NS_ :

BS_:

BU_: AWC BAP_Tester BMC_MLBevo BMS_MV BMS_NV DCDC_800V_PAG DCDC_HV DCDC_HV_02 DCDC_IHEV Gateway Gateway_PAG Ladegeraet_2 Ladegeraet_Konzern LE1 LE2 LE_MLBevo Sub_Gateway TME

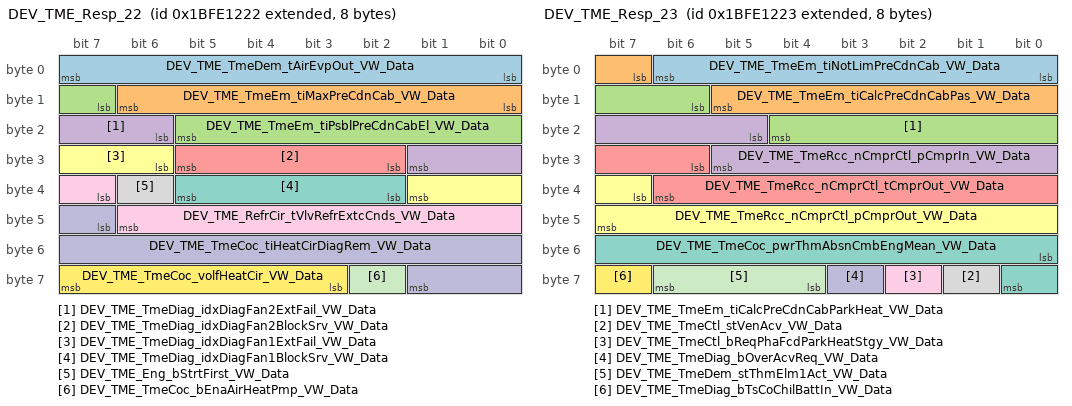
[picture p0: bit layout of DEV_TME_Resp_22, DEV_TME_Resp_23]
BO_ 2617119266 DEV_TME_Resp_22: 8 TME
 SG_ DEV_TME_TmeDem_tAirEvpOut_VW_Data : 0|8@1+ (0.8,-45) [-45|159] "" Vector__XXX
 SG_ DEV_TME_TmeEm_tiMaxPreCdnCab_VW_Data : 8|7@1+ (1,0) [0|120] "" Vector__XXX
 SG_ DEV_TME_TmeEm_tiPsblPreCdnCabEl_VW_Data : 15|7@1+ (1,0) [0|120] "" Vector__XXX
 SG_ DEV_TME_TmeDiag_idxDiagFan2ExtFail_VW_Data : 22|4@1+ (0.17,0) [0|2.55] "" Vector__XXX
 SG_ DEV_TME_TmeDiag_idxDiagFan2BlockSrv_VW_Data : 26|4@1+ (0.17,0) [0|2.55] "" Vector__XXX
 SG_ DEV_TME_TmeDiag_idxDiagFan1ExtFail_VW_Data : 30|4@1+ (0.17,0) [0|2.55] "" Vector__XXX
 SG_ DEV_TME_TmeDiag_idxDiagFan1BlockSrv_VW_Data : 34|4@1+ (0.17,0) [0|2.55] "" Vector__XXX
 SG_ DEV_TME_Eng_bStrtFirst_VW_Data : 38|1@1+ (1,0) [0|1] "" Vector__XXX
 SG_ DEV_TME_RefrCir_tVlvRefrExtcCnds_VW_Data : 39|8@1+ (0.8,-50) [-50|154] "" Vector__XXX
 SG_ DEV_TME_TmeCoc_tiHeatCirDiagRem_VW_Data : 47|11@1+ (1,0) [0|2047] "" Vector__XXX
 SG_ DEV_TME_TmeCoc_bEnaAirHeatPmp_VW_Data : 58|1@1+ (1,0) [0|1] "" Vector__XXX
 SG_ DEV_TME_TmeCoc_volfHeatCir_VW_Data : 59|5@1+ (0.5,0) [0|15.5] "" Vector__XXX

BO_ 2617119267 DEV_TME_Resp_23: 8 TME
 SG_ DEV_TME_TmeEm_tiNotLimPreCdnCab_VW_Data : 0|7@1+ (1,0) [0|120] "" Vector__XXX
 SG_ DEV_TME_TmeEm_tiCalcPreCdnCabPas_VW_Data : 7|7@1+ (1,0) [0|120] "" Vector__XXX
 SG_ DEV_TME_TmeEm_tiCalcPreCdnCabParkHeat_VW_Data : 14|7@1+ (1,0) [0|120] "" Vector__XXX
 SG_ DEV_TME_TmeRcc_nCmprCtl_pCmprIn_VW_Data : 21|9@1+ (32,0) [0|9000] "" Vector__XXX
 SG_ DEV_TME_TmeRcc_nCmprCtl_tCmprOut_VW_Data : 30|9@1+ (32,0) [0|9000] "" Vector__XXX
 SG_ DEV_TME_TmeRcc_nCmprCtl_pCmprOut_VW_Data : 39|9@1+ (32,0) [0|9000] "" Vector__XXX
 SG_ DEV_TME_TmeCoc_pwrThmAbsnCmbEngMean_VW_Data : 48|9@1+ (32,0) [0|16352] "" Vector__XXX
 SG_ DEV_TME_TmeCtl_stVenAcv_VW_Data : 57|1@1+ (1,0) [0|1] "" Vector__XXX
 SG_ DEV_TME_TmeCtl_bReqPhaFcdParkHeatStgy_VW_Data : 58|1@1+ (1,0) [0|1] "" Vector__XXX
 SG_ DEV_TME_TmeDiag_bOverAcvReq_VW_Data : 59|1@1+ (1,0) [0|1] "" Vector__XXX
 SG_ DEV_TME_TmeDem_stThmElm1Act_VW_Data : 60|3@1+ (1,0) [0|7] "" Vector__XXX
 SG_ DEV_TME_TmeDiag_bTsCoChilBattIn_VW_Data : 63|1@1+ (1,0) [0|1] "" Vector__XXX

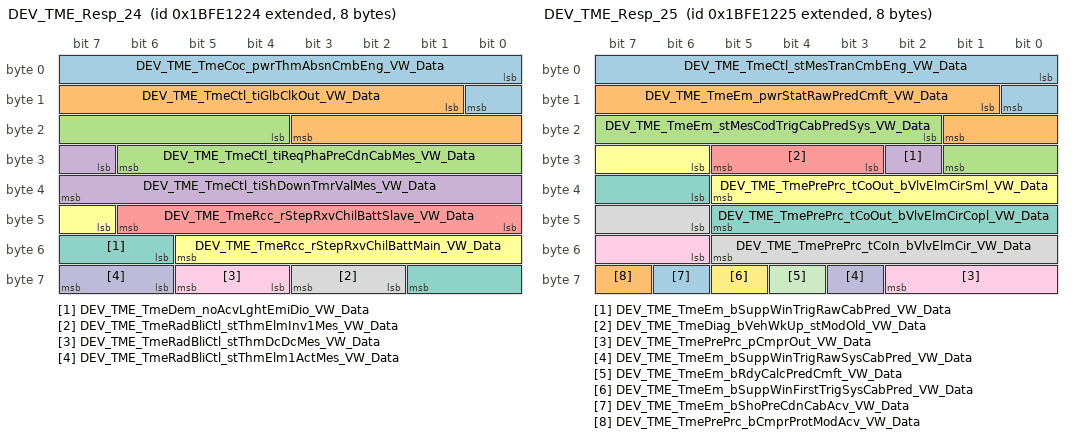
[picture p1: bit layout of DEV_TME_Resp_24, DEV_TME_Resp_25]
BO_ 2617119268 DEV_TME_Resp_24: 8 TME
 SG_ DEV_TME_TmeCoc_pwrThmAbsnCmbEng_VW_Data : 0|9@1+ (32,0) [0|16352] "" Vector__XXX
 SG_ DEV_TME_TmeCtl_tiGlbClkOut_VW_Data : 9|11@1+ (8,0) [0|16376] "" Vector__XXX
 SG_ DEV_TME_TmeCtl_tiReqPhaPreCdnCabMes_VW_Data : 20|11@1+ (8,0) [0|16376] "" Vector__XXX
 SG_ DEV_TME_TmeCtl_tiShDownTmrValMes_VW_Data : 31|9@1+ (8,0) [0|4088] "" Vector__XXX
 SG_ DEV_TME_TmeRcc_rStepRxvChilBattSlave_VW_Data : 40|7@1+ (0.8,0) [0|100] "" Vector__XXX
 SG_ DEV_TME_TmeRcc_rStepRxvChilBattMain_VW_Data : 47|7@1+ (0.8,0) [0|100] "" Vector__XXX
 SG_ DEV_TME_TmeDem_noAcvLghtEmiDio_VW_Data : 54|4@1+ (1,0) [0|8] "" Vector__XXX
 SG_ DEV_TME_TmeRadBliCtl_stThmElmInv1Mes_VW_Data : 58|2@1+ (1,0) [0|3] "" Vector__XXX
 SG_ DEV_TME_TmeRadBliCtl_stThmDcDcMes_VW_Data : 60|2@1+ (1,0) [0|3] "" Vector__XXX
 SG_ DEV_TME_TmeRadBliCtl_stThmElm1ActMes_VW_Data : 62|2@1+ (1,0) [0|3] "" Vector__XXX

BO_ 2617119269 DEV_TME_Resp_25: 8 TME
 SG_ DEV_TME_TmeCtl_stMesTranCmbEng_VW_Data : 0|9@1+ (1,0) [0|511] "" Vector__XXX
 SG_ DEV_TME_TmeEm_pwrStatRawPredCmft_VW_Data : 9|9@1+ (32,0) [0|16352] "" Vector__XXX
 SG_ DEV_TME_TmeEm_stMesCodTrigCabPredSys_VW_Data : 18|8@1+ (1,0) [0|255] "" Vector__XXX
 SG_ DEV_TME_TmeEm_bSuppWinTrigRawCabPred_VW_Data : 26|1@1+ (1,0) [0|1] "" Vector__XXX
 SG_ DEV_TME_TmeDiag_bVehWkUp_stModOld_VW_Data : 27|3@1+ (1,0) [0|7] "" Vector__XXX
 SG_ DEV_TME_TmePrePrc_tCoOut_bVlvElmCirSml_VW_Data : 30|8@1+ (1,-40) [-40|215] "" Vector__XXX
 SG_ DEV_TME_TmePrePrc_tCoOut_bVlvElmCirCopl_VW_Data : 38|8@1+ (1,-40) [-40|215] "" Vector__XXX
 SG_ DEV_TME_TmePrePrc_tCoIn_bVlvElmCir_VW_Data : 46|8@1+ (1,-40) [-40|215] "" Vector__XXX
 SG_ DEV_TME_TmePrePrc_pCmprOut_VW_Data : 54|5@1+ (1,0) [0|31] "" Vector__XXX
 SG_ DEV_TME_TmeEm_bSuppWinTrigRawSysCabPred_VW_Data : 59|1@1+ (1,0) [0|1] "" Vector__XXX
 SG_ DEV_TME_TmeEm_bRdyCalcPredCmft_VW_Data : 60|1@1+ (1,0) [0|1] "" Vector__XXX
 SG_ DEV_TME_TmeEm_bSuppWinFirstTrigSysCabPred_VW_Data : 61|1@1+ (1,0) [0|1] "" Vector__XXX
 SG_ DEV_TME_TmeEm_bShoPreCdnCabAcv_VW_Data : 62|1@1+ (1,0) [0|1] "" Vector__XXX
 SG_ DEV_TME_TmePrePrc_bCmprProtModAcv_VW_Data : 63|1@1+ (1,0) [0|1] "" Vector__XXX

BO_ 2617119270 DEV_TME_Resp_26: 8 TME
 SG_ DEV_TME_TmeEcu_stCodPar5_VW_Data : 0|32@1+ (1,0) [0|4294967295] "" Vector__XXX
 SG_ DEV_TME_TmeEcu_stCodPar4_VW_Data : 32|32@1+ (1,0) [0|4294967295] "" Vector__XXX

BO_ 2617119271 DEV_TME_Resp_27: 8 TME
 SG_ DEV_TME_TmeEcu_stCodPar1_VW_Data : 0|32@1+ (1,0) [0|4294967295] "" Vector__XXX
 SG_ DEV_TME_TmeEcu_stCodPar2_VW_Data : 32|32@1+ (1,0) [0|4294967295] "" Vector__XXX

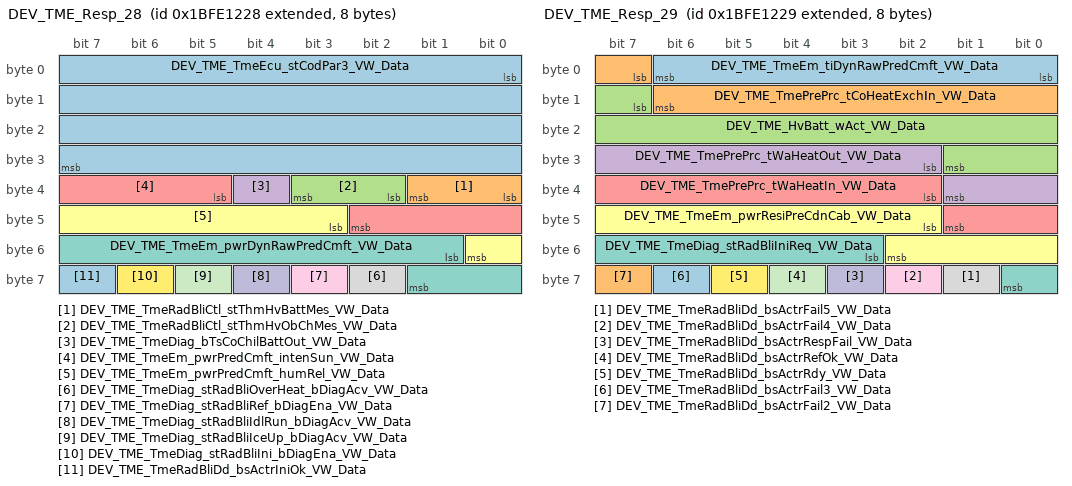
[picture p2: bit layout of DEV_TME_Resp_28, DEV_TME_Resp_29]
BO_ 2617119272 DEV_TME_Resp_28: 8 TME
 SG_ DEV_TME_TmeEcu_stCodPar3_VW_Data : 0|32@1+ (1,0) [0|4294967295] "" Vector__XXX
 SG_ DEV_TME_TmeRadBliCtl_stThmHvBattMes_VW_Data : 32|2@1+ (1,0) [0|3] "" Vector__XXX
 SG_ DEV_TME_TmeRadBliCtl_stThmHvObChMes_VW_Data : 34|2@1+ (1,0) [0|3] "" Vector__XXX
 SG_ DEV_TME_TmeDiag_bTsCoChilBattOut_VW_Data : 36|1@1+ (1,0) [0|1] "" Vector__XXX
 SG_ DEV_TME_TmeEm_pwrPredCmft_intenSun_VW_Data : 37|6@1+ (100,-3200) [-3200|3100] "" Vector__XXX
 SG_ DEV_TME_TmeEm_pwrPredCmft_humRel_VW_Data : 43|6@1+ (100,-3200) [-3200|3100] "" Vector__XXX
 SG_ DEV_TME_TmeEm_pwrDynRawPredCmft_VW_Data : 49|9@1+ (32,0) [0|16352] "" Vector__XXX
 SG_ DEV_TME_TmeDiag_stRadBliOverHeat_bDiagAcv_VW_Data : 58|1@1+ (1,0) [0|1] "" Vector__XXX
 SG_ DEV_TME_TmeDiag_stRadBliRef_bDiagEna_VW_Data : 59|1@1+ (1,0) [0|1] "" Vector__XXX
 SG_ DEV_TME_TmeDiag_stRadBliIdlRun_bDiagAcv_VW_Data : 60|1@1+ (1,0) [0|1] "" Vector__XXX
 SG_ DEV_TME_TmeDiag_stRadBliIceUp_bDiagAcv_VW_Data : 61|1@1+ (1,0) [0|1] "" Vector__XXX
 SG_ DEV_TME_TmeDiag_stRadBliIni_bDiagEna_VW_Data : 62|1@1+ (1,0) [0|1] "" Vector__XXX
 SG_ DEV_TME_TmeRadBliDd_bsActrIniOk_VW_Data : 63|1@1+ (1,0) [0|1] "" Vector__XXX

BO_ 2617119273 DEV_TME_Resp_29: 8 TME
 SG_ DEV_TME_TmeEm_tiDynRawPredCmft_VW_Data : 0|7@1+ (1,0) [0|120] "" Vector__XXX
 SG_ DEV_TME_TmePrePrc_tCoHeatExchIn_VW_Data : 7|8@1+ (1,-40) [-40|215] "" Vector__XXX
 SG_ DEV_TME_HvBatt_wAct_VW_Data : 15|11@1+ (50,0) [0|51200] "" Vector__XXX
 SG_ DEV_TME_TmePrePrc_tWaHeatOut_VW_Data : 26|8@1+ (1,-40) [-40|215] "" Vector__XXX
 SG_ DEV_TME_TmePrePrc_tWaHeatIn_VW_Data : 34|8@1+ (1,-40) [-40|215] "" Vector__XXX
 SG_ DEV_TME_TmeEm_pwrResiPreCdnCab_VW_Data : 42|9@1+ (32,0) [0|16352] "" Vector__XXX
 SG_ DEV_TME_TmeDiag_stRadBliIniReq_VW_Data : 51|6@1+ (1,0) [0|32] "" Vector__XXX
 SG_ DEV_TME_TmeRadBliDd_bsActrFail5_VW_Data : 57|1@1+ (1,0) [0|1] "" Vector__XXX
 SG_ DEV_TME_TmeRadBliDd_bsActrFail4_VW_Data : 58|1@1+ (1,0) [0|1] "" Vector__XXX
 SG_ DEV_TME_TmeRadBliDd_bsActrRespFail_VW_Data : 59|1@1+ (1,0) [0|1] "" Vector__XXX
 SG_ DEV_TME_TmeRadBliDd_bsActrRefOk_VW_Data : 60|1@1+ (1,0) [0|1] "" Vector__XXX
 SG_ DEV_TME_TmeRadBliDd_bsActrRdy_VW_Data : 61|1@1+ (1,0) [0|1] "" Vector__XXX
 SG_ DEV_TME_TmeRadBliDd_bsActrFail3_VW_Data : 62|1@1+ (1,0) [0|1] "" Vector__XXX
 SG_ DEV_TME_TmeRadBliDd_bsActrFail2_VW_Data : 63|1@1+ (1,0) [0|1] "" Vector__XXX

BO_ 2617119274 DEV_TME_Resp_2A: 8 TME
 SG_ DEV_TME_TmeRadBliDd_bsActrFail1_VW_Data : 0|1@1+ (1,0) [0|1] "" Vector__XXX
 SG_ DEV_TME_TmeRadBliDd_rRadBliSet1_VW_Data : 1|7@1+ (1,0) [0|127] "" Vector__XXX
 SG_ DEV_TME_TmeRadBliDd_rRadBliAct1_VW_Data : 8|7@1+ (1,0) [0|127] "" Vector__XXX
 SG_ DEV_TME_TmeDiag_stRadBliSpd2_bDiagAcv_VW_Data : 15|1@1+ (1,0) [0|1] "" Vector__XXX
 SG_ DEV_TME_TmeDiag_stRadBliRefReq_VW_Data : 16|6@1+ (1,0) [0|32] "" Vector__XXX
 SG_ DEV_TME_TmeDiag_stRadBliSpd1_bDiagAcv_VW_Data : 22|1@1+ (1,0) [0|1] "" Vector__XXX
 SG_ DEV_TME_TmeDiag_stRadBliBlock_bDiagAcv_VW_Data : 23|1@1+ (1,0) [0|1] "" Vector__XXX
 SG_ DEV_TME_TmeDiag_stRadBliBlock_bDiagEna_VW_Data : 24|1@1+ (1,0) [0|1] "" Vector__XXX
 SG_ DEV_TME_TmeDiag_stRadBliHealRun_b1FailVld_VW_Data : 25|1@1+ (1,0) [0|1] "" Vector__XXX
 SG_ DEV_TME_TmeDiag_stRadBliHealRun_b1FailSusp_VW_Data : 26|1@1+ (1,0) [0|1] "" Vector__XXX
 SG_ DEV_TME_TmeDiag_stRadBliAlv_bDiagEna_VW_Data : 27|1@1+ (1,0) [0|1] "" Vector__XXX
 SG_ DEV_TME_TmeDiag_stRadBliHealRun_bRef1FailSusp_VW_Data : 28|1@1+ (1,0) [0|1] "" Vector__XXX
 SG_ DEV_TME_Eng_bHotLmp_VW_Data : 29|1@1+ (1,0) [0|1] "" Vector__XXX
 SG_ DEV_TME_TmeDiag_stRadBliHealRun_ct_VW_Data : 30|4@1+ (1,0) [0|10] "" Vector__XXX
 SG_ DEV_TME_TmeDiag_stRadBliHealRun_b1RefFailVld_VW_Data : 34|1@1+ (1,0) [0|1] "" Vector__XXX
 SG_ DEV_TME_TmeRadBliCtl_stThmElm1RtMes_VW_Data : 35|2@1+ (1,0) [0|3] "" Vector__XXX
 SG_ DEV_TME_TmeEm_pwrDeltaThdSysHld_VW_Data : 37|7@1+ (100,0) [0|12700] "" Vector__XXX
 SG_ DEV_TME_TmeEm_pwrStatPredCmftFilHld_VW_Data : 44|7@1+ (100,0) [0|12700] "" Vector__XXX
 SG_ DEV_TME_TmeEm_pwrStatPredCmftFilSysHld_VW_Data : 51|7@1+ (100,0) [0|12700] "" Vector__XXX
 SG_ DEV_TME_TmeDiag_bHvBattModAcv_VW_Data : 58|1@1+ (1,0) [0|1] "" Vector__XXX
 SG_ DEV_TME_TmeDiag_idxDiagTsHeatExchIn_VW_Data : 59|4@1+ (17,0) [0|2.55] "" Vector__XXX
 SG_ DEV_TME_TmeEm_bSigVldPreCdnCabMes_VW_Data : 63|1@1+ (1,0) [0|1] "" Vector__XXX

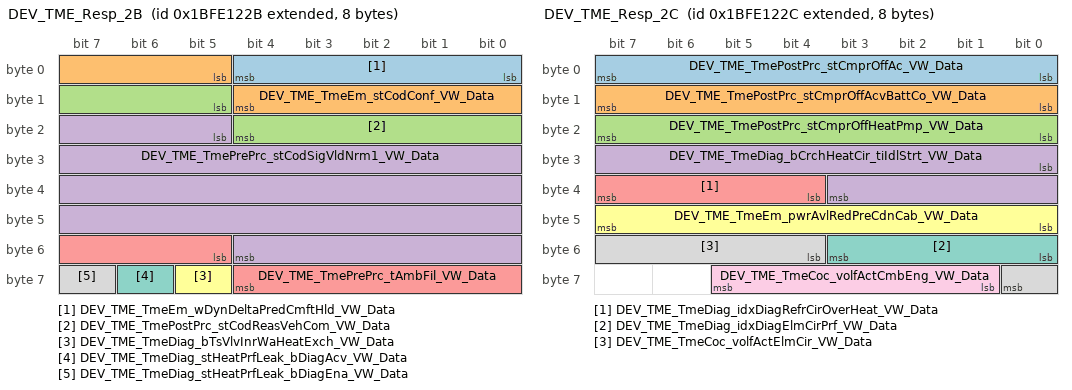
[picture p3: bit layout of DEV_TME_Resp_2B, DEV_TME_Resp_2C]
BO_ 2617119275 DEV_TME_Resp_2B: 8 TME
 SG_ DEV_TME_TmeEm_wDynDeltaPredCmftHld_VW_Data : 0|5@1+ (200,0) [0|6000] "" Vector__XXX
 SG_ DEV_TME_TmeEm_stCodConf_VW_Data : 5|8@1+ (1,0) [0|255] "" Vector__XXX
 SG_ DEV_TME_TmePostPrc_stCodReasVehCom_VW_Data : 13|8@1+ (1,0) [0|255] "" Vector__XXX
 SG_ DEV_TME_TmePrePrc_stCodSigVldNrm1_VW_Data : 21|32@1+ (1,0) [0|4294967295] "" Vector__XXX
 SG_ DEV_TME_TmePrePrc_tAmbFil_VW_Data : 53|8@1+ (1,-40) [-40|215] "" Vector__XXX
 SG_ DEV_TME_TmeDiag_bTsVlvInrWaHeatExch_VW_Data : 61|1@1+ (1,0) [0|1] "" Vector__XXX
 SG_ DEV_TME_TmeDiag_stHeatPrfLeak_bDiagAcv_VW_Data : 62|1@1+ (1,0) [0|1] "" Vector__XXX
 SG_ DEV_TME_TmeDiag_stHeatPrfLeak_bDiagEna_VW_Data : 63|1@1+ (1,0) [0|1] "" Vector__XXX

BO_ 2617119276 DEV_TME_Resp_2C: 8 TME
 SG_ DEV_TME_TmePostPrc_stCmprOffAc_VW_Data : 0|8@1+ (1,0) [0|255] "" Vector__XXX
 SG_ DEV_TME_TmePostPrc_stCmprOffAcvBattCo_VW_Data : 8|8@1+ (1,0) [0|255] "" Vector__XXX
 SG_ DEV_TME_TmePostPrc_stCmprOffHeatPmp_VW_Data : 16|8@1+ (1,0) [0|255] "" Vector__XXX
 SG_ DEV_TME_TmeDiag_bCrchHeatCir_tiIdlStrt_VW_Data : 24|12@1+ (1,0) [0|3000] "" Vector__XXX
 SG_ DEV_TME_TmeDiag_idxDiagRefrCirOverHeat_VW_Data : 36|4@1+ (17,0) [0|2.55] "" Vector__XXX
 SG_ DEV_TME_TmeEm_pwrAvlRedPreCdnCab_VW_Data : 40|8@1+ (50,0) [0|12750] "" Vector__XXX
 SG_ DEV_TME_TmeDiag_idxDiagElmCirPrf_VW_Data : 48|4@1+ (0.17,0) [0|2.55] "" Vector__XXX
 SG_ DEV_TME_TmeCoc_volfActElmCir_VW_Data : 52|5@1+ (0.5,0) [0|15.5] "" Vector__XXX
 SG_ DEV_TME_TmeCoc_volfActCmbEng_VW_Data : 57|5@1+ (0.5,0) [0|15.5] "" Vector__XXX

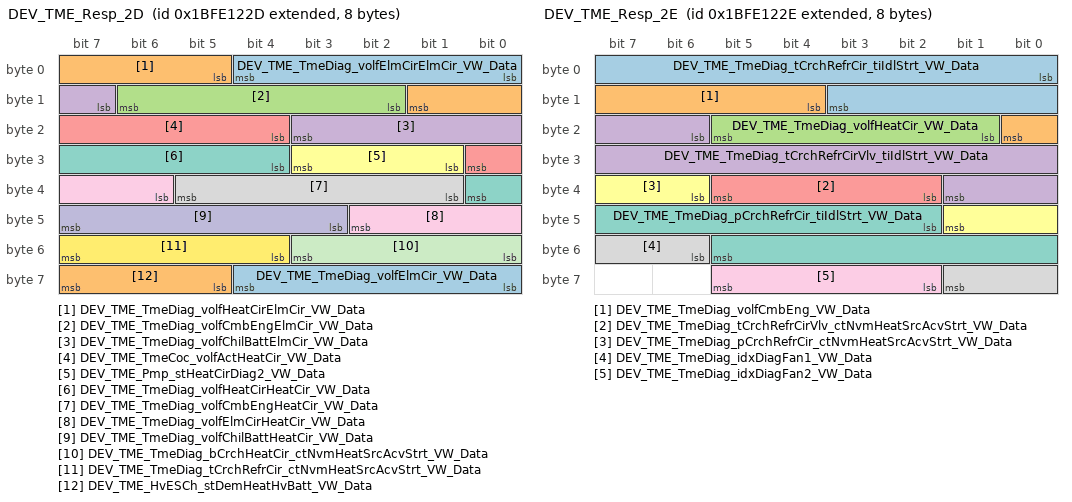
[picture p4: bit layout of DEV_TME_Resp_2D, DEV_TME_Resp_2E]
BO_ 2617119277 DEV_TME_Resp_2D: 8 TME
 SG_ DEV_TME_TmeDiag_volfElmCirElmCir_VW_Data : 0|5@1+ (0.5,0) [0|15.5] "" Vector__XXX
 SG_ DEV_TME_TmeDiag_volfHeatCirElmCir_VW_Data : 5|5@1+ (0.5,0) [0|15.5] "" Vector__XXX
 SG_ DEV_TME_TmeDiag_volfCmbEngElmCir_VW_Data : 10|5@1+ (0.5,0) [0|15.5] "" Vector__XXX
 SG_ DEV_TME_TmeDiag_volfChilBattElmCir_VW_Data : 15|5@1+ (0.5,0) [0|15.5] "" Vector__XXX
 SG_ DEV_TME_TmeCoc_volfActHeatCir_VW_Data : 20|5@1+ (0.5,0) [0|15.5] "" Vector__XXX
 SG_ DEV_TME_Pmp_stHeatCirDiag2_VW_Data : 25|3@1+ (1,0) [0|7] "" Vector__XXX
 SG_ DEV_TME_TmeDiag_volfHeatCirHeatCir_VW_Data : 28|5@1+ (0.5,0) [0|15.5] "" Vector__XXX
 SG_ DEV_TME_TmeDiag_volfCmbEngHeatCir_VW_Data : 33|5@1+ (0.5,0) [0|15.5] "" Vector__XXX
 SG_ DEV_TME_TmeDiag_volfElmCirHeatCir_VW_Data : 38|5@1+ (0.5,0) [0|15.5] "" Vector__XXX
 SG_ DEV_TME_TmeDiag_volfChilBattHeatCir_VW_Data : 43|5@1+ (0.5,0) [0|15.5] "" Vector__XXX
 SG_ DEV_TME_TmeDiag_bCrchHeatCir_ctNvmHeatSrcAcvStrt_VW_Data : 48|4@1+ (1,0) [0|10] "" Vector__XXX
 SG_ DEV_TME_TmeDiag_tCrchRefrCir_ctNvmHeatSrcAcvStrt_VW_Data : 52|4@1+ (1,0) [0|10] "" Vector__XXX
 SG_ DEV_TME_TmeDiag_volfElmCir_VW_Data : 56|5@1+ (0.5,0) [0|15.5] "" Vector__XXX
 SG_ DEV_TME_HvESCh_stDemHeatHvBatt_VW_Data : 61|3@1+ (1,0) [0|7] "" Vector__XXX

BO_ 2617119278 DEV_TME_Resp_2E: 8 TME
 SG_ DEV_TME_TmeDiag_tCrchRefrCir_tiIdlStrt_VW_Data : 0|12@1+ (1,0) [0|3000] "" Vector__XXX
 SG_ DEV_TME_TmeDiag_volfCmbEng_VW_Data : 12|5@1+ (0.5,0) [0|15.5] "" Vector__XXX
 SG_ DEV_TME_TmeDiag_volfHeatCir_VW_Data : 17|5@1+ (0.5,0) [0|15.5] "" Vector__XXX
 SG_ DEV_TME_TmeDiag_tCrchRefrCirVlv_tiIdlStrt_VW_Data : 22|12@1+ (1,0) [0|3000] "" Vector__XXX
 SG_ DEV_TME_TmeDiag_tCrchRefrCirVlv_ctNvmHeatSrcAcvStrt_VW_Data : 34|4@1+ (1,0) [0|10] "" Vector__XXX
 SG_ DEV_TME_TmeDiag_pCrchRefrCir_ctNvmHeatSrcAcvStrt_VW_Data : 38|4@1+ (1,0) [0|10] "" Vector__XXX
 SG_ DEV_TME_TmeDiag_pCrchRefrCir_tiIdlStrt_VW_Data : 42|12@1+ (1,0) [0|3000] "" Vector__XXX
 SG_ DEV_TME_TmeDiag_idxDiagFan1_VW_Data : 54|4@1+ (0.17,0) [0|2.55] "" Vector__XXX
 SG_ DEV_TME_TmeDiag_idxDiagFan2_VW_Data : 58|4@1+ (0.17,0) [0|2.55] "" Vector__XXX

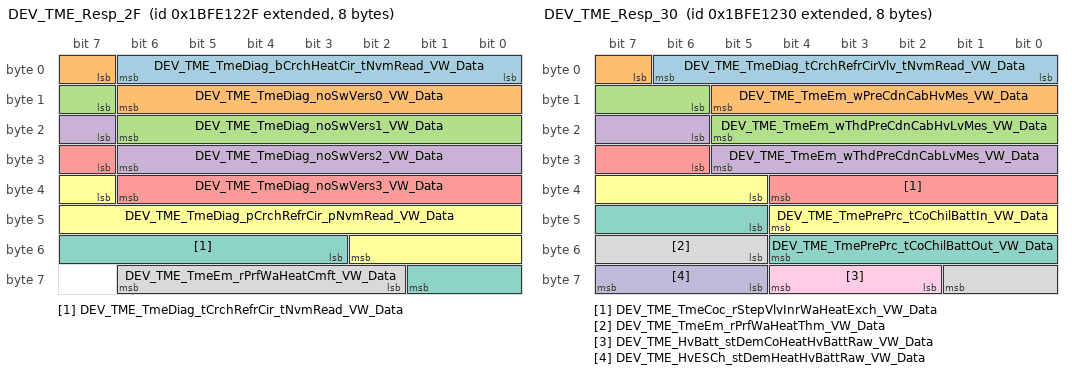
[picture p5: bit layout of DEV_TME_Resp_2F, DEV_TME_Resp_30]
BO_ 2617119279 DEV_TME_Resp_2F: 8 TME
 SG_ DEV_TME_TmeDiag_bCrchHeatCir_tNvmRead_VW_Data : 0|7@1+ (1,0) [0|127] "" Vector__XXX
 SG_ DEV_TME_TmeDiag_noSwVers0_VW_Data : 7|8@1+ (1,0) [0|255] "" Vector__XXX
 SG_ DEV_TME_TmeDiag_noSwVers1_VW_Data : 15|8@1+ (1,0) [0|255] "" Vector__XXX
 SG_ DEV_TME_TmeDiag_noSwVers2_VW_Data : 23|8@1+ (1,0) [0|255] "" Vector__XXX
 SG_ DEV_TME_TmeDiag_noSwVers3_VW_Data : 31|8@1+ (1,0) [0|255] "" Vector__XXX
 SG_ DEV_TME_TmeDiag_pCrchRefrCir_pNvmRead_VW_Data : 39|12@1+ (0.015625,0) [0|40] "" Vector__XXX
 SG_ DEV_TME_TmeDiag_tCrchRefrCir_tNvmRead_VW_Data : 51|7@1+ (1,0) [0|127] "" Vector__XXX
 SG_ DEV_TME_TmeEm_rPrfWaHeatCmft_VW_Data : 58|5@1+ (0.05,0) [0|1] "" Vector__XXX

BO_ 2617119280 DEV_TME_Resp_30: 8 TME
 SG_ DEV_TME_TmeDiag_tCrchRefrCirVlv_tNvmRead_VW_Data : 0|7@1+ (1,0) [0|127] "" Vector__XXX
 SG_ DEV_TME_TmeEm_wPreCdnCabHvMes_VW_Data : 7|7@1+ (10,0) [0|1000] "" Vector__XXX
 SG_ DEV_TME_TmeEm_wThdPreCdnCabHvLvMes_VW_Data : 14|8@1+ (10,0) [0|2000] "" Vector__XXX
 SG_ DEV_TME_TmeEm_wThdPreCdnCabLvMes_VW_Data : 22|8@1+ (10,0) [0|2000] "" Vector__XXX
 SG_ DEV_TME_TmeCoc_rStepVlvInrWaHeatExch_VW_Data : 30|7@1+ (1,0) [0|100] "" Vector__XXX
 SG_ DEV_TME_TmePrePrc_tCoChilBattIn_VW_Data : 37|8@1+ (1,-40) [-40|215] "" Vector__XXX
 SG_ DEV_TME_TmePrePrc_tCoChilBattOut_VW_Data : 45|8@1+ (1,-40) [-40|215] "" Vector__XXX
 SG_ DEV_TME_TmeEm_rPrfWaHeatThm_VW_Data : 53|5@1+ (0.05,0) [0|1] "" Vector__XXX
 SG_ DEV_TME_HvBatt_stDemCoHeatHvBattRaw_VW_Data : 58|3@1+ (1,0) [0|7] "" Vector__XXX
 SG_ DEV_TME_HvESCh_stDemHeatHvBattRaw_VW_Data : 61|3@1+ (1,0) [0|7] "" Vector__XXX

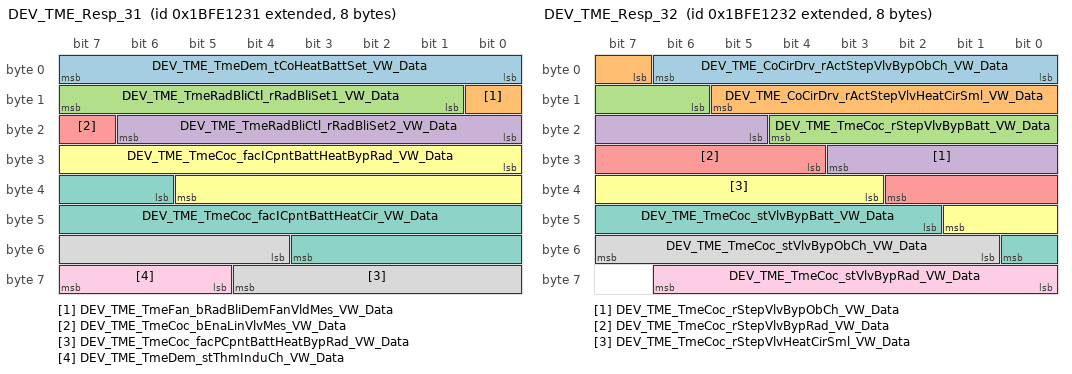
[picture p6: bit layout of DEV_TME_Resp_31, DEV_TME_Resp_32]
BO_ 2617119281 DEV_TME_Resp_31: 8 TME
 SG_ DEV_TME_TmeDem_tCoHeatBattSet_VW_Data : 0|8@1+ (0.8,-50) [-50|154] "" Vector__XXX
 SG_ DEV_TME_TmeFan_bRadBliDemFanVldMes_VW_Data : 8|1@1+ (1,0) [0|1] "" Vector__XXX
 SG_ DEV_TME_TmeRadBliCtl_rRadBliSet1_VW_Data : 9|7@1+ (1,0) [0|100] "" Vector__XXX
 SG_ DEV_TME_TmeRadBliCtl_rRadBliSet2_VW_Data : 16|7@1+ (1,0) [0|100] "" Vector__XXX
 SG_ DEV_TME_TmeCoc_bEnaLinVlvMes_VW_Data : 23|1@1+ (1,0) [0|1] "" Vector__XXX
 SG_ DEV_TME_TmeCoc_facICpntBattHeatBypRad_VW_Data : 24|14@1+ (0.0001,0) [0|0.1] "" Vector__XXX
 SG_ DEV_TME_TmeCoc_facICpntBattHeatCir_VW_Data : 38|14@1+ (0.0001,0) [0|0.1] "" Vector__XXX
 SG_ DEV_TME_TmeCoc_facPCpntBattHeatBypRad_VW_Data : 52|9@1+ (0.01,0) [0|2] "" Vector__XXX
 SG_ DEV_TME_TmeDem_stThmInduCh_VW_Data : 61|3@1+ (1,0) [0|4] "" Vector__XXX

BO_ 2617119282 DEV_TME_Resp_32: 8 TME
 SG_ DEV_TME_CoCirDrv_rActStepVlvBypObCh_VW_Data : 0|7@1+ (1,0) [0|100] "" Vector__XXX
 SG_ DEV_TME_CoCirDrv_rActStepVlvHeatCirSml_VW_Data : 7|7@1+ (1,0) [0|100] "" Vector__XXX
 SG_ DEV_TME_TmeCoc_rStepVlvBypBatt_VW_Data : 14|7@1+ (1,0) [0|100] "" Vector__XXX
 SG_ DEV_TME_TmeCoc_rStepVlvBypObCh_VW_Data : 21|7@1+ (1,0) [0|100] "" Vector__XXX
 SG_ DEV_TME_TmeCoc_rStepVlvBypRad_VW_Data : 28|7@1+ (1,0) [0|100] "" Vector__XXX
 SG_ DEV_TME_TmeCoc_rStepVlvHeatCirSml_VW_Data : 35|7@1+ (1,0) [0|100] "" Vector__XXX
 SG_ DEV_TME_TmeCoc_stVlvBypBatt_VW_Data : 42|7@1+ (1,0) [0|127] "" Vector__XXX
 SG_ DEV_TME_TmeCoc_stVlvBypObCh_VW_Data : 49|7@1+ (1,0) [0|127] "" Vector__XXX
 SG_ DEV_TME_TmeCoc_stVlvBypRad_VW_Data : 56|7@1+ (1,0) [0|127] "" Vector__XXX

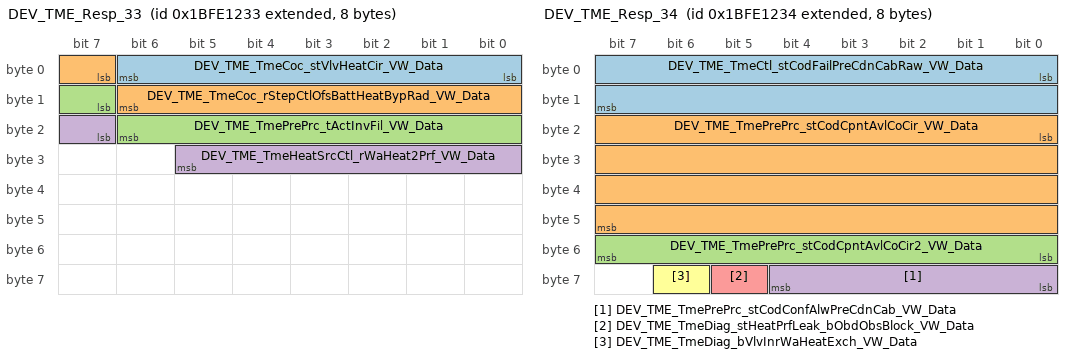
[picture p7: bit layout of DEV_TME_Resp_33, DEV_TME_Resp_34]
BO_ 2617119283 DEV_TME_Resp_33: 8 TME
 SG_ DEV_TME_TmeCoc_stVlvHeatCir_VW_Data : 0|7@1+ (1,0) [0|127] "" Vector__XXX
 SG_ DEV_TME_TmeCoc_rStepCtlOfsBattHeatBypRad_VW_Data : 7|8@1+ (1,-100) [-100|100] "" Vector__XXX
 SG_ DEV_TME_TmePrePrc_tActInvFil_VW_Data : 15|8@1+ (0.8,-45) [-45|159] "" Vector__XXX
 SG_ DEV_TME_TmeHeatSrcCtl_rWaHeat2Prf_VW_Data : 23|7@1+ (1,0) [0|100] "" Vector__XXX

BO_ 2617119284 DEV_TME_Resp_34: 8 TME
 SG_ DEV_TME_TmeCtl_stCodFailPreCdnCabRaw_VW_Data : 0|16@1+ (1,0) [0|65535] "" Vector__XXX
 SG_ DEV_TME_TmePrePrc_stCodCpntAvlCoCir_VW_Data : 16|32@1+ (1,0) [0|4294967295] "" Vector__XXX
 SG_ DEV_TME_TmePrePrc_stCodCpntAvlCoCir2_VW_Data : 48|8@1+ (1,0) [0|255] "" Vector__XXX
 SG_ DEV_TME_TmePrePrc_stCodConfAlwPreCdnCab_VW_Data : 56|5@1+ (1,0) [0|31] "" Vector__XXX
 SG_ DEV_TME_TmeDiag_stHeatPrfLeak_bObdObsBlock_VW_Data : 61|1@1+ (1,0) [0|1] "" Vector__XXX
 SG_ DEV_TME_TmeDiag_bVlvInrWaHeatExch_VW_Data : 62|1@1+ (1,0) [0|1] "" Vector__XXX

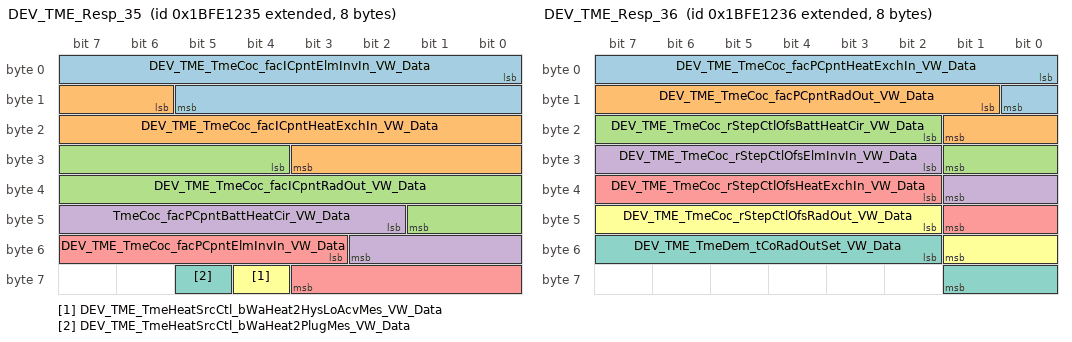
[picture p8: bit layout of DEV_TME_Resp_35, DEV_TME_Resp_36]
BO_ 2617119285 DEV_TME_Resp_35: 8 TME
 SG_ DEV_TME_TmeCoc_facICpntElmInvIn_VW_Data : 0|14@1+ (0.0001,0) [0|0.1] "" Vector__XXX
 SG_ DEV_TME_TmeCoc_facICpntHeatExchIn_VW_Data : 14|14@1+ (0.0001,0) [0|0.1] "" Vector__XXX
 SG_ DEV_TME_TmeCoc_facICpntRadOut_VW_Data : 28|14@1+ (0.0001,0) [0|0.1] "" Vector__XXX
 SG_ TmeCoc_facPCpntBattHeatCir_VW_Data : 42|9@1+ (0.01,0) [0|2] "" Vector__XXX
 SG_ DEV_TME_TmeCoc_facPCpntElmInvIn_VW_Data : 51|9@1+ (0.01,0) [0|2] "" Vector__XXX
 SG_ DEV_TME_TmeHeatSrcCtl_bWaHeat2HysLoAcvMes_VW_Data : 60|1@1+ (1,0) [0|1] "" Vector__XXX
 SG_ DEV_TME_TmeHeatSrcCtl_bWaHeat2PlugMes_VW_Data : 61|1@1+ (1,0) [0|1] "" Vector__XXX

BO_ 2617119286 DEV_TME_Resp_36: 8 TME
 SG_ DEV_TME_TmeCoc_facPCpntHeatExchIn_VW_Data : 0|9@1+ (0.01,0) [0|2] "" Vector__XXX
 SG_ DEV_TME_TmeCoc_facPCpntRadOut_VW_Data : 9|9@1+ (0.01,0) [0|2] "" Vector__XXX
 SG_ DEV_TME_TmeCoc_rStepCtlOfsBattHeatCir_VW_Data : 18|8@1+ (1,-100) [-100|100] "" Vector__XXX
 SG_ DEV_TME_TmeCoc_rStepCtlOfsElmInvIn_VW_Data : 26|8@1+ (1,-100) [-100|100] "" Vector__XXX
 SG_ DEV_TME_TmeCoc_rStepCtlOfsHeatExchIn_VW_Data : 34|8@1+ (1,-100) [-100|100] "" Vector__XXX
 SG_ DEV_TME_TmeCoc_rStepCtlOfsRadOut_VW_Data : 42|8@1+ (1,-100) [-100|100] "" Vector__XXX
 SG_ DEV_TME_TmeDem_tCoRadOutSet_VW_Data : 50|8@1+ (0.8,-50) [-50|154] "" Vector__XXX

BO_ 2617119287 DEV_TME_Resp_37: 8 TME
 SG_ DEV_TME_TmePrePrc_stCodSigVld1_VW_Data : 0|32@1+ (1,0) [0|4294967295] "" Vector__XXX
 SG_ DEV_TME_TmePrePrc_stCodSigVld2_VW_Data : 32|32@1+ (1,0) [0|4294967295] "" Vector__XXX

BO_ 2617119288 DEV_TME_Resp_38: 8 TME
 SG_ DEV_TME_TmePrePrc_stCodConfAlw_VW_Data : 0|32@1+ (1,0) [0|4294967295] "" Vector__XXX
 SG_ DEV_TME_TmePrePrc_stCodCpntAvlRefrCir_VW_Data : 32|32@1+ (1,0) [0|4294967295] "" Vector__XXX

BO_ 2617119289 DEV_TME_Resp_39: 8 TME
 SG_ DEV_TME_TmePrePrc_stCodSigVld4_VW_Data : 0|32@1+ (1,0) [0|4294967295] "" Vector__XXX
 SG_ DEV_TME_TmePrePrc_stCodDiagAlw_VW_Data : 32|32@1+ (1,0) [0|4294967295] "" Vector__XXX

BO_ 2617119290 DEV_TME_Resp_3A: 8 TME
 SG_ DEV_TME_TmePrePrc_stCodSigVld3_VW_Data : 0|32@1+ (1,0) [0|4294967295] "" Vector__XXX
 SG_ DEV_TME_TmeCtl_stOpmPartLdIdc_VW_Data : 32|4@1+ (1,0) [0|15] "" Vector__XXX

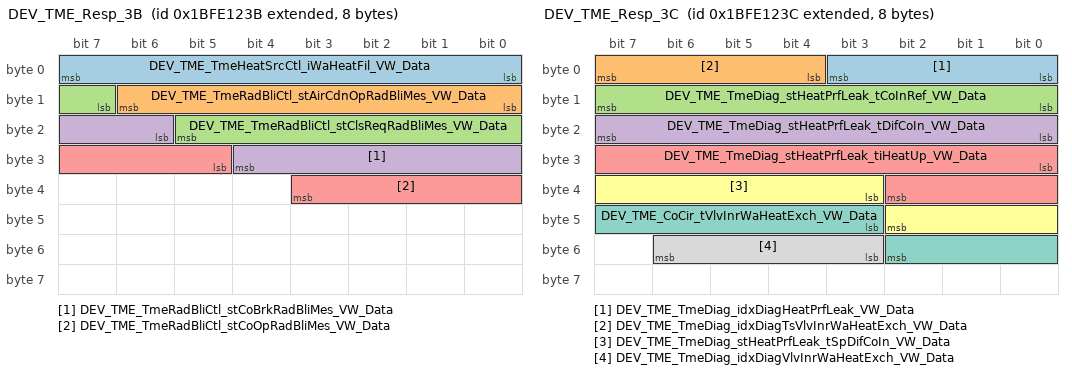
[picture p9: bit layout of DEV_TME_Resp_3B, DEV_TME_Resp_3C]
BO_ 2617119291 DEV_TME_Resp_3B: 8 TME
 SG_ DEV_TME_TmeHeatSrcCtl_iWaHeatFil_VW_Data : 0|8@1+ (0.5,0) [0|63.2] "" Vector__XXX
 SG_ DEV_TME_TmeRadBliCtl_stAirCdnOpRadBliMes_VW_Data : 8|7@1+ (1,0) [0|100] "" Vector__XXX
 SG_ DEV_TME_TmeRadBliCtl_stClsReqRadBliMes_VW_Data : 15|7@1+ (1,0) [0|100] "" Vector__XXX
 SG_ DEV_TME_TmeRadBliCtl_stCoBrkRadBliMes_VW_Data : 22|7@1+ (1,0) [0|100] "" Vector__XXX
 SG_ DEV_TME_TmeRadBliCtl_stCoOpRadBliMes_VW_Data : 29|7@1+ (1,0) [0|100] "" Vector__XXX

BO_ 2617119292 DEV_TME_Resp_3C: 8 TME
 SG_ DEV_TME_TmeDiag_idxDiagHeatPrfLeak_VW_Data : 0|4@1+ (0.17,0) [0|2.55] "" Vector__XXX
 SG_ DEV_TME_TmeDiag_idxDiagTsVlvInrWaHeatExch_VW_Data : 4|4@1+ (0.17,0) [0|2.55] "" Vector__XXX
 SG_ DEV_TME_TmeDiag_stHeatPrfLeak_tCoInRef_VW_Data : 8|8@1+ (0.8,-50) [-50|154] "" Vector__XXX
 SG_ DEV_TME_TmeDiag_stHeatPrfLeak_tDifCoIn_VW_Data : 16|8@1+ (0.8,-50) [-50|154] "" Vector__XXX
 SG_ DEV_TME_TmeDiag_stHeatPrfLeak_tiHeatUp_VW_Data : 24|11@1+ (1,0) [0|2047] "" Vector__XXX
 SG_ DEV_TME_TmeDiag_stHeatPrfLeak_tSpDifCoIn_VW_Data : 35|8@1+ (0.8,-50) [-50|154] "" Vector__XXX
 SG_ DEV_TME_CoCir_tVlvInrWaHeatExch_VW_Data : 43|8@1+ (0.8,-45) [-45|159] "" Vector__XXX
 SG_ DEV_TME_TmeDiag_idxDiagVlvInrWaHeatExch_VW_Data : 51|4@1+ (0.17,0) [0|2.55] "" Vector__XXX

BO_ 2617119487 DEV_TME_Resp_FF: 8 TME
 SG_ DEV_TME_Resp_FF_Data : 0|64@1+ (1.0,0.0) [0.0|18446744073709551615] ""  Vector__XXX

BO_ 2549880528 DIA_BJB_Req: 8 Gateway
 SG_ DIA_BJB_Req_Data : 0|64@1+ (1.0,0.0) [0.0|18446744073709551615] ""  BMC_MLBevo

BO_ 2550011600 DIA_BJB_Resp: 8 BMC_MLBevo
 SG_ DIA_BJB_Resp_Data : 0|64@1+ (1.0,0.0) [0.0|18446744073709551615] ""  Gateway,Gateway_PAG

BO_ 2549880529 DIA_CMC_01_Req: 8 Gateway
 SG_ DIA_CMC_01_Req_Data : 0|64@1+ (1.0,0.0) [0.0|18446744073709551615] ""  BMC_MLBevo

BO_ 2550011601 DIA_CMC_01_Resp: 8 BMC_MLBevo
 SG_ DIA_CMC_01_Resp_Data : 0|64@1+ (1.0,0.0) [0.0|18446744073709551615] ""  Gateway,Gateway_PAG

BO_ 2549880530 DIA_CMC_02_Req: 8 Gateway
 SG_ DIA_CMC_02_Req_Data : 0|64@1+ (1.0,0.0) [0.0|18446744073709551615] ""  BMC_MLBevo

BO_ 2550011602 DIA_CMC_02_Resp: 8 BMC_MLBevo
 SG_ DIA_CMC_02_Resp_Data : 0|64@1+ (1.0,0.0) [0.0|18446744073709551615] ""  Gateway,Gateway_PAG

BO_ 2549880531 DIA_CMC_03_Req: 8 Gateway
 SG_ DIA_CMC_03_Req_Data : 0|64@1+ (1.0,0.0) [0.0|18446744073709551615] ""  BMC_MLBevo

BO_ 2550011603 DIA_CMC_03_Resp: 8 BMC_MLBevo
 SG_ DIA_CMC_03_Resp_Data : 0|64@1+ (1.0,0.0) [0.0|18446744073709551615] ""  Gateway,Gateway_PAG

BO_ 2549880532 DIA_CMC_04_Req: 8 Gateway
 SG_ DIA_CMC_04_Req_Data : 0|64@1+ (1.0,0.0) [0.0|18446744073709551615] ""  BMC_MLBevo

BO_ 2550011604 DIA_CMC_04_Resp: 8 BMC_MLBevo
 SG_ DIA_CMC_04_Resp_Data : 0|64@1+ (1.0,0.0) [0.0|18446744073709551615] ""  Gateway,Gateway_PAG

BO_ 2549880533 DIA_CMC_05_Req: 8 Gateway
 SG_ DIA_CMC_05_Req_Data : 0|64@1+ (1.0,0.0) [0.0|18446744073709551615] ""  BMC_MLBevo

BO_ 2550011605 DIA_CMC_05_Resp: 8 BMC_MLBevo
 SG_ DIA_CMC_05_Resp_Data : 0|64@1+ (1.0,0.0) [0.0|18446744073709551615] ""  Gateway,Gateway_PAG

BO_ 2549880534 DIA_CMC_06_Req: 8 Gateway
 SG_ DIA_CMC_06_Req_Data : 0|64@1+ (1.0,0.0) [0.0|18446744073709551615] ""  BMC_MLBevo

BO_ 2550011606 DIA_CMC_06_Resp: 8 BMC_MLBevo
 SG_ DIA_CMC_06_Resp_Data : 0|64@1+ (1.0,0.0) [0.0|18446744073709551615] ""  Gateway,Gateway_PAG

BO_ 2549880535 DIA_CMC_07_Req: 8 Gateway
 SG_ DIA_CMC_07_Req_Data : 0|64@1+ (1.0,0.0) [0.0|18446744073709551615] ""  BMC_MLBevo

BO_ 2550011607 DIA_CMC_07_Resp: 8 BMC_MLBevo
 SG_ DIA_CMC_07_Resp_Data : 0|64@1+ (1.0,0.0) [0.0|18446744073709551615] ""  Gateway,Gateway_PAG

BO_ 2549880536 DIA_CMC_08_Req: 8 Gateway
 SG_ DIA_CMC_08_Req_Data : 0|64@1+ (1.0,0.0) [0.0|18446744073709551615] ""  BMC_MLBevo

BO_ 2550011608 DIA_CMC_08_Resp: 8 BMC_MLBevo
 SG_ DIA_CMC_08_Resp_Data : 0|64@1+ (1.0,0.0) [0.0|18446744073709551615] ""  Gateway,Gateway_PAG

BO_ 2549880537 DIA_CMC_09_Req: 8 Gateway
 SG_ DIA_CMC_09_Req_Data : 0|64@1+ (1.0,0.0) [0.0|18446744073709551615] ""  BMC_MLBevo

BO_ 2550011609 DIA_CMC_09_Resp: 8 BMC_MLBevo
 SG_ DIA_CMC_09_Resp_Data : 0|64@1+ (1.0,0.0) [0.0|18446744073709551615] ""  Gateway,Gateway_PAG

BO_ 2549880538 DIA_CMC_10_Req: 8 Gateway
 SG_ DIA_CMC_10_Req_Data : 0|64@1+ (1.0,0.0) [0.0|18446744073709551615] ""  BMC_MLBevo

BO_ 2550011610 DIA_CMC_10_Resp: 8 BMC_MLBevo
 SG_ DIA_CMC_10_Resp_Data : 0|64@1+ (1.0,0.0) [0.0|18446744073709551615] ""  Gateway,Gateway_PAG

BO_ 2549880539 DIA_CMC_11_Req: 8 Gateway
 SG_ DIA_CMC_11_Req_Data : 0|64@1+ (1.0,0.0) [0.0|18446744073709551615] ""  BMC_MLBevo

BO_ 2550011611 DIA_CMC_11_Resp: 8 BMC_MLBevo
 SG_ DIA_CMC_11_Resp_Data : 0|64@1+ (1.0,0.0) [0.0|18446744073709551615] ""  Gateway,Gateway_PAG

BO_ 2549880540 DIA_CMC_12_Req: 8 Gateway
 SG_ DIA_CMC_12_Req_Data : 0|64@1+ (1.0,0.0) [0.0|18446744073709551615] ""  BMC_MLBevo

BO_ 2550011612 DIA_CMC_12_Resp: 8 BMC_MLBevo
 SG_ DIA_CMC_12_Resp_Data : 0|64@1+ (1.0,0.0) [0.0|18446744073709551615] ""  Gateway,Gateway_PAG

BO_ 2549880561 DIA_CMC_13_Req: 8 Gateway
 SG_ DIA_CMC_13_Req_Data : 0|64@1+ (1.0,0.0) [0.0|18446744073709551615] ""  BMC_MLBevo

BO_ 2550011633 DIA_CMC_13_Resp: 8 BMC_MLBevo
 SG_ DIA_CMC_13_Resp_Data : 0|64@1+ (1.0,0.0) [0.0|18446744073709551615] ""  Gateway,Gateway_PAG

BO_ 2549880562 DIA_CMC_14_Req: 8 Gateway
 SG_ DIA_CMC_14_Req_Data : 0|64@1+ (1.0,0.0) [0.0|18446744073709551615] ""  BMC_MLBevo

BO_ 2550011634 DIA_CMC_14_Resp: 8 BMC_MLBevo
 SG_ DIA_CMC_14_Resp_Data : 0|64@1+ (1.0,0.0) [0.0|18446744073709551615] ""  Gateway,Gateway_PAG

BO_ 2549880563 DIA_CMC_15_Req: 8 Gateway
 SG_ DIA_CMC_15_Req_Data : 0|64@1+ (1.0,0.0) [0.0|18446744073709551615] ""  BMC_MLBevo

BO_ 2550011635 DIA_CMC_15_Resp: 8 BMC_MLBevo
 SG_ DIA_CMC_15_Resp_Data : 0|64@1+ (1.0,0.0) [0.0|18446744073709551615] ""  Gateway,Gateway_PAG

BO_ 2549880413 DIA_EKK_Req: 8 Gateway
 SG_ DIA_EKK_Req_Data : 0|64@1+ (1.0,0.0) [0.0|18446744073709551615] ""  TME

BO_ 2550011485 DIA_EKK_Resp: 8 TME
 SG_ DIA_EKK_Resp_Data : 0|64@1+ (1.0,0.0) [0.0|18446744073709551615] ""  Gateway,Gateway_PAG

BO_ 2549880512 DIA_HV_H2_Req: 8 Gateway
 SG_ DIA_HV_H2_Req_Data : 0|64@1+ (1.0,0.0) [0.0|18446744073709551615] ""  TME

BO_ 2550011584 DIA_HV_H2_Resp: 8 TME
 SG_ DIA_HV_H2_Resp_Data : 0|64@1+ (1.0,0.0) [0.0|18446744073709551615] ""  Gateway,Gateway_PAG

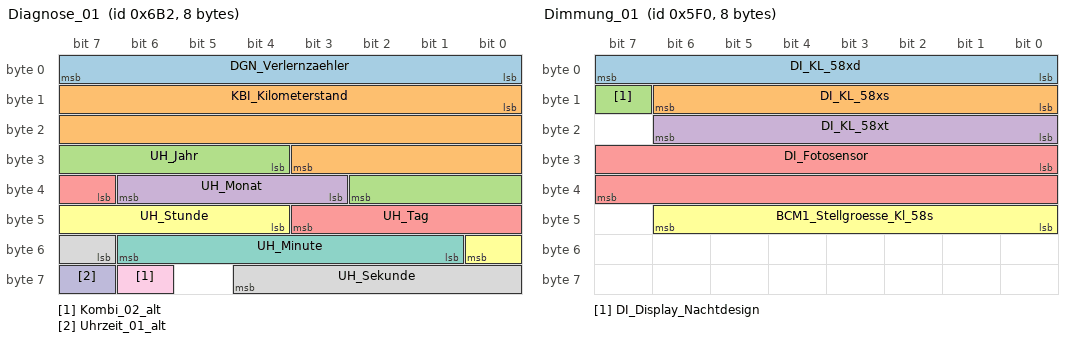
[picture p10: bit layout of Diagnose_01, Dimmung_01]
BO_ 1714 Diagnose_01: 8 Gateway
 SG_ DGN_Verlernzaehler : 0|8@1+ (1,0) [0|254] ""  AWC,BMS_MV,BMS_NV,DCDC_800V_PAG,DCDC_HV,DCDC_HV_02,DCDC_IHEV,Ladegeraet_2,Ladegeraet_Konzern
 SG_ KBI_Kilometerstand : 8|20@1+ (1,0) [0|1048573] "Unit_KiloMeter"  AWC,BMC_MLBevo,BMS_MV,BMS_NV,DCDC_800V_PAG,DCDC_HV,DCDC_HV_02,DCDC_IHEV,Ladegeraet_2,Ladegeraet_Konzern,LE1,LE2,LE_MLBevo,TME
 SG_ UH_Jahr : 28|7@1+ (1,2000) [2000|2127] "Unit_Year"  AWC,BMC_MLBevo,BMS_MV,BMS_NV,DCDC_800V_PAG,DCDC_HV,DCDC_HV_02,DCDC_IHEV,Ladegeraet_2,Ladegeraet_Konzern,LE1,LE2,LE_MLBevo,TME
 SG_ UH_Monat : 35|4@1+ (1,0) [1|12] "Unit_Month"  AWC,BMC_MLBevo,BMS_MV,BMS_NV,DCDC_800V_PAG,DCDC_HV,DCDC_HV_02,DCDC_IHEV,Ladegeraet_2,Ladegeraet_Konzern,LE1,LE2,LE_MLBevo,TME
 SG_ UH_Tag : 39|5@1+ (1,0) [1|31] "Unit_Day"  AWC,BMC_MLBevo,BMS_MV,BMS_NV,DCDC_800V_PAG,DCDC_HV,DCDC_HV_02,DCDC_IHEV,Ladegeraet_2,Ladegeraet_Konzern,LE1,LE2,LE_MLBevo,TME
 SG_ UH_Stunde : 44|5@1+ (1,0) [0|23] "Unit_Hours"  AWC,BMC_MLBevo,BMS_MV,BMS_NV,DCDC_800V_PAG,DCDC_HV,DCDC_HV_02,DCDC_IHEV,Ladegeraet_2,Ladegeraet_Konzern,LE1,LE2,LE_MLBevo,TME
 SG_ UH_Minute : 49|6@1+ (1,0) [0|59] "Unit_Minut"  AWC,BMC_MLBevo,BMS_MV,BMS_NV,DCDC_800V_PAG,DCDC_HV,DCDC_HV_02,DCDC_IHEV,Ladegeraet_2,Ladegeraet_Konzern,LE1,LE2,LE_MLBevo,TME
 SG_ UH_Sekunde : 55|6@1+ (1,0) [0|59] "Unit_Secon"  AWC,BMC_MLBevo,BMS_MV,BMS_NV,DCDC_800V_PAG,DCDC_HV,DCDC_HV_02,DCDC_IHEV,Ladegeraet_2,Ladegeraet_Konzern,LE1,LE2,LE_MLBevo,TME
 SG_ Kombi_02_alt : 62|1@1+ (1.0,0.0) [0.0|1] ""  DCDC_HV_02,Ladegeraet_2
 SG_ Uhrzeit_01_alt : 63|1@1+ (1.0,0.0) [0.0|1] ""  DCDC_HV_02,Ladegeraet_2

BO_ 1520 Dimmung_01: 8 Gateway
 SG_ DI_KL_58xd : 0|8@1+ (1,0) [0|253] ""  Ladegeraet_Konzern
 SG_ DI_KL_58xs : 8|7@1+ (1,0) [0|100] "Unit_PerCent"  Ladegeraet_Konzern
 SG_ DI_Display_Nachtdesign : 15|1@1+ (1.0,0.0) [0.0|1] ""  Vector__XXX
 SG_ DI_KL_58xt : 16|7@1+ (1,0) [0|100] "Unit_PerCent"  Ladegeraet_Konzern
 SG_ DI_Fotosensor : 24|16@1+ (1,0) [0|65535] ""  Vector__XXX
 SG_ BCM1_Stellgroesse_Kl_58s : 40|7@1+ (1,0) [0|100] ""  Vector__XXX

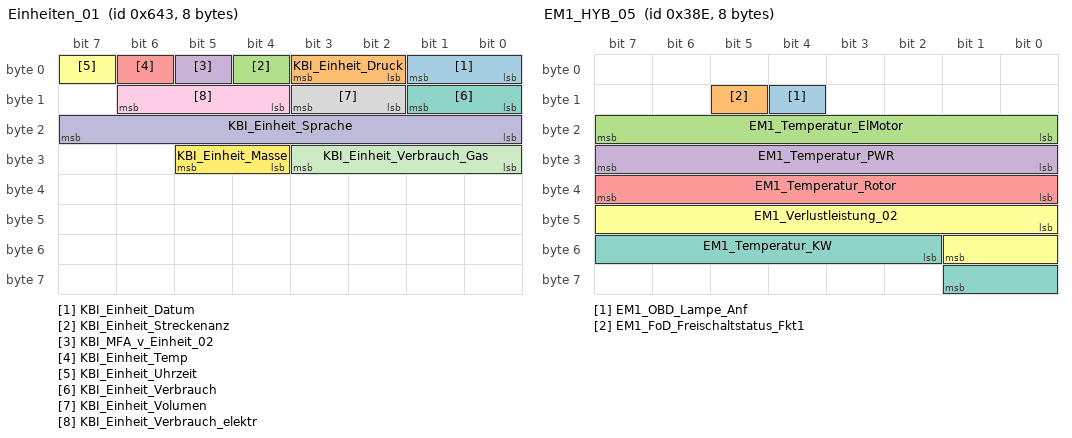
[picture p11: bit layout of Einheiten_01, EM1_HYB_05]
BO_ 1603 Einheiten_01: 8 Gateway
 SG_ KBI_Einheit_Datum : 0|2@1+ (1.0,0.0) [0.0|3] ""  Vector__XXX
 SG_ KBI_Einheit_Druck : 2|2@1+ (1.0,0.0) [0.0|3] ""  Vector__XXX
 SG_ KBI_Einheit_Streckenanz : 4|1@1+ (1.0,0.0) [0.0|1] ""  Ladegeraet_Konzern
 SG_ KBI_MFA_v_Einheit_02 : 5|1@1+ (1.0,0.0) [0.0|1] ""  Vector__XXX
 SG_ KBI_Einheit_Temp : 6|1@1+ (1.0,0.0) [0.0|1] ""  TME
 SG_ KBI_Einheit_Uhrzeit : 7|1@1+ (1.0,0.0) [0.0|1] ""  Ladegeraet_Konzern
 SG_ KBI_Einheit_Verbrauch : 8|2@1+ (1.0,0.0) [0.0|3] ""  Vector__XXX
 SG_ KBI_Einheit_Volumen : 10|2@1+ (1.0,0.0) [0.0|3] ""  Vector__XXX
 SG_ KBI_Einheit_Verbrauch_elektr : 12|3@1+ (1.0,0.0) [0.0|7] ""  Vector__XXX
 SG_ KBI_Einheit_Sprache : 16|8@1+ (1,0) [0|255] ""  Vector__XXX
 SG_ KBI_Einheit_Verbrauch_Gas : 24|4@1+ (1.0,0.0) [0.0|15] ""  Vector__XXX
 SG_ KBI_Einheit_Masse : 28|2@1+ (1.0,0.0) [0.0|3] ""  Vector__XXX

BO_ 910 EM1_HYB_05: 8 Gateway
 SG_ EM1_OBD_Lampe_Anf : 12|1@1+ (1.0,0.0) [0.0|1] ""  Vector__XXX
 SG_ EM1_FoD_Freischaltstatus_Fkt1 : 13|1@1+ (1.0,0.0) [0.0|1] ""  Vector__XXX
 SG_ EM1_Temperatur_ElMotor : 16|8@1+ (1,-40) [-40|213] "Unit_DegreCelsi"  TME
 SG_ EM1_Temperatur_PWR : 24|8@1+ (1,-40) [-40|213] "Unit_DegreCelsi"  TME
 SG_ EM1_Temperatur_Rotor : 32|8@1+ (1,-40) [-40|213] "Unit_DegreCelsi"  TME
 SG_ EM1_Verlustleistung_02 : 40|10@1+ (80,0) [0|81680] "Unit_Watt"  TME
 SG_ EM1_Temperatur_KW : 50|8@1+ (0.75,-48) [-48.00|141.75] "Unit_DegreCelsi"  Vector__XXX

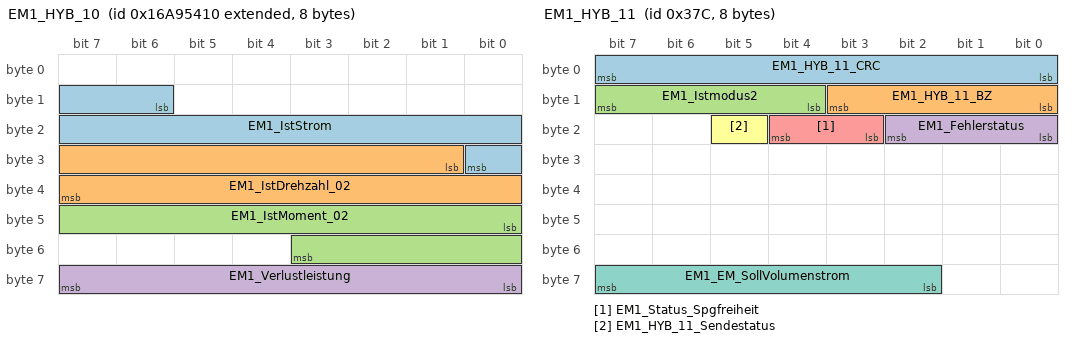
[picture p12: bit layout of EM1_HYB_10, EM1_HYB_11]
BO_ 2527679504 EM1_HYB_10: 8 LE_MLBevo
 SG_ EM1_IstStrom : 14|11@1+ (1,-1023) [-1023|1022] "Unit_Amper"  TME
 SG_ EM1_IstDrehzahl_02 : 25|15@1+ (1,-10000) [-10000|22765] "Unit_MinutInver"  BMC_MLBevo,TME
 SG_ EM1_IstMoment_02 : 40|12@1+ (0.5,-1023) [-1023.0|1023.5] "Unit_NewtoMeter"  TME
 SG_ EM1_Verlustleistung : 56|8@1+ (20,0) [0|5000] "Unit_Watt"  TME

BO_ 892 EM1_HYB_11: 8 Gateway
 SG_ EM1_HYB_11_CRC : 0|8@1+ (1,0) [0|255] ""  Gateway,Gateway_PAG
 SG_ EM1_HYB_11_BZ : 8|4@1+ (1,0) [0|15] ""  Gateway,Gateway_PAG
 SG_ EM1_Istmodus2 : 12|4@1+ (1.0,0.0) [0.0|15] ""  BMC_MLBevo,Ladegeraet_Konzern,TME
 SG_ EM1_Fehlerstatus : 16|3@1+ (1.0,0.0) [0.0|7] ""  Gateway,Gateway_PAG
 SG_ EM1_Status_Spgfreiheit : 19|2@1+ (1.0,0.0) [0.0|3] ""  Gateway,Gateway_PAG
 SG_ EM1_HYB_11_Sendestatus : 21|1@1+ (1.0,0.0) [0.0|1] ""  Vector__XXX
 SG_ EM1_EM_SollVolumenstrom : 58|6@1+ (0.5,0) [0.0|30.5] "Unit_LiterPerMinut"  TME

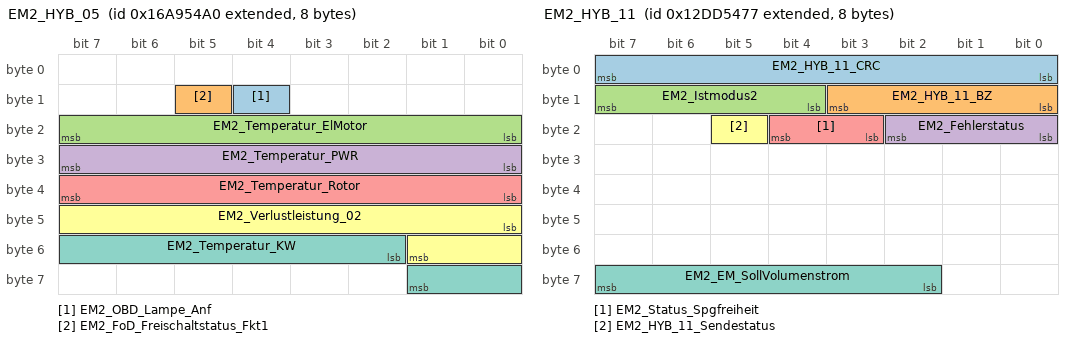
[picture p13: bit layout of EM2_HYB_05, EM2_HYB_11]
BO_ 2527679648 EM2_HYB_05: 8 Gateway
 SG_ EM2_OBD_Lampe_Anf : 12|1@1+ (1.0,0.0) [0.0|1] ""  Vector__XXX
 SG_ EM2_FoD_Freischaltstatus_Fkt1 : 13|1@1+ (1.0,0.0) [0.0|1] ""  Vector__XXX
 SG_ EM2_Temperatur_ElMotor : 16|8@1+ (1,-40) [-40|213] "Unit_DegreCelsi"  TME
 SG_ EM2_Temperatur_PWR : 24|8@1+ (1,-40) [-40|213] "Unit_DegreCelsi"  TME
 SG_ EM2_Temperatur_Rotor : 32|8@1+ (1,-40) [-40|213] "Unit_DegreCelsi"  TME
 SG_ EM2_Verlustleistung_02 : 40|10@1+ (80,0) [0|81680] "Unit_Watt"  TME
 SG_ EM2_Temperatur_KW : 50|8@1+ (0.75,-48) [-48.00|141.75] "Unit_DegreCelsi"  Vector__XXX

BO_ 2463978615 EM2_HYB_11: 8 Gateway
 SG_ EM2_HYB_11_CRC : 0|8@1+ (1,0) [0|255] ""  Gateway,Gateway_PAG
 SG_ EM2_HYB_11_BZ : 8|4@1+ (1,0) [0|15] ""  Gateway,Gateway_PAG
 SG_ EM2_Istmodus2 : 12|4@1+ (1.0,0.0) [0.0|15] ""  TME
 SG_ EM2_Fehlerstatus : 16|3@1+ (1.0,0.0) [0.0|7] ""  Gateway,Gateway_PAG
 SG_ EM2_Status_Spgfreiheit : 19|2@1+ (1.0,0.0) [0.0|3] ""  Gateway,Gateway_PAG
 SG_ EM2_HYB_11_Sendestatus : 21|1@1+ (1.0,0.0) [0.0|1] ""  Vector__XXX
 SG_ EM2_EM_SollVolumenstrom : 58|6@1+ (0.5,0) [0.0|30.5] "Unit_LiterPerMinut"  TME

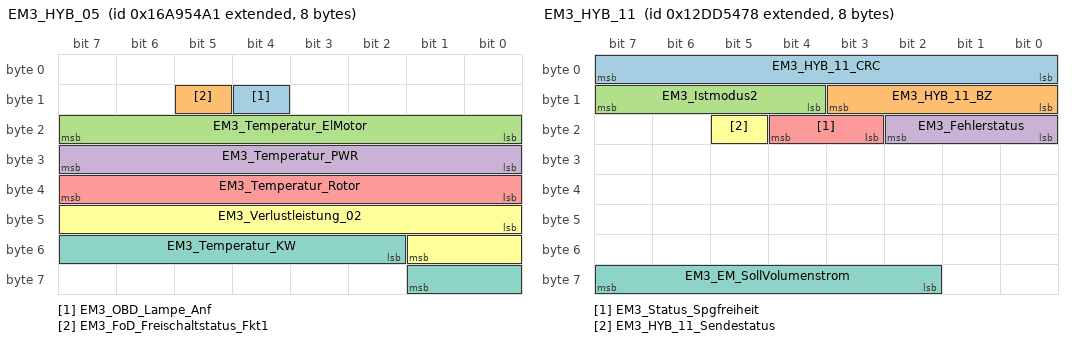
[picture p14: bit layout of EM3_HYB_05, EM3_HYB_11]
BO_ 2527679649 EM3_HYB_05: 8 Gateway
 SG_ EM3_OBD_Lampe_Anf : 12|1@1+ (1.0,0.0) [0.0|1] ""  Vector__XXX
 SG_ EM3_FoD_Freischaltstatus_Fkt1 : 13|1@1+ (1.0,0.0) [0.0|1] ""  Vector__XXX
 SG_ EM3_Temperatur_ElMotor : 16|8@1+ (1,-40) [-40|213] "Unit_DegreCelsi"  TME
 SG_ EM3_Temperatur_PWR : 24|8@1+ (1,-40) [-40|213] "Unit_DegreCelsi"  TME
 SG_ EM3_Temperatur_Rotor : 32|8@1+ (1,-40) [-40|213] "Unit_DegreCelsi"  TME
 SG_ EM3_Verlustleistung_02 : 40|10@1+ (80,0) [0|81680] "Unit_Watt"  TME
 SG_ EM3_Temperatur_KW : 50|8@1+ (0.75,-48) [-48.00|141.75] "Unit_DegreCelsi"  Vector__XXX

BO_ 2463978616 EM3_HYB_11: 8 Gateway
 SG_ EM3_HYB_11_CRC : 0|8@1+ (1,0) [0|255] ""  Vector__XXX
 SG_ EM3_HYB_11_BZ : 8|4@1+ (1,0) [0|15] ""  Vector__XXX
 SG_ EM3_Istmodus2 : 12|4@1+ (1.0,0.0) [0.0|15] ""  TME
 SG_ EM3_Fehlerstatus : 16|3@1+ (1.0,0.0) [0.0|7] ""  Vector__XXX
 SG_ EM3_Status_Spgfreiheit : 19|2@1+ (1.0,0.0) [0.0|3] ""  Vector__XXX
 SG_ EM3_HYB_11_Sendestatus : 21|1@1+ (1.0,0.0) [0.0|1] ""  Vector__XXX
 SG_ EM3_EM_SollVolumenstrom : 58|6@1+ (0.5,0) [0.0|30.5] "Unit_LiterPerMinut"  TME

BO_ 2589283600 EMG_CALID_CVN: 8 Gateway
 SG_ EMG_CALID_CVN_MUX M  : 0|2@1+ (1,0) [0|3] "Unit_None"  BMS_MV
 SG_ EMG_CVN_VLD : 7|1@1+ (1.0,0.0) [0.0|1] ""  BMS_MV
 SG_ EMG_CALID_Index_01 m0  : 8|8@1+ (1.0,0.0) [0.0|255] ""  BMS_MV
 SG_ EMG_CALID_Index_05 m1  : 8|8@1+ (1.0,0.0) [0.0|255] ""  BMS_MV
 SG_ EMG_CALID_Index_09 m2  : 8|8@1+ (1.0,0.0) [0.0|255] ""  BMS_MV
 SG_ EMG_CALID_Index_13 m3  : 8|8@1+ (1.0,0.0) [0.0|255] ""  BMS_MV
 SG_ EMG_CALID_Index_02 m0  : 16|8@1+ (1.0,0.0) [0.0|255] ""  BMS_MV
 SG_ EMG_CALID_Index_06 m1  : 16|8@1+ (1.0,0.0) [0.0|255] ""  BMS_MV
 SG_ EMG_CALID_Index_10 m2  : 16|8@1+ (1.0,0.0) [0.0|255] ""  BMS_MV
 SG_ EMG_CALID_Index_14 m3  : 16|8@1+ (1.0,0.0) [0.0|255] ""  BMS_MV
 SG_ EMG_CALID_Index_03 m0  : 24|8@1+ (1.0,0.0) [0.0|255] ""  BMS_MV
 SG_ EMG_CALID_Index_07 m1  : 24|8@1+ (1.0,0.0) [0.0|255] ""  BMS_MV
 SG_ EMG_CALID_Index_11 m2  : 24|8@1+ (1.0,0.0) [0.0|255] ""  BMS_MV
 SG_ EMG_CALID_Index_15 m3  : 24|8@1+ (1.0,0.0) [0.0|255] ""  BMS_MV
 SG_ EMG_CALID_Index_04 m0  : 32|8@1+ (1.0,0.0) [0.0|255] ""  BMS_MV
 SG_ EMG_CALID_Index_08 m1  : 32|8@1+ (1.0,0.0) [0.0|255] ""  BMS_MV
 SG_ EMG_CALID_Index_12 m2  : 32|8@1+ (1.0,0.0) [0.0|255] ""  BMS_MV
 SG_ EMG_CALID_Index_16 m3  : 32|8@1+ (1.0,0.0) [0.0|255] ""  BMS_MV
 SG_ EMG_CVN_Byte_1 m0  : 40|8@1+ (1.0,0.0) [0.0|255] ""  BMS_MV
 SG_ EMG_CVN_Byte_2 m1  : 40|8@1+ (1.0,0.0) [0.0|255] ""  BMS_MV
 SG_ EMG_CVN_Byte_3 m2  : 40|8@1+ (1.0,0.0) [0.0|255] ""  BMS_MV
 SG_ EMG_CVN_Byte_4 m3  : 40|8@1+ (1.0,0.0) [0.0|255] ""  BMS_MV

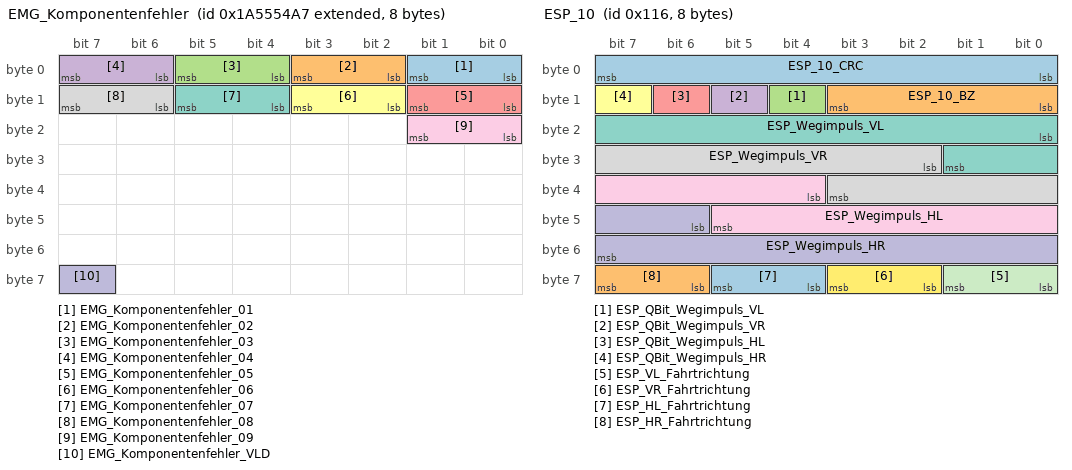
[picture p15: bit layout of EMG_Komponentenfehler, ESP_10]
BO_ 2589283495 EMG_Komponentenfehler: 8 Gateway
 SG_ EMG_Komponentenfehler_01 : 0|2@1+ (1.0,0.0) [0.0|3] ""  BMS_MV
 SG_ EMG_Komponentenfehler_02 : 2|2@1+ (1.0,0.0) [0.0|3] ""  BMS_MV
 SG_ EMG_Komponentenfehler_03 : 4|2@1+ (1.0,0.0) [0.0|3] ""  BMS_MV
 SG_ EMG_Komponentenfehler_04 : 6|2@1+ (1.0,0.0) [0.0|3] ""  BMS_MV
 SG_ EMG_Komponentenfehler_05 : 8|2@1+ (1.0,0.0) [0.0|3] ""  BMS_MV
 SG_ EMG_Komponentenfehler_06 : 10|2@1+ (1.0,0.0) [0.0|3] ""  BMS_MV
 SG_ EMG_Komponentenfehler_07 : 12|2@1+ (1.0,0.0) [0.0|3] ""  BMS_MV
 SG_ EMG_Komponentenfehler_08 : 14|2@1+ (1.0,0.0) [0.0|3] ""  BMS_MV
 SG_ EMG_Komponentenfehler_09 : 16|2@1+ (1.0,0.0) [0.0|3] ""  BMS_MV
 SG_ EMG_Komponentenfehler_VLD : 63|1@1+ (1.0,0.0) [0.0|1] ""  BMS_MV

BO_ 278 ESP_10: 8 Gateway
 SG_ ESP_10_CRC : 0|8@1+ (1,0) [0|255] ""  Vector__XXX
 SG_ ESP_10_BZ : 8|4@1+ (1,0) [0|15] ""  Vector__XXX
 SG_ ESP_QBit_Wegimpuls_VL : 12|1@1+ (1.0,0.0) [0.0|1] ""  AWC
 SG_ ESP_QBit_Wegimpuls_VR : 13|1@1+ (1.0,0.0) [0.0|1] ""  AWC
 SG_ ESP_QBit_Wegimpuls_HL : 14|1@1+ (1.0,0.0) [0.0|1] ""  AWC
 SG_ ESP_QBit_Wegimpuls_HR : 15|1@1+ (1.0,0.0) [0.0|1] ""  AWC
 SG_ ESP_Wegimpuls_VL : 16|10@1+ (1,0) [0|1000] ""  AWC
 SG_ ESP_Wegimpuls_VR : 26|10@1+ (1,0) [0|1000] ""  AWC
 SG_ ESP_Wegimpuls_HL : 36|10@1+ (1,0) [0|1000] ""  AWC
 SG_ ESP_Wegimpuls_HR : 46|10@1+ (1,0) [0|1000] ""  AWC
 SG_ ESP_VL_Fahrtrichtung : 56|2@1+ (1.0,0.0) [0.0|3] ""  AWC
 SG_ ESP_VR_Fahrtrichtung : 58|2@1+ (1.0,0.0) [0.0|3] ""  AWC
 SG_ ESP_HL_Fahrtrichtung : 60|2@1+ (1.0,0.0) [0.0|3] ""  AWC
 SG_ ESP_HR_Fahrtrichtung : 62|2@1+ (1.0,0.0) [0.0|3] ""  AWC

BO_ 418 ESP_15: 8 Gateway
 SG_ ESP_15_CRC : 0|8@1+ (1,0) [0|255] ""  Vector__XXX
 SG_ ESP_15_BZ : 8|4@1+ (1,0) [0|15] ""  Vector__XXX
 SG_ HMS_P_beibehalten_GE : 12|2@1+ (1.0,0.0) [0.0|3] ""  Vector__XXX
 SG_ HMS_Konsistenz_GE : 14|1@1+ (1.0,0.0) [0.0|1] ""  Vector__XXX
 SG_ HMS_Konsistenz_IPA : 15|1@1+ (1.0,0.0) [0.0|1] ""  Vector__XXX
 SG_ HMS_Konsistenz_STA : 18|1@1+ (1.0,0.0) [0.0|1] ""  Vector__XXX
 SG_ HMS_Konsistenz_MO : 19|1@1+ (1.0,0.0) [0.0|1] ""  Vector__XXX
 SG_ HMS_halten_nicht_verfuegbar : 20|1@1+ (1.0,0.0) [0.0|1] ""  Vector__XXX
 SG_ NL_PRIM_STP_01_Status : 21|3@1+ (1.0,0.0) [0.0|7] ""  Vector__XXX
 SG_ VMM_Warnblinken : 24|1@1+ (1.0,0.0) [0.0|1] ""  Vector__XXX
 SG_ VZM_Status : 26|3@1+ (1.0,0.0) [0.0|7] ""  Vector__XXX
 SG_ HMS_Notstopp_Status : 29|3@1+ (1.0,0.0) [0.0|7] ""  Vector__XXX
 SG_ HMS_parken_nicht_verfuegbar : 32|1@1+ (1.0,0.0) [0.0|1] ""  Vector__XXX
 SG_ HMS_Anforderung_GE : 33|3@1+ (1.0,0.0) [0.0|7] ""  Vector__XXX
 SG_ HMS_Systemstatus : 36|4@1+ (1.0,0.0) [0.0|15] ""  Ladegeraet_Konzern
 SG_ HMS_Stillstand : 40|3@1+ (1.0,0.0) [0.0|7] ""  Vector__XXX
 SG_ HMS_aktives_System : 43|5@1+ (1.0,0.0) [0.0|31] ""  Ladegeraet_Konzern
 SG_ HMS_Konsistenz_HVLM : 48|1@1+ (1.0,0.0) [0.0|1] ""  Ladegeraet_Konzern
 SG_ HMS_Konsistenz_ACC : 49|1@1+ (1.0,0.0) [0.0|1] ""  Vector__XXX
 SG_ HMS_Fehlerstatus : 50|3@1+ (1.0,0.0) [0.0|7] ""  Ladegeraet_Konzern
 SG_ ESP_Index_Haltemoment : 53|1@1+ (1.0,0.0) [0.0|1] ""  Vector__XXX
 SG_ ESP_Haltemoment : 54|10@1+ (10,0) [0|10210] "Unit_NewtoMeter"  Vector__XXX

BO_ 1629 ESP_20: 8 Gateway
 SG_ ESP_20_CRC : 0|8@1+ (1,0) [0|255] ""  Vector__XXX
 SG_ ESP_20_BZ : 8|4@1+ (1,0) [0|15] ""  Vector__XXX
 SG_ BR_Systemart : 12|2@1+ (1.0,0.0) [0.0|3] ""  Vector__XXX
 SG_ ESP_SpannungsAnf_02 : 14|2@1+ (1.0,0.0) [0.0|3] ""  Vector__XXX
 SG_ ESP_Zaehnezahl : 16|8@1+ (1,0) [0|255] ""  Vector__XXX
 SG_ ESP_Charisma_FahrPr : 24|4@1+ (1.0,0.0) [0.0|15] ""  Vector__XXX
 SG_ ESP_Charisma_Status : 28|2@1+ (1.0,0.0) [0.0|3] ""  Vector__XXX
 SG_ ESP_Wiederstart_Anz_01 : 30|1@1+ (1.0,0.0) [0.0|1] ""  Vector__XXX
 SG_ ESP_Wiederstart_Anz_02 : 31|1@1+ (1.0,0.0) [0.0|1] ""  Vector__XXX
 SG_ ESP_Wiederstart_Anz_03 : 32|1@1+ (1.0,0.0) [0.0|1] ""  Vector__XXX
 SG_ ESP_Wiederstart_Anz_04 : 33|1@1+ (1.0,0.0) [0.0|1] ""  Vector__XXX
 SG_ ESP_Stoppverbot_Anz_01 : 34|1@1+ (1.0,0.0) [0.0|1] ""  Vector__XXX
 SG_ ESP_Stoppverbot_Anz_02 : 35|1@1+ (1.0,0.0) [0.0|1] ""  Vector__XXX
 SG_ ESP_Stoppverbot_Anz_03 : 36|1@1+ (1.0,0.0) [0.0|1] ""  Vector__XXX
 SG_ ESP_Stoppverbot_Anz_04 : 37|1@1+ (1.0,0.0) [0.0|1] ""  Vector__XXX
 SG_ ESP_Stoppverbot_Anz_05 : 38|1@1+ (1.0,0.0) [0.0|1] ""  Vector__XXX
 SG_ ESP_Stoppverbot_Anz_06 : 39|1@1+ (1.0,0.0) [0.0|1] ""  Vector__XXX
 SG_ ESP_Stoppverbot_Anz_07 : 40|1@1+ (1.0,0.0) [0.0|1] ""  Vector__XXX
 SG_ ESP_Stoppverbot_Anz_Std : 41|1@1+ (1.0,0.0) [0.0|1] ""  Vector__XXX
 SG_ ESP_Dachrelingsensor : 42|2@1+ (1.0,0.0) [0.0|3] ""  Vector__XXX
 SG_ ESP_Stoppverbot_Anz_08 : 44|1@1+ (1.0,0.0) [0.0|1] ""  Vector__XXX
 SG_ HDC_Charisma_FahrPr : 45|4@1+ (1.0,0.0) [0.0|15] ""  Vector__XXX
 SG_ HDC_Charisma_Status : 49|2@1+ (1.0,0.0) [0.0|3] ""  Vector__XXX
 SG_ BR_QBit_Reifenumfang : 51|1@1+ (1.0,0.0) [0.0|1] ""  AWC
 SG_ BR_Reifenumfang : 52|12@1+ (1,0) [0|4095] "Unit_MilliMeter"  AWC

BO_ 253 ESP_21: 8 Gateway
 SG_ ESP_21_CRC : 0|8@1+ (1,0) [0|255] ""  Vector__XXX
 SG_ ESP_21_BZ : 8|4@1+ (1,0) [0|15] ""  Vector__XXX
 SG_ BR_Eingriffsmoment : 12|10@1+ (1,-509) [-509|509] ""  Vector__XXX
 SG_ ESP_Diagnose : 23|1@1+ (1.0,0.0) [0.0|1] ""  Vector__XXX
 SG_ ESC_v_Signal_Qualifier_High_Low : 24|3@1+ (1.0,0.0) [0.0|7] ""  Vector__XXX
 SG_ ESP_Vorsteuerung : 28|1@1+ (1.0,0.0) [0.0|1] ""  Vector__XXX
 SG_ OBD_Schlechtweg : 30|1@1+ (1.0,0.0) [0.0|1] ""  Vector__XXX
 SG_ OBD_QBit_Schlechtweg : 31|1@1+ (1.0,0.0) [0.0|1] ""  Vector__XXX
 SG_ ESP_v_Signal : 32|16@1+ (0.01,0) [0.00|655.32] "Unit_KiloMeterPerHour"  AWC,BMC_MLBevo,BMS_MV,BMS_NV,DCDC_800V_PAG,DCDC_HV,DCDC_HV_02,DCDC_IHEV,Ladegeraet_2,Ladegeraet_Konzern,TME
 SG_ ASR_Tastung_passiv : 48|1@1+ (1.0,0.0) [0.0|1] ""  Vector__XXX
 SG_ ESP_Tastung_passiv : 49|1@1+ (1.0,0.0) [0.0|1] ""  Vector__XXX
 SG_ ESP_Systemstatus : 50|1@1+ (1.0,0.0) [0.0|1] ""  Vector__XXX
 SG_ ASR_Schalteingriff : 51|2@1+ (1.0,0.0) [0.0|3] ""  Vector__XXX
 SG_ ESP_QBit_v_Signal : 55|1@1+ (1.0,0.0) [0.0|1] ""  AWC,BMS_NV,Ladegeraet_2,Ladegeraet_Konzern,TME
 SG_ ABS_Bremsung : 56|1@1+ (1.0,0.0) [0.0|1] ""  Vector__XXX
 SG_ ASR_Anf : 57|1@1+ (1.0,0.0) [0.0|1] ""  Vector__XXX
 SG_ MSR_Anf : 58|1@1+ (1.0,0.0) [0.0|1] ""  Vector__XXX
 SG_ EBV_Eingriff : 59|1@1+ (1.0,0.0) [0.0|1] ""  Vector__XXX
 SG_ EDS_Eingriff : 60|1@1+ (1.0,0.0) [0.0|1] ""  Vector__XXX
 SG_ ESP_Eingriff : 61|1@1+ (1.0,0.0) [0.0|1] ""  Vector__XXX
 SG_ ESP_ASP : 62|1@1+ (1.0,0.0) [0.0|1] ""  Vector__XXX
 SG_ ESC_Neutralschaltung : 63|1@1+ (1.0,0.0) [0.0|1] ""  Vector__XXX

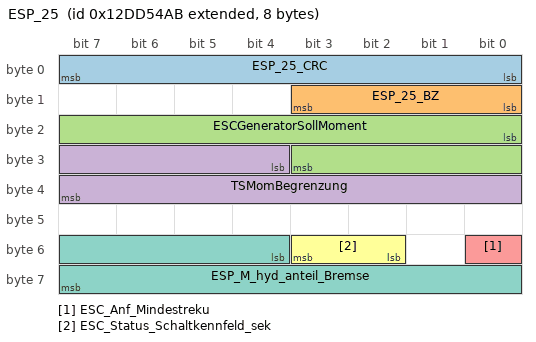
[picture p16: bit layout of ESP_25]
BO_ 2463978667 ESP_25: 8 Gateway
 SG_ ESP_25_CRC : 0|8@1+ (1,0) [0|255] ""  Vector__XXX
 SG_ ESP_25_BZ : 8|4@1+ (1,0) [0|15] ""  Vector__XXX
 SG_ ESCGeneratorSollMoment : 16|12@1+ (3,-12279) [-12279|0] ""  Vector__XXX
 SG_ TSMomBegrenzung : 28|12@1+ (3,-12279) [-12279|0] ""  Vector__XXX
 SG_ ESC_Anf_Mindestreku : 48|1@1+ (1.0,0.0) [0.0|1] ""  TME
 SG_ ESC_Status_Schaltkennfeld_sek : 50|2@1+ (1.0,0.0) [0.0|3] ""  Vector__XXX
 SG_ ESP_M_hyd_anteil_Bremse : 52|12@1+ (4,0) [0|16372] "Unit_NewtoMeter"  Vector__XXX

BO_TX_BU_ 2549880528 :Gateway,Gateway_PAG;
BO_TX_BU_ 2549880529 :Gateway,Gateway_PAG;
BO_TX_BU_ 2549880530 :Gateway,Gateway_PAG;
BO_TX_BU_ 2549880531 :Gateway,Gateway_PAG;
BO_TX_BU_ 2549880532 :Gateway,Gateway_PAG;
BO_TX_BU_ 2549880533 :Gateway,Gateway_PAG;
BO_TX_BU_ 2549880534 :Gateway,Gateway_PAG;
BO_TX_BU_ 2549880535 :Gateway,Gateway_PAG;
BO_TX_BU_ 2549880536 :Gateway,Gateway_PAG;
BO_TX_BU_ 2549880537 :Gateway,Gateway_PAG;
BO_TX_BU_ 2549880538 :Gateway,Gateway_PAG;
BO_TX_BU_ 2549880539 :Gateway,Gateway_PAG;
BO_TX_BU_ 2549880540 :Gateway,Gateway_PAG;
BO_TX_BU_ 2549880561 :Gateway,Gateway_PAG;
BO_TX_BU_ 2549880562 :Gateway,Gateway_PAG;
BO_TX_BU_ 2549880563 :Gateway,Gateway_PAG;
BO_TX_BU_ 2549880413 :Gateway,Gateway_PAG;
BO_TX_BU_ 2549880512 :Gateway,Gateway_PAG;
BO_TX_BU_ 1714 :Gateway,Gateway_PAG;
BO_TX_BU_ 1520 :Gateway,Gateway_PAG;
BO_TX_BU_ 1603 :Gateway,Gateway_PAG;
BO_TX_BU_ 910 :Gateway,Gateway_PAG,LE_MLBevo;
BO_TX_BU_ 892 :Gateway,LE1,LE_MLBevo;
BO_TX_BU_ 2463978615 :Gateway,LE2;
BO_TX_BU_ 2527679649 :Gateway,Gateway_PAG;
BO_TX_BU_ 2589283600 :Gateway,Gateway_PAG;
BO_TX_BU_ 2589283495 :Gateway,Gateway_PAG;
BO_TX_BU_ 278 :Gateway,Gateway_PAG;
BO_TX_BU_ 418 :Gateway,Gateway_PAG;
BO_TX_BU_ 1629 :Gateway,Gateway_PAG;
BO_TX_BU_ 253 :Gateway,Gateway_PAG;
BO_TX_BU_ 2463978667 :Gateway,Gateway_PAG;
CM_ BO_ 1520 "ab MQB nach abgestimmten FLH Dimmung";
CM_ BO_ 1603 "ab MQB mit 8 Byte";
CM_ BO_ 910 "CAN-Botschaft";
CM_ BO_ 2527679648 "CAN-Botschaft";
CM_ BO_ 418 "MLBevo verlangsamte 100ms-Botschaft";
CM_ BO_ 1629 "neu im MQB";
CM_ BO_ 253 "Neue Momente im MQB
Struktur ab MQB mit CRC8 entstanden aus ESP_01";

CM_ SG_ 2549880528 DIA_BJB_Req_Data "Diagnosezugriff & Flashen Batterie Junction Box";

CM_ SG_ 2550011600 DIA_BJB_Resp_Data "Diagnosezugriff & Flashen Batterie Junction Box";

CM_ SG_ 2549880529 DIA_CMC_01_Req_Data "Diagnosezugriff & Flashen Cell Module Controller";

CM_ SG_ 2550011601 DIA_CMC_01_Resp_Data "Diagnosezugriff & Flashen Cell Module Controller";

CM_ SG_ 2549880530 DIA_CMC_02_Req_Data "Diagnosezugriff & Flashen Cell Module Controller";

CM_ SG_ 2550011602 DIA_CMC_02_Resp_Data "Diagnosezugriff & Flashen Cell Module Controller";

CM_ SG_ 2549880531 DIA_CMC_03_Req_Data "Diagnosezugriff & Flashen Cell Module Controller";

CM_ SG_ 2550011603 DIA_CMC_03_Resp_Data "Diagnosezugriff & Flashen Cell Module Controller";

CM_ SG_ 2549880532 DIA_CMC_04_Req_Data "Diagnosezugriff & Flashen Cell Module Controller";

CM_ SG_ 2550011604 DIA_CMC_04_Resp_Data "Diagnosezugriff & Flashen Cell Module Controller";

CM_ SG_ 2549880533 DIA_CMC_05_Req_Data "Diagnosezugriff & Flashen Cell Module Controller";

CM_ SG_ 2550011605 DIA_CMC_05_Resp_Data "Diagnosezugriff & Flashen Cell Module Controller";

CM_ SG_ 2549880534 DIA_CMC_06_Req_Data "Diagnosezugriff & Flashen Cell Module Controller";

CM_ SG_ 2550011606 DIA_CMC_06_Resp_Data "Diagnosezugriff & Flashen Cell Module Controller";

CM_ SG_ 2549880535 DIA_CMC_07_Req_Data "Diagnosezugriff & Flashen Cell Module Controller";

CM_ SG_ 2550011607 DIA_CMC_07_Resp_Data "Diagnosezugriff & Flashen Cell Module Controller";

CM_ SG_ 2549880536 DIA_CMC_08_Req_Data "Diagnosezugriff & Flashen Cell Module Controller";

CM_ SG_ 2550011608 DIA_CMC_08_Resp_Data "Diagnosezugriff & Flashen Cell Module Controller";

CM_ SG_ 2549880537 DIA_CMC_09_Req_Data "Diagnosezugriff & Flashen Cell Module Controller";

CM_ SG_ 2550011609 DIA_CMC_09_Resp_Data "Diagnosezugriff & Flashen Cell Module Controller";

CM_ SG_ 2549880538 DIA_CMC_10_Req_Data "Diagnosezugriff & Flashen Cell Module Controller";

CM_ SG_ 2550011610 DIA_CMC_10_Resp_Data "Diagnosezugriff & Flashen Cell Module Controller";

CM_ SG_ 2549880539 DIA_CMC_11_Req_Data "Diagnosezugriff & Flashen Cell Module Controller";

CM_ SG_ 2550011611 DIA_CMC_11_Resp_Data "Diagnosezugriff & Flashen Cell Module Controller";

CM_ SG_ 2549880540 DIA_CMC_12_Req_Data "Diagnosezugriff & Flashen Cell Module Controller";

CM_ SG_ 2550011612 DIA_CMC_12_Resp_Data "Diagnosezugriff & Flashen Cell Module Controller";

CM_ SG_ 2549880561 DIA_CMC_13_Req_Data "Diagnosezugriff & Flashen Cell Module Controller";

CM_ SG_ 2550011633 DIA_CMC_13_Resp_Data "Diagnosezugriff & Flashen Cell Module Controller";

CM_ SG_ 2549880562 DIA_CMC_14_Req_Data "Diagnosezugriff & Flashen Cell Module Controller";

CM_ SG_ 2550011634 DIA_CMC_14_Resp_Data "Diagnosezugriff & Flashen Cell Module Controller";

CM_ SG_ 2549880563 DIA_CMC_15_Req_Data "Diagnosezugriff & Flashen Cell Module Controller";

CM_ SG_ 2550011635 DIA_CMC_15_Resp_Data "Diagnosezugriff & Flashen Cell Module Controller";

CM_ SG_ 2549880413 DIA_EKK_Req_Data "Diagnosezugriff & Flashen elektrischer Klimakompressor";

CM_ SG_ 2550011485 DIA_EKK_Resp_Data "Diagnosezugriff & Flashen elektrischer Klimakompressor";

CM_ SG_ 2549880512 DIA_HV_H2_Req_Data "Diagnosezugriff & Flashen Hochvolt Wasserheizer";

CM_ SG_ 2550011584 DIA_HV_H2_Resp_Data "Diagnosezugriff & Flashen Hochvolt Wasserheizer";

CM_ SG_ 1714 DGN_Verlernzaehler "wrap around 254 --> 0";
CM_ SG_ 1714 KBI_Kilometerstand "Fehler wird ausgegeben, falls Kilometerstand nicht restaurierbar
";
CM_ SG_ 1714 UH_Minute "0x3C- 0x3f = Werte ungültig";
CM_ SG_ 1714 UH_Monat "0x0D, 0xF =  Werte ungültig
0x0E = reserviert (nur VW)";
CM_ SG_ 1714 UH_Sekunde "0x3C- 0x3f = Werte ungültig";
CM_ SG_ 1714 UH_Stunde "0x18 - 0x1F = Werte ungültig";
CM_ SG_ 1714 UH_Tag "0x0: reserviert bei VW";
CM_ SG_ 1714 Uhrzeit_01_alt "
";

CM_ SG_ 1520 BCM1_Stellgroesse_Kl_58s "Rohwert Dimmpoti";
CM_ SG_ 1520 DI_Display_Nachtdesign "Für Displays sind oft  automatische Umschaltungen von Tag-/Nachtdesign vorgesehen.
Es gibt jedoch Zustände, an denen auch tagsüber das Abblendlicht eingeschaltet ist.
z.B. Dauerfahrlicht, Geschwindigkeitsabhängiges 'Licht-An-Bei-Autobahn', 'Regenlicht',";
CM_ SG_ 1520 DI_Fotosensor "Helligkeitswert Fotosensor
Für die Dimmung relevanter Wert zur Sensierung der Umgebungshelligkeit
Im Detail beschrieben im 'Funktionslastenheft Dimmung MQB'.";
CM_ SG_ 1520 DI_KL_58xd "Klemme 58xd Display- und Funktionsbeleuchtung
Mit der Klemme 58xd wird die Helligkeit der Display- und der Funktionsbeleuchtungen der Schalter gesteuert.
Im Detail beschrieben im 'Funktionslastenheft Dimmung MQB'.";
CM_ SG_ 1520 DI_KL_58xs "Suchbeleuchtung Schalter
EIN-AUS-Schaltalgorithmus der allgemeinen Schaltersuchbeleuchtung. 
Im Detail beschrieben im 'Funktionslastenheft Dimmung MQB'.
";
CM_ SG_ 1520 DI_KL_58xt "Timergesteuerte Suchbeleuchtung
Der EIN-AUS-Schaltalgorithmus für die vor- und nachlaufende Schaltersuchbeleuchtungen beim Ein- & Aussteigen; z.B.: Start/Stop-Taster.
Im Detail beschrieben im 'Funktionslastenheft Dimmung MQB'.";

CM_ SG_ 1603 KBI_Einheit_Datum "Anzeigevariante des Datums";
CM_ SG_ 1603 KBI_Einheit_Druck "Einheit des Druckes";
CM_ SG_ 1603 KBI_Einheit_Masse "Einheit der Masse (Verwendung z.B. ASTA)";
CM_ SG_ 1603 KBI_Einheit_Sprache "Siehe BAP-Datenfestlegung UnitMaster";
CM_ SG_ 1603 KBI_Einheit_Streckenanz "Einheit der Streckenanzeige";
CM_ SG_ 1603 KBI_Einheit_Temp "Einheit der Temperatur";
CM_ SG_ 1603 KBI_Einheit_Uhrzeit "Anzeigevariante der Uhrzeit";
CM_ SG_ 1603 KBI_Einheit_Verbrauch "Einheit der Verbrauchs";
CM_ SG_ 1603 KBI_Einheit_Verbrauch_elektr "Einheit elektrischer Verbrauch";
CM_ SG_ 1603 KBI_Einheit_Verbrauch_Gas "Unterscheidung zwischen M3/h und kg/h für Komfortverbrauchsberechnung.";
CM_ SG_ 1603 KBI_Einheit_Volumen "Einheit des Volumens";
CM_ SG_ 1603 KBI_MFA_v_Einheit_02 "Einheit der Geschwindigkeit, die vom Fahrer im Car-Menü gewählt wurde. Veränderliche Grösse, im Gegensatz zur Einheit des Tachokranzes.

Redundant in der Einheiten_01 Botschaft definiert, um Konsistenz zur BAP-Festlegung zu haben.";

CM_ SG_ 910 EM1_FoD_Freischaltstatus_Fkt1 "zeigt den Status der FoD-Freischaltung für das Performanz Paket an";
CM_ SG_ 910 EM1_OBD_Lampe_Anf "In allen VW-/Audi-Fahrzeugen ist ein MIL-Master-Konzept umgesetzt. Dazu ermittelt jedes OBD-Steuergerät den eigenen MIL-Status. Eine MIL-Ansteuerung wird vom betroffenen OBD-Steuergerät per MIL-Request über CAN an den MIL-Master weitergegeben. Der MIL-Mas";
CM_ SG_ 910 EM1_Temperatur_ElMotor "Momentanwert: Temperatur der E-Maschine";
CM_ SG_ 910 EM1_Temperatur_KW "Aktueller Ist-Wert Kuehlwassertemperatur Leistungselektronik / E-Machine 1";
CM_ SG_ 910 EM1_Temperatur_PWR "Momentanwert: Temperatur des PWR";
CM_ SG_ 910 EM1_Temperatur_Rotor "Momentanwert: Temperatur des Rotors";
CM_ SG_ 910 EM1_Verlustleistung_02 "Instantaneous power loss of electrical drive EM1 / Momentane Verlustleistung elektischer Antrieb EM1";

CM_ SG_ 2527679504 EM1_IstDrehzahl_02 "Momentanwert: E-Maschinen Drehzahl";
CM_ SG_ 2527679504 EM1_IstMoment_02 "Momentanwert: E-Maschinen Moment";
CM_ SG_ 2527679504 EM1_IstStrom "Momentanwert: Strom über PWR";
CM_ SG_ 2527679504 EM1_Verlustleistung "Momentane Verlustleistung Pulswechselrichter und DCDC-Wandler";

CM_ SG_ 892 EM1_EM_SollVolumenstrom "Für die Kühlung der E-Maschine aktuell mindestens benötigter Kühlwasservolumenstrom


MQB/MEB: funktional 500ms (Cyclic) Zykluszeit notwendig

MLBevo: funktional 50ms (OnChange) Zykluszeit notwendig";
CM_ SG_ 892 EM1_Fehlerstatus "aktueller Fehlerstatus der LEH1. Anzeige von Fehlern der HV-Sicherheitsfunktionen.";
CM_ SG_ 892 EM1_HYB_11_BZ "Fehlende Beschreibung (Import)";
CM_ SG_ 892 EM1_HYB_11_CRC "Für MLB:
'Berechnung siehe Lastenheft 'Kommunikationsabsicherung für FlexRay und CAN''

Ab MQB und MLBevo:
'Berechnung siehe Lastenheft 'End-to-End Kommunikationsabsicherung''

Endwerte siehe Begleitdokument 'S-PDU Kennungsfolgen'";
CM_ SG_ 892 EM1_HYB_11_Sendestatus "Gibt den Sendestatus der Botschaft EM1_HYB_11 an (notwendig für IL-Unterstützung)
Dauer hängt von gesetzem HVK_Istmodus_Anf ab.";
CM_ SG_ 892 EM1_Istmodus2 "aktuelle Betriebsart der E-Maschine...
0: Standby; Kommunikation aktiv; aktiver Kurzschluss
1: Momentenreglung
2: Drezahlregeung (interner Regelkreis)
3: Spannungsregelung
4: Drehzahlregelung (externer Regelkreis)
5: interner Inverter Fehler; angefo";
CM_ SG_ 892 EM1_Status_Spgfreiheit "0 = Init (ohne Funktion)
1 = Leistungselektronik HV-Komponenten spannungsfrei (U_Zwkr < 20V)
2 = Leistungselektronik HV_Komponenten nicht spannungsfrei (U_Zwkr >= 20V)
3 = Fehler (z. B. Fehler in der Sensorik)";

CM_ SG_ 2527679648 EM2_FoD_Freischaltstatus_Fkt1 "zeigt den Status der FoD-Freischaltung für das Performanz Paket an";
CM_ SG_ 2527679648 EM2_OBD_Lampe_Anf "In allen VW-/Audi-Fahrzeugen ist ein MIL-Master-Konzept umgesetzt. Dazu ermittelt jedes OBD-Steuergerät den eigenen MIL-Status. Eine MIL-Ansteuerung wird vom betroffenen OBD-Steuergerät per MIL-Request über CAN an den MIL-Master weitergegeben. Der MIL-Mas";
CM_ SG_ 2527679648 EM2_Temperatur_ElMotor "Momentanwert: Temperatur der E-Maschine";
CM_ SG_ 2527679648 EM2_Temperatur_KW "Aktueller Ist-Wert Kuehlwassertemperatur Leistungselektronik / E-Machine 2";
CM_ SG_ 2527679648 EM2_Temperatur_PWR "Momentanwert: Temperatur des PWR";
CM_ SG_ 2527679648 EM2_Temperatur_Rotor "Momentanwert: Temperatur des Rotors";
CM_ SG_ 2527679648 EM2_Verlustleistung_02 "Instantaneous power loss of electrical drive EM2 / Momentane Verlustleistung elektischer Antrieb EM2";

CM_ SG_ 2463978615 EM2_EM_SollVolumenstrom "Für die Kühlung der E-Maschine aktuell mindestens benötigter Kühlwasservolumenstrom


MQB/MEB: funktional 500ms (Cyclic) Zykluszeit notwendig

MLBevo: funktional 50ms (OnChange) Zykluszeit notwendig";
CM_ SG_ 2463978615 EM2_Fehlerstatus "aktueller Fehlerstatus der LE2. Anzeige von Fehlern der HV-Sicherheitsfunktionen.";
CM_ SG_ 2463978615 EM2_HYB_11_BZ "Fehlende Beschreibung (Import)";
CM_ SG_ 2463978615 EM2_HYB_11_CRC "Für MLB:
'Berechnung siehe Lastenheft 'Kommunikationsabsicherung für FlexRay und CAN''

Ab MQB und MLBevo:
'Berechnung siehe Lastenheft 'End-to-End Kommunikationsabsicherung''

Endwerte siehe Begleitdokument 'S-PDU Kennungsfolgen'";
CM_ SG_ 2463978615 EM2_HYB_11_Sendestatus "Gibt den Sendestatus der Botschaft EM2_HYB_11 an (notwendig für IL-Unterstützung)
Dauer hängt von gesetzem HVK_Istmodus_Anf ab.";
CM_ SG_ 2463978615 EM2_Istmodus2 "aktuelle Betriebsart der E-Maschine...
0: Standby; Kommunikation aktiv; aktiver Kurzschluss
1: Momentenreglung
2: Drezahlregeung (interner Regelkreis)
3: Spannungsregelung
4: Drehzahlregelung (externer Regelkreis)
5: interner Inverter Fehler; angefo";
CM_ SG_ 2463978615 EM2_Status_Spgfreiheit "0 = Init (ohne Funktion)
1 = Leistungselektronik HV-Komponenten spannungsfrei (U_Zwkr < 20V)
2 = Leistungselektronik HV_Komponenten nicht spannungsfrei (U_Zwkr >= 20V)
3 = Fehler (z. B. Fehler in der Sensorik)";

CM_ SG_ 2527679649 EM3_FoD_Freischaltstatus_Fkt1 "zeigt den Status der FoD-Freischaltung für das Performanz Paket an";
CM_ SG_ 2527679649 EM3_OBD_Lampe_Anf "In allen VW-/Audi-Fahrzeugen ist ein MIL-Master-Konzept umgesetzt. Dazu ermittelt jedes OBD-Steuergerät den eigenen MIL-Status. Eine MIL-Ansteuerung wird vom betroffenen OBD-Steuergerät per MIL-Request über CAN an den MIL-Master weitergegeben. Der MIL-Mas";
CM_ SG_ 2527679649 EM3_Temperatur_ElMotor "Momentanwert: Temperatur der E-Maschine";
CM_ SG_ 2527679649 EM3_Temperatur_KW "Aktueller Ist-Wert Kuehlwassertemperatur Leistungselektronik / E-Machine 3";
CM_ SG_ 2527679649 EM3_Temperatur_PWR "Momentanwert: Temperatur des PWR";
CM_ SG_ 2527679649 EM3_Temperatur_Rotor "Momentanwert: Temperatur des Rotors";
CM_ SG_ 2527679649 EM3_Verlustleistung_02 "Instantaneous power loss of electrical drive EM3 / Momentane Verlustleistung elektischer Antrieb EM3";

CM_ SG_ 2463978616 EM3_EM_SollVolumenstrom "Für die Kühlung der E-Maschine aktuell mindestens benötigter Kühlwasservolumenstrom";
CM_ SG_ 2463978616 EM3_Fehlerstatus "aktueller Fehlerstatus der LE3. Anzeige von Fehlern der HV-Sicherheitsfunktionen.";
CM_ SG_ 2463978616 EM3_HYB_11_BZ "Botschaftszähler";
CM_ SG_ 2463978616 EM3_HYB_11_CRC "Für MLB:
'Berechnung siehe Lastenheft 'Kommunikationsabsicherung für FlexRay und CAN''

Ab MQB und MLBevo:
'Berechnung siehe Lastenheft 'End-to-End Kommunikationsabsicherung''

Endwerte siehe Begleitdokument 'S-PDU Kennungsfolgen'";
CM_ SG_ 2463978616 EM3_HYB_11_Sendestatus "Gibt den Sendestatus der Botschaft EM3_HYB_11 an (notwendig für IL-Unterstützung)
Dauer hängt von gesetzem HVK_Istmodus_Anf ab.";
CM_ SG_ 2463978616 EM3_Istmodus2 "aktuelle Betriebsart der E-Maschine...
0: Standby; Kommunikation aktiv; aktiver Kurzschluss
1: Momentenreglung
2: Drezahlregeung (interner Regelkreis)
3: Spannungsregelung
4: Drehzahlregelung (externer Regelkreis)
5: interner Inverter Fehler; angefo";
CM_ SG_ 2463978616 EM3_Status_Spgfreiheit "0 = Init (ohne Funktion)
1 = Leistungselektronik HV-Komponenten spannungsfrei (U_Zwkr < 20V)
2 = Leistungselektronik HV_Komponenten nicht spannungsfrei (U_Zwkr >= 20V)
3 = Fehler (z. B. Fehler in der Sensorik)";

CM_ SG_ 2589283600 EMG_CALID_CVN_MUX "Alle CALID-Indizes bilden zusammen die CALID";
CM_ SG_ 2589283600 EMG_CALID_Index_01 "Software-Calibration-Identification (CALID) im ASCII-Zeichenformat; 
für Ausgabe an das Generic Scan-Tool für OBD in NAR

0x30 entspricht ASCII '0'";
CM_ SG_ 2589283600 EMG_CALID_Index_02 "Software-Calibration-Identification (CALID) im ASCII-Zeichenformat; 
für Ausgabe an das Generic Scan-Tool für OBD in NAR

0x30 entspricht ASCII '0'";
CM_ SG_ 2589283600 EMG_CALID_Index_03 "Software-Calibration-Identification (CALID) im ASCII-Zeichenformat; 
für Ausgabe an das Generic Scan-Tool für OBD in NAR

0x30 entspricht ASCII '0'";
CM_ SG_ 2589283600 EMG_CALID_Index_04 "Software-Calibration-Identification (CALID) im ASCII-Zeichenformat; 
für Ausgabe an das Generic Scan-Tool für OBD in NAR

0x30 entspricht ASCII '0'";
CM_ SG_ 2589283600 EMG_CALID_Index_05 "Software-Calibration-Identification (CALID) im ASCII-Zeichenformat; 
für Ausgabe an das Generic Scan-Tool für OBD in NAR

0x30 entspricht ASCII '0'";
CM_ SG_ 2589283600 EMG_CALID_Index_06 "Software-Calibration-Identification (CALID) im ASCII-Zeichenformat; 
für Ausgabe an das Generic Scan-Tool für OBD in NAR

0x30 entspricht ASCII '0'";
CM_ SG_ 2589283600 EMG_CALID_Index_07 "Software-Calibration-Identification (CALID) im ASCII-Zeichenformat; 
für Ausgabe an das Generic Scan-Tool für OBD in NAR

0x30 entspricht ASCII '0'";
CM_ SG_ 2589283600 EMG_CALID_Index_08 "Software-Calibration-Identification (CALID) im ASCII-Zeichenformat; 
für Ausgabe an das Generic Scan-Tool für OBD in NAR

0x30 entspricht ASCII '0'";
CM_ SG_ 2589283600 EMG_CALID_Index_09 "Software-Calibration-Identification (CALID) im ASCII-Zeichenformat; 
für Ausgabe an das Generic Scan-Tool für OBD in NAR

0x30 entspricht ASCII '0'";
CM_ SG_ 2589283600 EMG_CALID_Index_10 "Software-Calibration-Identification (CALID) im ASCII-Zeichenformat; 
für Ausgabe an das Generic Scan-Tool für OBD in NAR

0x30 entspricht ASCII '0'";
CM_ SG_ 2589283600 EMG_CALID_Index_11 "Software-Calibration-Identification (CALID) im ASCII-Zeichenformat; 
für Ausgabe an das Generic Scan-Tool für OBD in NAR

0x30 entspricht ASCII '0'";
CM_ SG_ 2589283600 EMG_CALID_Index_12 "Software-Calibration-Identification (CALID) im ASCII-Zeichenformat; 
für Ausgabe an das Generic Scan-Tool für OBD in NAR

0x30 entspricht ASCII '0'";
CM_ SG_ 2589283600 EMG_CALID_Index_13 "Software-Calibration-Identification (CALID) im ASCII-Zeichenformat; 
für Ausgabe an das Generic Scan-Tool für OBD in NAR

0x30 entspricht ASCII '0'";
CM_ SG_ 2589283600 EMG_CALID_Index_14 "Software-Calibration-Identification (CALID) im ASCII-Zeichenformat; 
für Ausgabe an das Generic Scan-Tool für OBD in NAR

0x30 entspricht ASCII '0'";
CM_ SG_ 2589283600 EMG_CALID_Index_15 "Software-Calibration-Identification (CALID) im ASCII-Zeichenformat; 
für Ausgabe an das Generic Scan-Tool für OBD in NAR

0x30 entspricht ASCII '0'";
CM_ SG_ 2589283600 EMG_CALID_Index_16 "Software-Calibration-Identification (CALID) im ASCII-Zeichenformat; 
für Ausgabe an das Generic Scan-Tool für OBD in NAR

0x30 entspricht ASCII '0'";
CM_ SG_ 2589283600 EMG_CVN_Byte_1 "Calibration Verification Number (CVN bzw. Checksumme) des SW- und Datenstandes; 
für Ausgabe an das Generic Scan-Tool für OBD in NAR";
CM_ SG_ 2589283600 EMG_CVN_Byte_2 "Calibration Verification Number (CVN bzw. Checksumme) des SW- und Datenstandes; 
für Ausgabe an das Generic Scan-Tool für OBD in NAR";
CM_ SG_ 2589283600 EMG_CVN_Byte_3 "Calibration Verification Number (CVN bzw. Checksumme) des SW- und Datenstandes; 
für Ausgabe an das Generic Scan-Tool für OBD in NAR";
CM_ SG_ 2589283600 EMG_CVN_Byte_4 "Calibration Verification Number (CVN bzw. Checksumme) des SW- und Datenstandes; 
für Ausgabe an das Generic Scan-Tool für OBD in NAR";
CM_ SG_ 2589283600 EMG_CVN_VLD "Valid-Bit der Calibration-Verification-Number (CVN bzw. Checksumme)";

CM_ SG_ 2589283495 EMG_Komponentenfehler_01 "Übertragung OBD relevanter Fehlerpfade vom Secondary zum Primary Steuergerät. 
Zuordnung der generischen Komponentenfehler muss zwischen Sender und Empfänger abgestimmt werden.";
CM_ SG_ 2589283495 EMG_Komponentenfehler_02 "Übertragung OBD relevanter Fehlerpfade vom Secondary zum Primary Steuergerät. 
Zuordnung der generischen Komponentenfehler muss zwischen Sender und Empfänger abgestimmt werden.";
CM_ SG_ 2589283495 EMG_Komponentenfehler_03 "Übertragung OBD relevanter Fehlerpfade vom Secondary zum Primary Steuergerät. 
Zuordnung der generischen Komponentenfehler muss zwischen Sender und Empfänger abgestimmt werden.";
CM_ SG_ 2589283495 EMG_Komponentenfehler_04 "Übertragung OBD relevanter Fehlerpfade vom Secondary zum Primary Steuergerät. 
Zuordnung der generischen Komponentenfehler muss zwischen Sender und Empfänger abgestimmt werden.";
CM_ SG_ 2589283495 EMG_Komponentenfehler_05 "Übertragung OBD relevanter Fehlerpfade vom Secondary zum Primary Steuergerät. 
Zuordnung der generischen Komponentenfehler muss zwischen Sender und Empfänger abgestimmt werden.";
CM_ SG_ 2589283495 EMG_Komponentenfehler_06 "Übertragung OBD relevanter Fehlerpfade vom Secondary zum Primary Steuergerät. 
Zuordnung der generischen Komponentenfehler muss zwischen Sender und Empfänger abgestimmt werden.";
CM_ SG_ 2589283495 EMG_Komponentenfehler_07 "Übertragung OBD relevanter Fehlerpfade vom Secondary zum Primary Steuergerät. 
Zuordnung der generischen Komponentenfehler muss zwischen Sender und Empfänger abgestimmt werden.";
CM_ SG_ 2589283495 EMG_Komponentenfehler_08 "Übertragung OBD relevanter Fehlerpfade vom Secondary zum Primary Steuergerät. 
Zuordnung der generischen Komponentenfehler muss zwischen Sender und Empfänger abgestimmt werden.";
CM_ SG_ 2589283495 EMG_Komponentenfehler_09 "Übertragung OBD relevanter Fehlerpfade vom Secondary zum Primary Steuergerät. 
Zuordnung der generischen Komponentenfehler muss zwischen Sender und Empfänger abgestimmt werden.";
CM_ SG_ 2589283495 EMG_Komponentenfehler_VLD "Valid-Bit der OBD-Komponentenfehler. Das Bit wird beim Fehlerspeicher löschen zurückgenommen und erst wieder gesetzt, wenn der Fehlerspeicher vollständig gelöscht wurde. Der Primary-OBD-ECU soll damit mitgeteilt werden, ob sie den Inhalten der Komponenten";

CM_ SG_ 278 ESP_10_BZ "Botschaftszähler

Wird im Projekt D4 und D4Hybrid nicht verwendet!  Wird im D4 PA verwendet
Botschaft asynchron geroutet. Zählerwert kann springen.";
CM_ SG_ 278 ESP_10_CRC "Für MLB:
'Berechnung siehe Lastenheft 'Kommunikationsabsicherung für FlexRay und CAN''

Ab MQB und MLBevo:
'Berechnung siehe Lastenheft 'End-to-End Kommunikationsabsicherung''

Endwerte siehe Begleitdokument 'S-PDU Kennungsfolgen'

Wird im Projekt";
CM_ SG_ 278 ESP_HL_Fahrtrichtung "Drehrichtung Rad HL

Weiterführende Informationen im Lastenheft spezifiziert und in der entsprechenden Fachabteilung zu erfragen.

Wird im Projekt D4 und D4Hybrid nicht verwendet!  Wird im D4 PA verwendet";
CM_ SG_ 278 ESP_HR_Fahrtrichtung "Drehrichtung Rad HR

Weiterführende Informationen im Lastenheft spezifiziert und in der entsprechenden Fachabteilung zu erfragen.

Wird im Projekt D4 und D4Hybrid nicht verwendet!  Wird im D4 PA verwendet";
CM_ SG_ 278 ESP_QBit_Wegimpuls_HL "Qualifizierungsbit Wegimpulszähler HL

Wird im Projekt D4 und D4Hybrid nicht verwendet!  Wird im D4 PA verwendet";
CM_ SG_ 278 ESP_QBit_Wegimpuls_HR "Qualifizierungsbit Wegimpulszähler HR

Wird im Projekt D4 und D4Hybrid nicht verwendet!  Wird im D4 PA verwendet";
CM_ SG_ 278 ESP_QBit_Wegimpuls_VL "Qualifizierungsbit Wegimpulszähler VL

Wird im Projekt D4 und D4Hybrid nicht verwendet!  Wird im D4 PA verwendet";
CM_ SG_ 278 ESP_QBit_Wegimpuls_VR "Qualifizierungsbit Wegimpulszähler VR

Wird im Projekt D4 und D4Hybrid nicht verwendet!  Wird im D4 PA verwendet";
CM_ SG_ 278 ESP_VL_Fahrtrichtung "Drehrichtung Rad VL

Weiterführende Informationen im Lastenheft spezifiziert und in der entsprechenden Fachabteilung zu erfragen.

Wird im Projekt D4 und D4Hybrid nicht verwendet!  Wird im D4 PA verwendet";
CM_ SG_ 278 ESP_VR_Fahrtrichtung "Drehrichtung Rad VR

Weiterführende Informationen im Lastenheft spezifiziert und in der entsprechenden Fachabteilung zu erfragen.

Wird im Projekt D4 und D4Hybrid nicht verwendet!  Wird im D4 PA verwendet";
CM_ SG_ 278 ESP_Wegimpuls_HL "Wegimpulszähler HL.
Anzahl der Wegimpulse Hinterrad links (steigende und fallende Flanke)
Zähler läuft grundsätzlich vorwärts, auch bei Rückwärtsfahrt.
Nach SG-Reset ist immer, ohne Ausnahme, 1mal der Init Wert 1021 zu senden.

Wird im Projekt D4 und";
CM_ SG_ 278 ESP_Wegimpuls_HR "Wegimpulszähler HR.
Anzahl der Wegimpulse Hinterrad rechts (steigende und fallende Flanke)
Zähler läuft grundsätzlich vorwärts, auch bei Rückwärtsfahrt.
Nach SG-Reset ist immer, ohne Ausnahme, 1mal der Init Wert 1021 zu senden.

Wird im Projekt D4 un";
CM_ SG_ 278 ESP_Wegimpuls_VL "Wegimpulszähler VL.
Anzahl der Wegimpulse Vorderrad links (steigende und fallende Flanke)
Zähler läuft grundsätzlich vorwärts, auch bei Rückwärtsfahrt.
Nach SG-Reset ist immer, ohne Ausnahme, 1mal der Init Wert 1021 zu senden.

Wird im Projekt D4 und";
CM_ SG_ 278 ESP_Wegimpuls_VR "Wegimpulszähler VR.
Anzahl der Wegimpulse Vorderrad rechts (steigende und fallende Flanke)
Zähler läuft grundsätzlich vorwärts, auch bei Rückwärtsfahrt.
Nach SG-Reset ist immer, ohne Ausnahme, 1mal der Init Wert 1021 zu senden.

Wird im Projekt D4 un";

CM_ SG_ 418 ESP_15_BZ "Botschaftszähler
Botschaft asynchron geroutet. Zählerwert kann springen.";
CM_ SG_ 418 ESP_15_CRC "Für MLB:
'Berechnung siehe Lastenheft 'Kommunikationsabsicherung für FlexRay und CAN''

Ab MQB und MLBevo:
'Berechnung siehe Lastenheft 'End-to-End Kommunikationsabsicherung''

Endwerte siehe Begleitdokument 'S-PDU Kennungsfolgen'

Wird im Projekt";
CM_ SG_ 418 ESP_Haltemoment "Zeigt in Abhängigkeit von ESP_Index_Haltemoment das notwendige Summen-Radmoment an (bergab: Bremsmoment; bergauf: Antriebsmoment), das mindestens notwendig ist um das Fahrzeug an der aktuellen Neigung zu halten.";
CM_ SG_ 418 ESP_Index_Haltemoment "Zeigt an, ob das Summen-Radmoment von ESP_Haltemoment ein Bremsmoment (bergab) oder ein Antriebsmoment (bergauf) darstellt.";
CM_ SG_ 418 HMS_aktives_System "Zeigt an, von welchem System die Anforderung gerade umgesetzt wird.";
CM_ SG_ 418 HMS_Anforderung_GE "Fordert vom Getriebe bestimmte Schaltstellungen an.";
CM_ SG_ 418 HMS_Fehlerstatus "Zeigt den Fehlerstatus des Haltemanagementsystems HMS an.
Details zu den Werten 3/4:
3=Systemeinschränkung, Parken EPB oder GSG nicht möglich
4=Systemstörung bzw. Parken EPB und GSG nicht möglich  ";
CM_ SG_ 418 HMS_halten_nicht_verfuegbar "Rueckmeldung HMS-Teilfunktion 'Halten' nicht verfuegbar.";
CM_ SG_ 418 HMS_Konsistenz_ACC "Zeigt an, ob die Kommunikation und die Anforderungen plausibel sind.";
CM_ SG_ 418 HMS_Konsistenz_GE "Zeigt an, ob die Kommunikation und die Anforderungen plausibel sind.";
CM_ SG_ 418 HMS_Konsistenz_HVLM "Zeigt an, ob die Kommunikation und die Anforderungen plausibel sind.";
CM_ SG_ 418 HMS_Konsistenz_IPA "Zeigt an, ob die Kommunikation und die Anforderungen plausibel sind.
";
CM_ SG_ 418 HMS_Konsistenz_MO "Zeigt an, ob die Kommunikation und die Anforderungen plausibel sind.";
CM_ SG_ 418 HMS_Konsistenz_STA "Zeigt an, ob die Kommunikation und die Anforderungen plausibel sind.";
CM_ SG_ 418 HMS_Notstopp_Status "Statusinformation des Notstoppsystems an die beteiligten Systeme.";
CM_ SG_ 418 HMS_P_beibehalten_GE "Fordert das Getriebe auf in Stellung 'P' zu bleiben.";
CM_ SG_ 418 HMS_parken_nicht_verfuegbar "Rueckmeldung HMS-Teilfunktionen 'Parken' nicht verfuegbar.";
CM_ SG_ 418 HMS_Stillstand "Das Signal zeigt, basierend auf den vier ESP-Raddrehzahlinformatioen, gefiltert und/oder entprellt mehrstufig den Fahrzeuggeschwindigkeitszustand an.";
CM_ SG_ 418 HMS_Systemstatus "Zeigt den aktuellen Systemstatus des HMS an.";
CM_ SG_ 418 NL_PRIM_STP_01_Status "Das Primär- Bremsregelsystem übermittelt seinen Systemstatus an zFAS und Sekundär- Bremsregelsystem. 

Der Staupilot ermittelt sich über den Status des Primär-und des Sekundärbremsregelsystems den Gesamtzustand des Notlaufreglers.";
CM_ SG_ 418 VMM_Warnblinken "Über dieses Signal wird ein Warnblinken von Funktionen des VMM (VehicleMotionManagers) angefordert.";
CM_ SG_ 418 VZM_Status "Zeigt die Verfuegbarkeit und den Zustand der VZM Funktionen im ESC an";

CM_ SG_ 1629 BR_QBit_Reifenumfang "Gesetzt bei Ersatzwert, Init oder Fehler.";
CM_ SG_ 1629 BR_Reifenumfang "Mittlerer Radumfang gerechnet in Millimeter.
Von der Bremse plausibilisierter Wert (Kopie von KBI_Reifenumfang wenn dieser plausibel) oder Ersatzwert aus Bremse wenn KBI_Reifenumfang unplausibel. Bitte das QBit beachten!";
CM_ SG_ 1629 BR_Systemart "Identifikation des verbauten Bremssystems

Dient dem Kombi zur Plausibilisierung";
CM_ SG_ 1629 ESP_20_BZ "Botschaft asynchron geroutet. Zählerwert kann springen.";
CM_ SG_ 1629 ESP_20_CRC "Für MLB:
'Berechnung siehe Lastenheft 'Kommunikationsabsicherung für FlexRay und CAN''

Ab MQB und MLBevo:
'Berechnung siehe Lastenheft 'End-to-End Kommunikationsabsicherung''

Endwerte siehe Begleitdokument 'S-PDU Kennungsfolgen'";
CM_ SG_ 1629 ESP_Charisma_FahrPr "MLBevo: Aktuelles Fahrprogramm des Charisma-Teilnehmers (siehe Systemlastenheft Drive Select)
MQB: Istwert der Kennlinie (siehe Systemlastenheft MQB FPA)";
CM_ SG_ 1629 ESP_Charisma_Status "Systemstatus des Charismateilnehmers

Wert 0x3 ist nur für Fahrzeuge ab MQB relevant";
CM_ SG_ 1629 ESP_Dachrelingsensor "Erkennung auf Verbau des Dachrelingsensors und Dachquerträger.";
CM_ SG_ 1629 ESP_SpannungsAnf_02 "Forderung des ESP-SG's zur Spannungsanhebung.";
CM_ SG_ 1629 ESP_Stoppverbot_Anz_01 "Dieses Signal gibt die detaillierte Begründung für ein Stoppverbot vom Bremsensteuergerät an.";
CM_ SG_ 1629 ESP_Stoppverbot_Anz_02 "Dieses Signal gibt die detaillierte Begründung für ein Stoppverbot vom Bremsensteuergerät an.";
CM_ SG_ 1629 ESP_Stoppverbot_Anz_03 "Dieses Signal gibt die detaillierte Begründung für ein Stoppverbot vom Bremsensteuergerät an.";
CM_ SG_ 1629 ESP_Stoppverbot_Anz_04 "Dieses Signal gibt die detaillierte Begründung für ein Stoppverbot vom Bremsensteuergerät an.";
CM_ SG_ 1629 ESP_Stoppverbot_Anz_05 "Dieses Signal gibt die detaillierte Begründung für ein Stoppverbot vom Bremsensteuergerät an.";
CM_ SG_ 1629 ESP_Stoppverbot_Anz_06 "Dieses Signal gibt die detaillierte Begründung für ein Stoppverbot vom Bremsensteuergerät an.";
CM_ SG_ 1629 ESP_Stoppverbot_Anz_07 "Dieses Signal gibt die detaillierte Begründung für ein Stoppverbot vom Bremsensteuergerät an.";
CM_ SG_ 1629 ESP_Stoppverbot_Anz_08 "Dieses Signal gibt die detaillierte Begründung für ein Stoppverbot vom Bremsensteuergerät an.";
CM_ SG_ 1629 ESP_Stoppverbot_Anz_Std "Dieses Signal gibt die detaillierte Begründung für ein Stoppverbot vom Bremsensteuergerät an.";
CM_ SG_ 1629 ESP_Wiederstart_Anz_01 "Dieses Signal gibt die detaillierte Begründung für einen Wiederstart vom Bremsensteuergerät an. ";
CM_ SG_ 1629 ESP_Wiederstart_Anz_02 "Dieses Signal gibt die detaillierte Begründung für einen Wiederstart vom Bremsensteuergerät an. ";
CM_ SG_ 1629 ESP_Wiederstart_Anz_03 "Dieses Signal gibt die detaillierte Begründung für einen Wiederstart vom Bremsensteuergerät an. ";
CM_ SG_ 1629 ESP_Wiederstart_Anz_04 "Dieses Signal gibt die detaillierte Begründung für einen Wiederstart vom Bremsensteuergerät an.";
CM_ SG_ 1629 ESP_Zaehnezahl "Konstanter Wert der Zähnezahl des verwendeten Impulsrades wird ausgegeben, jeder Empfänger der Wegimpulse muss die Zähnezahl einlesen, um eine volle Umdrehung des Rades zu erkennen. 

Weiterführende Informationen im Lastenheft spezifiziert und in der en";
CM_ SG_ 1629 HDC_Charisma_FahrPr "MLBevo: Aktuelles Fahrprogramm des Charisma-Teilnehmers (siehe Systemlastenheft Drive Select)
MQB: Istwert der Kennlinie (siehe Systemlastenheft MQB FPA)";
CM_ SG_ 1629 HDC_Charisma_Status "Systemstatus des Charismateilnehmers

Wert 0x3 ist nur für Fahrzeuge ab MQB relevant";

CM_ SG_ 253 ABS_Bremsung "Antiblockiersystem, Bit zeigt auch Druckabbau an (z.B. ESP hat zuviel Druck aufgebaut oder ungebremste Regelung auf Bahnübergang)
Weiterführende Informationen im Lastenheft spezifiziert und in der entsprechenden Fachabteilung zu erfragen.";
CM_ SG_ 253 ASR_Anf "MLB: Die Momentenanforderung 'ASR_MSR_Moment_schnell' und 'ASR_Moment_langsam' sind auszuführen
MQB: Die Momentenanforderung 'BR_Eingriffsmoment' ist auszuführen";
CM_ SG_ 253 ASR_Schalteingriff "Wunsch an das Getriebe während einer ASR Regelung

MLB: Es wird nur 0x0 und 0x1 genutzt

";
CM_ SG_ 253 ASR_Tastung_passiv "ASR deaktiviert oder Schwellen geändert (projektabhängig)
Weiterführende Informationen im Lastenheft spezifiziert und in der entsprechenden Fachabteilung zu erfragen.
";
CM_ SG_ 253 BR_Eingriffsmoment "Einheitenloser Wert! Faktor in MO_Faktor_Momente_02 in Motor_Code_01 beachten!
Schnelle reduzierende (ASR) oder erhöhende (MSR) Momentanforderung an den Motor.";
CM_ SG_ 253 EBV_Eingriff "Elektronische Bremskraftverteilung, aktueller Eingriff (Druckhalten, Druckabbau)

Im MLB: kein ABS / ESP-Eingriff ???";
CM_ SG_ 253 EDS_Eingriff "Elektronische Differentialsperre";
CM_ SG_ 253 ESC_Neutralschaltung "Aufforderung seitens ABS an das Getriebe die Momentenübertragung zu unterbrechen";
CM_ SG_ 253 ESC_v_Signal_Qualifier_High_Low "Das Qualifizerungssignal ESC_v_Signal_Qualifier_High_Low gibt eine Information über die Güte der vom Bremsregelsystem ausgegebenen Geschwindigkeitsinformation 'mittlere Geschwindigkeit', wobei Vertrauensbereiche für das ausgegebene Geschwindigkeitssignal ";
CM_ SG_ 253 ESP_21_CRC "Für MLB:
'Berechnung siehe Lastenheft 'Kommunikationsabsicherung für FlexRay und CAN''

Ab MQB und MLBevo:
'Berechnung siehe Lastenheft 'End-to-End Kommunikationsabsicherung''

Endwerte siehe Begleitdokument 'S-PDU Kennungsfolgen'";
CM_ SG_ 253 ESP_ASP "MLB: Anhaenger-Stabilisierungs-Programm
MQB: Gespannstabilisierung";
CM_ SG_ 253 ESP_Diagnose "MLB: Nach Diagnoseende wird ein SW-Reset ausgelöst welcher einen Kommunikatiosausfall für max. 150ms verursacht. Dies ist bei SG mit verschärfter Timeoutüberwachung (nicht nach Konzern-LH) zu beachten.

MQB: Weiterführende Informationen im Lastenheft sp";
CM_ SG_ 253 ESP_Eingriff "Eingriff des Fahrdynamikreglers";
CM_ SG_ 253 ESP_QBit_v_Signal "Geschwindigkeit wird vom ABS/ASR oder ESP aus Ersatzwerten errechnet, wenn Bit gesetzt ist. Güte des Signals ist verändert.";
CM_ SG_ 253 ESP_Systemstatus "Fehler steht für Stillegung ESP mit Fehlereintrag.

MLB: Flag wird bei Unterspannung im Stand bis einmalig 6km/h (AU48x) oder 10 km/h (AU641, AU57x) überschritten nicht gesetzt (Ausblendung Startvorgang)
Im AU64x, AU57x gilt ESP D4 Funktionsanforderung";
CM_ SG_ 253 ESP_Tastung_passiv "ESP deaktiviert oder Schwellen geändert (projektabhängig)
Weiterführende Informationen im Lastenheft spezifiziert und in der entsprechenden Fachabteilung zu erfragen.";
CM_ SG_ 253 ESP_v_Signal "Geschwindigkeitssignal vom ABS/ASR oder ESP. Mittelwert der angetriebenen Räder.
Bei MSR oder ABS Eingriffen wird die ABS-Referenzgeschwindigkeit für >= 200ms eingespiegelt (Zeit wird mit Aktiv-Flanke der Funktionsbits getriggert)

MQB: Bei Frontantrie";
CM_ SG_ 253 ESP_Vorsteuerung "zur Unterscheidung zwischen ESP-Vorsteuermaßnahmen und ESP-Regeleingriffen";
CM_ SG_ 253 MSR_Anf "MLB: Die Momentenanforderung 'ASR_MSR_Moment_schnell' ist auszuführen.
MQB: Die Momentenanforderung 'BR_Eingriffsmoment' ist auszuführen";
CM_ SG_ 253 OBD_Schlechtweg "Für Ausblendung der Zündaussetzererkennung im Motorsteuergerät (Otto). Bit wird gesetzt, wenn Rad-Drehbeschleunigung im ESP > Grenzwert ist. Vorteil gegenüber Radgeschwindigkeiten, dass ESP alle 2 ms dynamisch die Rad-Drehbeschleunigung errechnet und dem ";

CM_ SG_ 2463978667 ESC_Anf_Mindestreku "Bei Wert == 1 soll durch den Antrieb eine im Projekt definierte Mindestrekuperationsleistung des E-Antriebs zur Anforderung durch das Bremssystem schnellst möglich frei gegeben werden. Dies dient zur Entlastung der Reibbremse.";
CM_ SG_ 2463978667 ESC_Status_Schaltkennfeld_sek "Das Signal qualifiziert Wunscheingriffe auf die Getriebeschaltstrategie der sekundären Achse! Signal zur Verwendung im B9 PHEV mit e-quattro Antriebsstrang!";
CM_ SG_ 2463978667 ESCGeneratorSollMoment "In MLBevo Faktor in TS_Faktor_Radmomente beachten!

Verzögernd wirkender Antriebsstrangsollmomentenanteil aus Bremspedalbetätigung auf Summenradebene.";
CM_ SG_ 2463978667 ESP_25_BZ "Botschaftszaehler
Botschaft asynchron geroutet. Zählerwert kann springen.";
CM_ SG_ 2463978667 ESP_25_CRC "Für MLB:
'Berechnung siehe Lastenheft 'Kommunikationsabsicherung für FlexRay und CAN''

Ab MQB und MLBevo:
'Berechnung siehe Lastenheft 'End-to-End Kommunikationsabsicherung''

Endwerte siehe Begleitdokument 'S-PDU Kennungsfolgen'";
CM_ SG_ 2463978667 ESP_M_hyd_anteil_Bremse "- Sollmoment hydraulisch bei Rekuperation 
- evtl. Sollmoment hydraulisch bei aktiven Druckaufbauten über eBKV
- Summenradmoment";
CM_ SG_ 2463978667 TSMomBegrenzung "In MLBevo Faktor in TS_Faktor_Radmomente beachten!

Begrenzung des verzögernd wirkenden Antriebsstrangsollmomentenanteil auf Summenradebene";
BA_DEF_REL_ BU_SG_REL_  "GenSigTimeoutTime" INT 0 65535;
BA_DEF_ BO_  "DiagRequest" ENUM "No", "Yes";
BA_DEF_ BO_  "DiagResponse" ENUM "No", "Yes";
BA_DEF_ BO_  "DiagState" ENUM "No", "Yes";
BA_DEF_ BO_  "GenMsgChkConstant" HEX 0 4095;
BA_DEF_ BO_  "GenMsgCycleTime" INT 0 65535;
BA_DEF_ BO_  "GenMsgCycleTimeFast" INT 0 65535;
BA_DEF_ BO_  "GenMsgDelayTime" INT 0 100000;
BA_DEF_ BO_  "GenMsgILSupport" ENUM "No", "Yes";
BA_DEF_ BO_  "GenMsgNrOfRepetition" INT 0 100;
BA_DEF_ BO_  "GenMsgPDUConstants" STRING;
BA_DEF_ BO_  "GenMsgSendType" ENUM "Cyclic", "not_used", "not_used", "not_used", "not_used", "not_used", "not_used", "IfActive", "NoMsgSendType";
BA_DEF_ BO_  "GenMsgStartDelayTime" INT 0 100000;
BA_DEF_ BO_  "NmMessage" ENUM "No", "Yes";
BA_DEF_ BO_  "NmhMessage" ENUM "No", "Yes";
BA_DEF_ BO_  "MsgType" ENUM "Application", "NM ", "NMH", "TP2.0", "ISO-TP ", "BAP", "EID", "KS";
BA_DEF_ BO_  "VAGTP20_API" HEX 0 255;
BA_DEF_ BO_  "VAGTP20_DynConnection" ENUM "No", "Yes";
BA_DEF_ BO_  "VAGTP20_DynSetup" ENUM "No", "Yes";
BA_DEF_ BO_  "VAGTP20_StatConnection" ENUM "No", "Yes";
BA_DEF_ SG_  "GenSigActiveRepetitions" INT -2147483648 2147483647;
BA_DEF_ SG_  "GenSigInactiveValue" INT -2147483648 2147483647;
BA_DEF_ SG_  "GenSigSendType" ENUM "Cyclic", "OnWrite", "OnWriteWithRepetition", "OnChange", "OnChangeWithRepetition", "IfActive", "IfActiveWithRepetition", "NoSigSendType", "OnChangeAndIfActive", "OnChangeAndIfActiveWithRepetition";
BA_DEF_ SG_  "GenSigStartValue" INT -2147483648 2147483647;
BA_DEF_ SG_  "NWM-WakeupAllowed" ENUM "No", "Yes";
BA_DEF_ SG_  "GenSigFuncType" ENUM "NoFunction", "MsgCounter", "CRC-8", "XOR", "XOR-2", "DatedBit", "SW-Kl15", "CHK", "Constant", "Protocol", "CRC-8-SAE_J1850";
BA_DEF_ SG_  "GenSigSwitchedByIgnition" ENUM "No", "Yes";
BA_DEF_ SG_  "Fehlerwert" HEX 0 2147483647;
BA_DEF_ SG_  "GenSigMissingSourceValue" HEX 0 2147483647;
BA_DEF_DEF_REL_  "GenSigTimeoutTime" 0;
BA_DEF_DEF_  "DiagRequest" "No";
BA_DEF_DEF_  "DiagResponse" "No";
BA_DEF_DEF_  "DiagState" "No";
BA_DEF_DEF_  "GenMsgChkConstant" 0;
BA_DEF_DEF_  "GenMsgCycleTime" 0;
BA_DEF_DEF_  "GenMsgCycleTimeFast" 0;
BA_DEF_DEF_  "GenMsgDelayTime" 0;
BA_DEF_DEF_  "GenMsgILSupport" "No";
BA_DEF_DEF_  "GenMsgNrOfRepetition" 0;
BA_DEF_DEF_  "GenMsgPDUConstants" "";
BA_DEF_DEF_  "GenMsgSendType" "NoMsgSendType";
BA_DEF_DEF_  "GenMsgStartDelayTime" 0;
BA_DEF_DEF_  "NmMessage" "No";
BA_DEF_DEF_  "NmhMessage" "No";
BA_DEF_DEF_  "MsgType" "Application";
BA_DEF_DEF_  "VAGTP20_API" 0;
BA_DEF_DEF_  "VAGTP20_DynConnection" "No";
BA_DEF_DEF_  "VAGTP20_DynSetup" "No";
BA_DEF_DEF_  "VAGTP20_StatConnection" "No";
BA_DEF_DEF_  "GenSigActiveRepetitions" 0;
BA_DEF_DEF_  "GenSigInactiveValue" 0;
BA_DEF_DEF_  "GenSigSendType" "NoSigSendType";
BA_DEF_DEF_  "GenSigStartValue" 0;
BA_DEF_DEF_  "NWM-WakeupAllowed" "No";
BA_DEF_DEF_  "GenSigFuncType" "NoFunction";
BA_DEF_DEF_  "GenSigSwitchedByIgnition" "Yes";
BA_DEF_DEF_  "Fehlerwert" 0;
BA_DEF_DEF_  "GenSigMissingSourceValue" 0;
BA_ "GenMsgCycleTime" BO_ 2617119266 2000;
BA_ "GenMsgILSupport" BO_ 2617119266 1;
BA_ "GenMsgSendType" BO_ 2617119266 0;
BA_ "GenMsgCycleTime" BO_ 2617119267 2000;
BA_ "GenMsgILSupport" BO_ 2617119267 1;
BA_ "GenMsgSendType" BO_ 2617119267 0;
BA_ "GenMsgCycleTime" BO_ 2617119268 2000;
BA_ "GenMsgILSupport" BO_ 2617119268 1;
BA_ "GenMsgSendType" BO_ 2617119268 0;
BA_ "GenMsgCycleTime" BO_ 2617119269 100;
BA_ "GenMsgILSupport" BO_ 2617119269 1;
BA_ "GenMsgSendType" BO_ 2617119269 0;
BA_ "GenMsgCycleTime" BO_ 2617119270 2000;
BA_ "GenMsgILSupport" BO_ 2617119270 1;
BA_ "GenMsgSendType" BO_ 2617119270 0;
BA_ "GenMsgCycleTime" BO_ 2617119271 2000;
BA_ "GenMsgILSupport" BO_ 2617119271 1;
BA_ "GenMsgSendType" BO_ 2617119271 0;
BA_ "GenMsgCycleTime" BO_ 2617119272 2000;
BA_ "GenMsgILSupport" BO_ 2617119272 1;
BA_ "GenMsgSendType" BO_ 2617119272 0;
BA_ "GenMsgCycleTime" BO_ 2617119273 2000;
BA_ "GenMsgILSupport" BO_ 2617119273 1;
BA_ "GenMsgSendType" BO_ 2617119273 0;
BA_ "GenMsgCycleTime" BO_ 2617119274 2000;
BA_ "GenMsgILSupport" BO_ 2617119274 1;
BA_ "GenMsgSendType" BO_ 2617119274 0;
BA_ "GenMsgCycleTime" BO_ 2617119275 100;
BA_ "GenMsgILSupport" BO_ 2617119275 1;
BA_ "GenMsgSendType" BO_ 2617119275 0;
BA_ "GenMsgCycleTime" BO_ 2617119276 2000;
BA_ "GenMsgILSupport" BO_ 2617119276 1;
BA_ "GenMsgSendType" BO_ 2617119276 0;
BA_ "GenMsgCycleTime" BO_ 2617119277 2000;
BA_ "GenMsgILSupport" BO_ 2617119277 1;
BA_ "GenMsgSendType" BO_ 2617119277 0;
BA_ "GenMsgCycleTime" BO_ 2617119278 2000;
BA_ "GenMsgILSupport" BO_ 2617119278 1;
BA_ "GenMsgSendType" BO_ 2617119278 0;
BA_ "GenMsgCycleTime" BO_ 2617119279 2000;
BA_ "GenMsgILSupport" BO_ 2617119279 1;
BA_ "GenMsgSendType" BO_ 2617119279 0;
BA_ "GenMsgCycleTime" BO_ 2617119280 2000;
BA_ "GenMsgILSupport" BO_ 2617119280 1;
BA_ "GenMsgSendType" BO_ 2617119280 0;
BA_ "GenMsgCycleTime" BO_ 2617119281 100;
BA_ "GenMsgILSupport" BO_ 2617119281 1;
BA_ "GenMsgSendType" BO_ 2617119281 0;
BA_ "GenMsgCycleTime" BO_ 2617119282 2000;
BA_ "GenMsgILSupport" BO_ 2617119282 1;
BA_ "GenMsgSendType" BO_ 2617119282 0;
BA_ "GenMsgCycleTime" BO_ 2617119283 2000;
BA_ "GenMsgILSupport" BO_ 2617119283 1;
BA_ "GenMsgSendType" BO_ 2617119283 0;
BA_ "GenMsgCycleTime" BO_ 2617119284 100;
BA_ "GenMsgILSupport" BO_ 2617119284 1;
BA_ "GenMsgSendType" BO_ 2617119284 0;
BA_ "GenMsgCycleTime" BO_ 2617119285 100;
BA_ "GenMsgILSupport" BO_ 2617119285 1;
BA_ "GenMsgSendType" BO_ 2617119285 0;
BA_ "GenMsgCycleTime" BO_ 2617119286 100;
BA_ "GenMsgILSupport" BO_ 2617119286 1;
BA_ "GenMsgSendType" BO_ 2617119286 0;
BA_ "GenMsgCycleTime" BO_ 2617119287 100;
BA_ "GenMsgILSupport" BO_ 2617119287 1;
BA_ "GenMsgSendType" BO_ 2617119287 0;
BA_ "GenMsgCycleTime" BO_ 2617119288 100;
BA_ "GenMsgILSupport" BO_ 2617119288 1;
BA_ "GenMsgSendType" BO_ 2617119288 0;
BA_ "GenMsgCycleTime" BO_ 2617119289 100;
BA_ "GenMsgILSupport" BO_ 2617119289 1;
BA_ "GenMsgSendType" BO_ 2617119289 0;
BA_ "GenMsgCycleTime" BO_ 2617119290 100;
BA_ "GenMsgILSupport" BO_ 2617119290 1;
BA_ "GenMsgSendType" BO_ 2617119290 0;
BA_ "GenMsgCycleTime" BO_ 2617119291 100;
BA_ "GenMsgILSupport" BO_ 2617119291 1;
BA_ "GenMsgSendType" BO_ 2617119291 0;
BA_ "GenMsgCycleTime" BO_ 2617119292 2000;
BA_ "GenMsgILSupport" BO_ 2617119292 1;
BA_ "GenMsgSendType" BO_ 2617119292 0;
BA_ "MsgType" BO_ 2617119487 6;
BA_ "MsgType" BO_ 2549880528 4;
BA_ "MsgType" BO_ 2550011600 4;
BA_ "MsgType" BO_ 2549880529 4;
BA_ "MsgType" BO_ 2550011601 4;
BA_ "MsgType" BO_ 2549880530 4;
BA_ "MsgType" BO_ 2550011602 4;
BA_ "MsgType" BO_ 2549880531 4;
BA_ "MsgType" BO_ 2550011603 4;
BA_ "MsgType" BO_ 2549880532 4;
BA_ "MsgType" BO_ 2550011604 4;
BA_ "MsgType" BO_ 2549880533 4;
BA_ "MsgType" BO_ 2550011605 4;
BA_ "MsgType" BO_ 2549880534 4;
BA_ "MsgType" BO_ 2550011606 4;
BA_ "MsgType" BO_ 2549880535 4;
BA_ "MsgType" BO_ 2550011607 4;
BA_ "MsgType" BO_ 2549880536 4;
BA_ "MsgType" BO_ 2550011608 4;
BA_ "MsgType" BO_ 2549880537 4;
BA_ "MsgType" BO_ 2550011609 4;
BA_ "MsgType" BO_ 2549880538 4;
BA_ "MsgType" BO_ 2550011610 4;
BA_ "MsgType" BO_ 2549880539 4;
BA_ "MsgType" BO_ 2550011611 4;
BA_ "MsgType" BO_ 2549880540 4;
BA_ "MsgType" BO_ 2550011612 4;
BA_ "MsgType" BO_ 2549880561 4;
BA_ "MsgType" BO_ 2550011633 4;
BA_ "MsgType" BO_ 2549880562 4;
BA_ "MsgType" BO_ 2550011634 4;
BA_ "MsgType" BO_ 2549880563 4;
BA_ "MsgType" BO_ 2550011635 4;
BA_ "MsgType" BO_ 2549880413 4;
BA_ "MsgType" BO_ 2550011485 4;
BA_ "MsgType" BO_ 2549880512 4;
BA_ "MsgType" BO_ 2550011584 4;
BA_ "GenMsgCycleTime" BO_ 1714 1000;
BA_ "GenMsgILSupport" BO_ 1714 1;
BA_ "GenMsgSendType" BO_ 1714 0;
BA_ "GenMsgCycleTime" BO_ 1520 200;
BA_ "GenMsgDelayTime" BO_ 1520 50;
BA_ "GenMsgILSupport" BO_ 1520 1;
BA_ "GenMsgSendType" BO_ 1520 0;
BA_ "GenMsgCycleTime" BO_ 1603 1000;
BA_ "GenMsgDelayTime" BO_ 1603 100;
BA_ "GenMsgILSupport" BO_ 1603 1;
BA_ "GenMsgSendType" BO_ 1603 0;
BA_ "GenMsgCycleTime" BO_ 910 320;
BA_ "GenMsgILSupport" BO_ 910 1;
BA_ "GenMsgSendType" BO_ 910 0;
BA_ "GenMsgCycleTime" BO_ 2527679504 320;
BA_ "GenMsgILSupport" BO_ 2527679504 1;
BA_ "GenMsgSendType" BO_ 2527679504 0;
BA_ "GenMsgCycleTime" BO_ 892 480;
BA_ "GenMsgCycleTimeFast" BO_ 892 40;
BA_ "GenMsgDelayTime" BO_ 892 40;
BA_ "GenMsgILSupport" BO_ 892 1;
BA_ "GenMsgNrOfRepetition" BO_ 892 5;
BA_ "GenMsgPDUConstants" BO_ 892 "0xed,0x03,0x1c,0x13,0xc6,0x23,0x78,0x7a,0x8b,0x40,0x14,0x51,0xbf,0x68,0x32,0xba";
BA_ "GenMsgSendType" BO_ 892 0;
BA_ "GenMsgCycleTime" BO_ 2527679648 320;
BA_ "GenMsgILSupport" BO_ 2527679648 1;
BA_ "GenMsgSendType" BO_ 2527679648 0;
BA_ "GenMsgCycleTime" BO_ 2463978615 480;
BA_ "GenMsgCycleTimeFast" BO_ 2463978615 40;
BA_ "GenMsgDelayTime" BO_ 2463978615 40;
BA_ "GenMsgILSupport" BO_ 2463978615 1;
BA_ "GenMsgNrOfRepetition" BO_ 2463978615 5;
BA_ "GenMsgPDUConstants" BO_ 2463978615 "0x41,0x5e,0x7f,0xc7,0xc3,0x04,0x0a,0x11,0x34,0x4d,0x9b,0x27,0xaf,0x0d,0x0f,0x31";
BA_ "GenMsgSendType" BO_ 2463978615 0;
BA_ "GenMsgCycleTime" BO_ 2527679649 320;
BA_ "GenMsgILSupport" BO_ 2527679649 1;
BA_ "GenMsgSendType" BO_ 2527679649 0;
BA_ "GenMsgCycleTime" BO_ 2463978616 480;
BA_ "GenMsgCycleTimeFast" BO_ 2463978616 40;
BA_ "GenMsgDelayTime" BO_ 2463978616 40;
BA_ "GenMsgILSupport" BO_ 2463978616 1;
BA_ "GenMsgNrOfRepetition" BO_ 2463978616 5;
BA_ "GenMsgPDUConstants" BO_ 2463978616 "0xe0,0x2f,0x8d,0x3c,0x70,0x22,0x03,0x60,0x0e,0x18,0xd9,0xeb,0x95,0x63,0xcb,0x76";
BA_ "GenMsgSendType" BO_ 2463978616 0;
BA_ "GenMsgCycleTime" BO_ 2589283600 960;
BA_ "GenMsgILSupport" BO_ 2589283600 1;
BA_ "GenMsgSendType" BO_ 2589283600 0;
BA_ "GenMsgCycleTime" BO_ 2589283495 500;
BA_ "GenMsgILSupport" BO_ 2589283495 1;
BA_ "GenMsgSendType" BO_ 2589283495 0;
BA_ "GenMsgChkConstant" BO_ 278 172;
BA_ "GenMsgCycleTime" BO_ 278 100;
BA_ "GenMsgILSupport" BO_ 278 1;
BA_ "GenMsgPDUConstants" BO_ 278 "0xac,0xac,0xac,0xac,0xac,0xac,0xac,0xac,0xac,0xac,0xac,0xac,0xac,0xac,0xac,0xac";
BA_ "GenMsgSendType" BO_ 278 0;
BA_ "GenMsgCycleTime" BO_ 418 200;
BA_ "GenMsgDelayTime" BO_ 418 20;
BA_ "GenMsgILSupport" BO_ 418 1;
BA_ "GenMsgPDUConstants" BO_ 418 "0xcb,0x47,0xd7,0xd2,0x56,0x3e,0x20,0xea,0x6e,0x6d,0x8c,0x1b,0xdf,0x49,0xaa,0xab";
BA_ "GenMsgSendType" BO_ 418 0;
BA_ "GenMsgStartDelayTime" BO_ 418 20;
BA_ "GenMsgCycleTime" BO_ 1629 1000;
BA_ "GenMsgILSupport" BO_ 1629 1;
BA_ "GenMsgPDUConstants" BO_ 1629 "0xac,0xb3,0xab,0xeb,0x7a,0xe1,0x3b,0xf7,0x73,0xba,0x7c,0x9e,0x06,0x5f,0x02,0xd9";
BA_ "GenMsgSendType" BO_ 1629 0;
BA_ "GenMsgCycleTime" BO_ 253 20;
BA_ "GenMsgILSupport" BO_ 253 1;
BA_ "GenMsgPDUConstants" BO_ 253 "0xb4,0xef,0xf8,0x49,0x1e,0xe5,0xc2,0xc0,0x97,0x19,0x3c,0xc9,0xf1,0x98,0xd6,0x61";
BA_ "GenMsgSendType" BO_ 253 0;
BA_ "GenMsgCycleTime" BO_ 2463978667 1000;
BA_ "GenMsgDelayTime" BO_ 2463978667 10;
BA_ "GenMsgILSupport" BO_ 2463978667 1;
BA_ "GenMsgPDUConstants" BO_ 2463978667 "0xab,0xe1,0x73,0x9e,0x02,0xc2,0x30,0xe9,0x75,0x48,0x2e,0x98,0x7f,0xf5,0xa7,0xb6";
BA_ "GenMsgSendType" BO_ 2463978667 0;
BA_ "GenMsgStartDelayTime" BO_ 2463978667 50;
BA_ "GenSigSendType" SG_ 2617119266 DEV_TME_TmeDem_tAirEvpOut_VW_Data 0;
BA_ "GenSigSwitchedByIgnition" SG_ 2617119266 DEV_TME_TmeDem_tAirEvpOut_VW_Data 0;
BA_ "GenSigSendType" SG_ 2617119266 DEV_TME_TmeEm_tiMaxPreCdnCab_VW_Data 0;
BA_ "GenSigSwitchedByIgnition" SG_ 2617119266 DEV_TME_TmeEm_tiMaxPreCdnCab_VW_Data 0;
BA_ "GenSigSendType" SG_ 2617119266 DEV_TME_TmeEm_tiPsblPreCdnCabEl_VW_Data 0;
BA_ "GenSigSwitchedByIgnition" SG_ 2617119266 DEV_TME_TmeEm_tiPsblPreCdnCabEl_VW_Data 0;
BA_ "GenSigSendType" SG_ 2617119266 DEV_TME_TmeDiag_idxDiagFan2ExtFail_VW_Data 0;
BA_ "GenSigSwitchedByIgnition" SG_ 2617119266 DEV_TME_TmeDiag_idxDiagFan2ExtFail_VW_Data 0;
BA_ "GenSigSendType" SG_ 2617119266 DEV_TME_TmeDiag_idxDiagFan2BlockSrv_VW_Data 0;
BA_ "GenSigSwitchedByIgnition" SG_ 2617119266 DEV_TME_TmeDiag_idxDiagFan2BlockSrv_VW_Data 0;
BA_ "GenSigSendType" SG_ 2617119266 DEV_TME_TmeDiag_idxDiagFan1ExtFail_VW_Data 0;
BA_ "GenSigSwitchedByIgnition" SG_ 2617119266 DEV_TME_TmeDiag_idxDiagFan1ExtFail_VW_Data 0;
BA_ "GenSigSendType" SG_ 2617119266 DEV_TME_TmeDiag_idxDiagFan1BlockSrv_VW_Data 0;
BA_ "GenSigSwitchedByIgnition" SG_ 2617119266 DEV_TME_TmeDiag_idxDiagFan1BlockSrv_VW_Data 0;
BA_ "GenSigSendType" SG_ 2617119266 DEV_TME_Eng_bStrtFirst_VW_Data 0;
BA_ "GenSigSwitchedByIgnition" SG_ 2617119266 DEV_TME_Eng_bStrtFirst_VW_Data 0;
BA_ "GenSigSendType" SG_ 2617119266 DEV_TME_RefrCir_tVlvRefrExtcCnds_VW_Data 0;
BA_ "GenSigSwitchedByIgnition" SG_ 2617119266 DEV_TME_RefrCir_tVlvRefrExtcCnds_VW_Data 0;
BA_ "GenSigSendType" SG_ 2617119266 DEV_TME_TmeCoc_tiHeatCirDiagRem_VW_Data 0;
BA_ "GenSigSwitchedByIgnition" SG_ 2617119266 DEV_TME_TmeCoc_tiHeatCirDiagRem_VW_Data 0;
BA_ "GenSigSendType" SG_ 2617119266 DEV_TME_TmeCoc_bEnaAirHeatPmp_VW_Data 0;
BA_ "GenSigSwitchedByIgnition" SG_ 2617119266 DEV_TME_TmeCoc_bEnaAirHeatPmp_VW_Data 0;
BA_ "GenSigSendType" SG_ 2617119266 DEV_TME_TmeCoc_volfHeatCir_VW_Data 0;
BA_ "GenSigSwitchedByIgnition" SG_ 2617119266 DEV_TME_TmeCoc_volfHeatCir_VW_Data 0;
BA_ "GenSigSendType" SG_ 2617119267 DEV_TME_TmeEm_tiNotLimPreCdnCab_VW_Data 0;
BA_ "GenSigSwitchedByIgnition" SG_ 2617119267 DEV_TME_TmeEm_tiNotLimPreCdnCab_VW_Data 0;
BA_ "GenSigSendType" SG_ 2617119267 DEV_TME_TmeEm_tiCalcPreCdnCabPas_VW_Data 0;
BA_ "GenSigSwitchedByIgnition" SG_ 2617119267 DEV_TME_TmeEm_tiCalcPreCdnCabPas_VW_Data 0;
BA_ "GenSigSendType" SG_ 2617119267 DEV_TME_TmeEm_tiCalcPreCdnCabParkHeat_VW_Data 0;
BA_ "GenSigSwitchedByIgnition" SG_ 2617119267 DEV_TME_TmeEm_tiCalcPreCdnCabParkHeat_VW_Data 0;
BA_ "GenSigSendType" SG_ 2617119267 DEV_TME_TmeRcc_nCmprCtl_pCmprIn_VW_Data 0;
BA_ "GenSigSwitchedByIgnition" SG_ 2617119267 DEV_TME_TmeRcc_nCmprCtl_pCmprIn_VW_Data 0;
BA_ "GenSigSendType" SG_ 2617119267 DEV_TME_TmeRcc_nCmprCtl_tCmprOut_VW_Data 0;
BA_ "GenSigSwitchedByIgnition" SG_ 2617119267 DEV_TME_TmeRcc_nCmprCtl_tCmprOut_VW_Data 0;
BA_ "GenSigSendType" SG_ 2617119267 DEV_TME_TmeRcc_nCmprCtl_pCmprOut_VW_Data 0;
BA_ "GenSigSwitchedByIgnition" SG_ 2617119267 DEV_TME_TmeRcc_nCmprCtl_pCmprOut_VW_Data 0;
BA_ "GenSigSendType" SG_ 2617119267 DEV_TME_TmeCoc_pwrThmAbsnCmbEngMean_VW_Data 0;
BA_ "GenSigSwitchedByIgnition" SG_ 2617119267 DEV_TME_TmeCoc_pwrThmAbsnCmbEngMean_VW_Data 0;
BA_ "GenSigSendType" SG_ 2617119267 DEV_TME_TmeCtl_stVenAcv_VW_Data 0;
BA_ "GenSigSwitchedByIgnition" SG_ 2617119267 DEV_TME_TmeCtl_stVenAcv_VW_Data 0;
BA_ "GenSigSendType" SG_ 2617119267 DEV_TME_TmeCtl_bReqPhaFcdParkHeatStgy_VW_Data 0;
BA_ "GenSigSwitchedByIgnition" SG_ 2617119267 DEV_TME_TmeCtl_bReqPhaFcdParkHeatStgy_VW_Data 0;
BA_ "GenSigSendType" SG_ 2617119267 DEV_TME_TmeDiag_bOverAcvReq_VW_Data 0;
BA_ "GenSigSwitchedByIgnition" SG_ 2617119267 DEV_TME_TmeDiag_bOverAcvReq_VW_Data 0;
BA_ "GenSigSendType" SG_ 2617119267 DEV_TME_TmeDem_stThmElm1Act_VW_Data 0;
BA_ "GenSigSwitchedByIgnition" SG_ 2617119267 DEV_TME_TmeDem_stThmElm1Act_VW_Data 0;
BA_ "GenSigSendType" SG_ 2617119267 DEV_TME_TmeDiag_bTsCoChilBattIn_VW_Data 0;
BA_ "GenSigSwitchedByIgnition" SG_ 2617119267 DEV_TME_TmeDiag_bTsCoChilBattIn_VW_Data 0;
BA_ "GenSigSendType" SG_ 2617119268 DEV_TME_TmeCoc_pwrThmAbsnCmbEng_VW_Data 0;
BA_ "GenSigSwitchedByIgnition" SG_ 2617119268 DEV_TME_TmeCoc_pwrThmAbsnCmbEng_VW_Data 0;
BA_ "GenSigSendType" SG_ 2617119268 DEV_TME_TmeCtl_tiGlbClkOut_VW_Data 0;
BA_ "GenSigSwitchedByIgnition" SG_ 2617119268 DEV_TME_TmeCtl_tiGlbClkOut_VW_Data 0;
BA_ "GenSigSendType" SG_ 2617119268 DEV_TME_TmeCtl_tiReqPhaPreCdnCabMes_VW_Data 0;
BA_ "GenSigSwitchedByIgnition" SG_ 2617119268 DEV_TME_TmeCtl_tiReqPhaPreCdnCabMes_VW_Data 0;
BA_ "GenSigSendType" SG_ 2617119268 DEV_TME_TmeCtl_tiShDownTmrValMes_VW_Data 0;
BA_ "GenSigSwitchedByIgnition" SG_ 2617119268 DEV_TME_TmeCtl_tiShDownTmrValMes_VW_Data 0;
BA_ "GenSigSendType" SG_ 2617119268 DEV_TME_TmeRcc_rStepRxvChilBattSlave_VW_Data 0;
BA_ "GenSigSwitchedByIgnition" SG_ 2617119268 DEV_TME_TmeRcc_rStepRxvChilBattSlave_VW_Data 0;
BA_ "GenSigSendType" SG_ 2617119268 DEV_TME_TmeRcc_rStepRxvChilBattMain_VW_Data 0;
BA_ "GenSigSwitchedByIgnition" SG_ 2617119268 DEV_TME_TmeRcc_rStepRxvChilBattMain_VW_Data 0;
BA_ "GenSigSendType" SG_ 2617119268 DEV_TME_TmeDem_noAcvLghtEmiDio_VW_Data 0;
BA_ "GenSigSwitchedByIgnition" SG_ 2617119268 DEV_TME_TmeDem_noAcvLghtEmiDio_VW_Data 0;
BA_ "GenSigSendType" SG_ 2617119268 DEV_TME_TmeRadBliCtl_stThmElmInv1Mes_VW_Data 0;
BA_ "GenSigSwitchedByIgnition" SG_ 2617119268 DEV_TME_TmeRadBliCtl_stThmElmInv1Mes_VW_Data 0;
BA_ "GenSigSendType" SG_ 2617119268 DEV_TME_TmeRadBliCtl_stThmDcDcMes_VW_Data 0;
BA_ "GenSigSwitchedByIgnition" SG_ 2617119268 DEV_TME_TmeRadBliCtl_stThmDcDcMes_VW_Data 0;
BA_ "GenSigSendType" SG_ 2617119268 DEV_TME_TmeRadBliCtl_stThmElm1ActMes_VW_Data 0;
BA_ "GenSigSwitchedByIgnition" SG_ 2617119268 DEV_TME_TmeRadBliCtl_stThmElm1ActMes_VW_Data 0;
BA_ "GenSigSendType" SG_ 2617119269 DEV_TME_TmeCtl_stMesTranCmbEng_VW_Data 0;
BA_ "GenSigSwitchedByIgnition" SG_ 2617119269 DEV_TME_TmeCtl_stMesTranCmbEng_VW_Data 0;
BA_ "GenSigSendType" SG_ 2617119269 DEV_TME_TmeEm_pwrStatRawPredCmft_VW_Data 0;
BA_ "GenSigSwitchedByIgnition" SG_ 2617119269 DEV_TME_TmeEm_pwrStatRawPredCmft_VW_Data 0;
BA_ "GenSigSendType" SG_ 2617119269 DEV_TME_TmeEm_stMesCodTrigCabPredSys_VW_Data 0;
BA_ "GenSigSwitchedByIgnition" SG_ 2617119269 DEV_TME_TmeEm_stMesCodTrigCabPredSys_VW_Data 0;
BA_ "GenSigSendType" SG_ 2617119269 DEV_TME_TmeEm_bSuppWinTrigRawCabPred_VW_Data 0;
BA_ "GenSigSwitchedByIgnition" SG_ 2617119269 DEV_TME_TmeEm_bSuppWinTrigRawCabPred_VW_Data 0;
BA_ "GenSigSendType" SG_ 2617119269 DEV_TME_TmeDiag_bVehWkUp_stModOld_VW_Data 0;
BA_ "GenSigSwitchedByIgnition" SG_ 2617119269 DEV_TME_TmeDiag_bVehWkUp_stModOld_VW_Data 0;
BA_ "GenSigSendType" SG_ 2617119269 DEV_TME_TmePrePrc_tCoOut_bVlvElmCirSml_VW_Data 0;
BA_ "GenSigSwitchedByIgnition" SG_ 2617119269 DEV_TME_TmePrePrc_tCoOut_bVlvElmCirSml_VW_Data 0;
BA_ "GenSigSendType" SG_ 2617119269 DEV_TME_TmePrePrc_tCoOut_bVlvElmCirCopl_VW_Data 0;
BA_ "GenSigSwitchedByIgnition" SG_ 2617119269 DEV_TME_TmePrePrc_tCoOut_bVlvElmCirCopl_VW_Data 0;
BA_ "GenSigSendType" SG_ 2617119269 DEV_TME_TmePrePrc_tCoIn_bVlvElmCir_VW_Data 0;
BA_ "GenSigSwitchedByIgnition" SG_ 2617119269 DEV_TME_TmePrePrc_tCoIn_bVlvElmCir_VW_Data 0;
BA_ "GenSigSendType" SG_ 2617119269 DEV_TME_TmePrePrc_pCmprOut_VW_Data 0;
BA_ "GenSigSwitchedByIgnition" SG_ 2617119269 DEV_TME_TmePrePrc_pCmprOut_VW_Data 0;
BA_ "GenSigSendType" SG_ 2617119269 DEV_TME_TmeEm_bSuppWinTrigRawSysCabPred_VW_Data 0;
BA_ "GenSigSwitchedByIgnition" SG_ 2617119269 DEV_TME_TmeEm_bSuppWinTrigRawSysCabPred_VW_Data 0;
BA_ "GenSigSendType" SG_ 2617119269 DEV_TME_TmeEm_bRdyCalcPredCmft_VW_Data 0;
BA_ "GenSigSwitchedByIgnition" SG_ 2617119269 DEV_TME_TmeEm_bRdyCalcPredCmft_VW_Data 0;
BA_ "GenSigSendType" SG_ 2617119269 DEV_TME_TmeEm_bSuppWinFirstTrigSysCabPred_VW_Data 0;
BA_ "GenSigSwitchedByIgnition" SG_ 2617119269 DEV_TME_TmeEm_bSuppWinFirstTrigSysCabPred_VW_Data 0;
BA_ "GenSigSendType" SG_ 2617119269 DEV_TME_TmeEm_bShoPreCdnCabAcv_VW_Data 0;
BA_ "GenSigSwitchedByIgnition" SG_ 2617119269 DEV_TME_TmeEm_bShoPreCdnCabAcv_VW_Data 0;
BA_ "GenSigSendType" SG_ 2617119269 DEV_TME_TmePrePrc_bCmprProtModAcv_VW_Data 0;
BA_ "GenSigSwitchedByIgnition" SG_ 2617119269 DEV_TME_TmePrePrc_bCmprProtModAcv_VW_Data 0;
BA_ "GenSigSendType" SG_ 2617119270 DEV_TME_TmeEcu_stCodPar5_VW_Data 0;
BA_ "GenSigSwitchedByIgnition" SG_ 2617119270 DEV_TME_TmeEcu_stCodPar5_VW_Data 0;
BA_ "GenSigSendType" SG_ 2617119270 DEV_TME_TmeEcu_stCodPar4_VW_Data 0;
BA_ "GenSigSwitchedByIgnition" SG_ 2617119270 DEV_TME_TmeEcu_stCodPar4_VW_Data 0;
BA_ "GenSigSendType" SG_ 2617119271 DEV_TME_TmeEcu_stCodPar1_VW_Data 0;
BA_ "GenSigSwitchedByIgnition" SG_ 2617119271 DEV_TME_TmeEcu_stCodPar1_VW_Data 0;
BA_ "GenSigSendType" SG_ 2617119271 DEV_TME_TmeEcu_stCodPar2_VW_Data 0;
BA_ "GenSigSwitchedByIgnition" SG_ 2617119271 DEV_TME_TmeEcu_stCodPar2_VW_Data 0;
BA_ "GenSigSendType" SG_ 2617119272 DEV_TME_TmeEcu_stCodPar3_VW_Data 0;
BA_ "GenSigSwitchedByIgnition" SG_ 2617119272 DEV_TME_TmeEcu_stCodPar3_VW_Data 0;
BA_ "GenSigSendType" SG_ 2617119272 DEV_TME_TmeRadBliCtl_stThmHvBattMes_VW_Data 0;
BA_ "GenSigSwitchedByIgnition" SG_ 2617119272 DEV_TME_TmeRadBliCtl_stThmHvBattMes_VW_Data 0;
BA_ "GenSigSendType" SG_ 2617119272 DEV_TME_TmeRadBliCtl_stThmHvObChMes_VW_Data 0;
BA_ "GenSigSwitchedByIgnition" SG_ 2617119272 DEV_TME_TmeRadBliCtl_stThmHvObChMes_VW_Data 0;
BA_ "GenSigSendType" SG_ 2617119272 DEV_TME_TmeDiag_bTsCoChilBattOut_VW_Data 0;
BA_ "GenSigSwitchedByIgnition" SG_ 2617119272 DEV_TME_TmeDiag_bTsCoChilBattOut_VW_Data 0;
BA_ "GenSigSendType" SG_ 2617119272 DEV_TME_TmeEm_pwrPredCmft_intenSun_VW_Data 0;
BA_ "GenSigSwitchedByIgnition" SG_ 2617119272 DEV_TME_TmeEm_pwrPredCmft_intenSun_VW_Data 0;
BA_ "GenSigSendType" SG_ 2617119272 DEV_TME_TmeEm_pwrPredCmft_humRel_VW_Data 0;
BA_ "GenSigSwitchedByIgnition" SG_ 2617119272 DEV_TME_TmeEm_pwrPredCmft_humRel_VW_Data 0;
BA_ "GenSigSendType" SG_ 2617119272 DEV_TME_TmeEm_pwrDynRawPredCmft_VW_Data 0;
BA_ "GenSigSwitchedByIgnition" SG_ 2617119272 DEV_TME_TmeEm_pwrDynRawPredCmft_VW_Data 0;
BA_ "GenSigSendType" SG_ 2617119272 DEV_TME_TmeDiag_stRadBliOverHeat_bDiagAcv_VW_Data 0;
BA_ "GenSigSwitchedByIgnition" SG_ 2617119272 DEV_TME_TmeDiag_stRadBliOverHeat_bDiagAcv_VW_Data 0;
BA_ "GenSigSendType" SG_ 2617119272 DEV_TME_TmeDiag_stRadBliRef_bDiagEna_VW_Data 0;
BA_ "GenSigSwitchedByIgnition" SG_ 2617119272 DEV_TME_TmeDiag_stRadBliRef_bDiagEna_VW_Data 0;
BA_ "GenSigSendType" SG_ 2617119272 DEV_TME_TmeDiag_stRadBliIdlRun_bDiagAcv_VW_Data 0;
BA_ "GenSigSwitchedByIgnition" SG_ 2617119272 DEV_TME_TmeDiag_stRadBliIdlRun_bDiagAcv_VW_Data 0;
BA_ "GenSigSendType" SG_ 2617119272 DEV_TME_TmeDiag_stRadBliIceUp_bDiagAcv_VW_Data 0;
BA_ "GenSigSwitchedByIgnition" SG_ 2617119272 DEV_TME_TmeDiag_stRadBliIceUp_bDiagAcv_VW_Data 0;
BA_ "GenSigSendType" SG_ 2617119272 DEV_TME_TmeDiag_stRadBliIni_bDiagEna_VW_Data 0;
BA_ "GenSigSwitchedByIgnition" SG_ 2617119272 DEV_TME_TmeDiag_stRadBliIni_bDiagEna_VW_Data 0;
BA_ "GenSigSendType" SG_ 2617119272 DEV_TME_TmeRadBliDd_bsActrIniOk_VW_Data 0;
BA_ "GenSigSwitchedByIgnition" SG_ 2617119272 DEV_TME_TmeRadBliDd_bsActrIniOk_VW_Data 0;
BA_ "GenSigSendType" SG_ 2617119273 DEV_TME_TmeEm_tiDynRawPredCmft_VW_Data 0;
BA_ "GenSigSwitchedByIgnition" SG_ 2617119273 DEV_TME_TmeEm_tiDynRawPredCmft_VW_Data 0;
BA_ "GenSigSendType" SG_ 2617119273 DEV_TME_TmePrePrc_tCoHeatExchIn_VW_Data 0;
BA_ "GenSigSwitchedByIgnition" SG_ 2617119273 DEV_TME_TmePrePrc_tCoHeatExchIn_VW_Data 0;
BA_ "GenSigSendType" SG_ 2617119273 DEV_TME_HvBatt_wAct_VW_Data 0;
BA_ "GenSigSwitchedByIgnition" SG_ 2617119273 DEV_TME_HvBatt_wAct_VW_Data 0;
BA_ "GenSigSendType" SG_ 2617119273 DEV_TME_TmePrePrc_tWaHeatOut_VW_Data 0;
BA_ "GenSigSwitchedByIgnition" SG_ 2617119273 DEV_TME_TmePrePrc_tWaHeatOut_VW_Data 0;
BA_ "GenSigSendType" SG_ 2617119273 DEV_TME_TmePrePrc_tWaHeatIn_VW_Data 0;
BA_ "GenSigSwitchedByIgnition" SG_ 2617119273 DEV_TME_TmePrePrc_tWaHeatIn_VW_Data 0;
BA_ "GenSigSendType" SG_ 2617119273 DEV_TME_TmeEm_pwrResiPreCdnCab_VW_Data 0;
BA_ "GenSigSwitchedByIgnition" SG_ 2617119273 DEV_TME_TmeEm_pwrResiPreCdnCab_VW_Data 0;
BA_ "GenSigSendType" SG_ 2617119273 DEV_TME_TmeDiag_stRadBliIniReq_VW_Data 0;
BA_ "GenSigSwitchedByIgnition" SG_ 2617119273 DEV_TME_TmeDiag_stRadBliIniReq_VW_Data 0;
BA_ "GenSigSendType" SG_ 2617119273 DEV_TME_TmeRadBliDd_bsActrFail5_VW_Data 0;
BA_ "GenSigSwitchedByIgnition" SG_ 2617119273 DEV_TME_TmeRadBliDd_bsActrFail5_VW_Data 0;
BA_ "GenSigSendType" SG_ 2617119273 DEV_TME_TmeRadBliDd_bsActrFail4_VW_Data 0;
BA_ "GenSigSwitchedByIgnition" SG_ 2617119273 DEV_TME_TmeRadBliDd_bsActrFail4_VW_Data 0;
BA_ "GenSigSendType" SG_ 2617119273 DEV_TME_TmeRadBliDd_bsActrRespFail_VW_Data 0;
BA_ "GenSigSwitchedByIgnition" SG_ 2617119273 DEV_TME_TmeRadBliDd_bsActrRespFail_VW_Data 0;
BA_ "GenSigSendType" SG_ 2617119273 DEV_TME_TmeRadBliDd_bsActrRefOk_VW_Data 0;
BA_ "GenSigSwitchedByIgnition" SG_ 2617119273 DEV_TME_TmeRadBliDd_bsActrRefOk_VW_Data 0;
BA_ "GenSigSendType" SG_ 2617119273 DEV_TME_TmeRadBliDd_bsActrRdy_VW_Data 0;
BA_ "GenSigSwitchedByIgnition" SG_ 2617119273 DEV_TME_TmeRadBliDd_bsActrRdy_VW_Data 0;
BA_ "GenSigSendType" SG_ 2617119273 DEV_TME_TmeRadBliDd_bsActrFail3_VW_Data 0;
BA_ "GenSigSwitchedByIgnition" SG_ 2617119273 DEV_TME_TmeRadBliDd_bsActrFail3_VW_Data 0;
BA_ "GenSigSendType" SG_ 2617119273 DEV_TME_TmeRadBliDd_bsActrFail2_VW_Data 0;
BA_ "GenSigSwitchedByIgnition" SG_ 2617119273 DEV_TME_TmeRadBliDd_bsActrFail2_VW_Data 0;
BA_ "GenSigSendType" SG_ 2617119274 DEV_TME_TmeRadBliDd_bsActrFail1_VW_Data 0;
BA_ "GenSigSwitchedByIgnition" SG_ 2617119274 DEV_TME_TmeRadBliDd_bsActrFail1_VW_Data 0;
BA_ "GenSigSendType" SG_ 2617119274 DEV_TME_TmeRadBliDd_rRadBliSet1_VW_Data 0;
BA_ "GenSigSwitchedByIgnition" SG_ 2617119274 DEV_TME_TmeRadBliDd_rRadBliSet1_VW_Data 0;
BA_ "GenSigSendType" SG_ 2617119274 DEV_TME_TmeRadBliDd_rRadBliAct1_VW_Data 0;
BA_ "GenSigSwitchedByIgnition" SG_ 2617119274 DEV_TME_TmeRadBliDd_rRadBliAct1_VW_Data 0;
BA_ "GenSigSendType" SG_ 2617119274 DEV_TME_TmeDiag_stRadBliSpd2_bDiagAcv_VW_Data 0;
BA_ "GenSigSwitchedByIgnition" SG_ 2617119274 DEV_TME_TmeDiag_stRadBliSpd2_bDiagAcv_VW_Data 0;
BA_ "GenSigSendType" SG_ 2617119274 DEV_TME_TmeDiag_stRadBliRefReq_VW_Data 0;
BA_ "GenSigSwitchedByIgnition" SG_ 2617119274 DEV_TME_TmeDiag_stRadBliRefReq_VW_Data 0;
BA_ "GenSigSendType" SG_ 2617119274 DEV_TME_TmeDiag_stRadBliSpd1_bDiagAcv_VW_Data 0;
BA_ "GenSigSwitchedByIgnition" SG_ 2617119274 DEV_TME_TmeDiag_stRadBliSpd1_bDiagAcv_VW_Data 0;
BA_ "GenSigSendType" SG_ 2617119274 DEV_TME_TmeDiag_stRadBliBlock_bDiagAcv_VW_Data 0;
BA_ "GenSigSwitchedByIgnition" SG_ 2617119274 DEV_TME_TmeDiag_stRadBliBlock_bDiagAcv_VW_Data 0;
BA_ "GenSigSendType" SG_ 2617119274 DEV_TME_TmeDiag_stRadBliBlock_bDiagEna_VW_Data 0;
BA_ "GenSigSwitchedByIgnition" SG_ 2617119274 DEV_TME_TmeDiag_stRadBliBlock_bDiagEna_VW_Data 0;
BA_ "GenSigSendType" SG_ 2617119274 DEV_TME_TmeDiag_stRadBliHealRun_b1FailVld_VW_Data 0;
BA_ "GenSigSwitchedByIgnition" SG_ 2617119274 DEV_TME_TmeDiag_stRadBliHealRun_b1FailVld_VW_Data 0;
BA_ "GenSigSendType" SG_ 2617119274 DEV_TME_TmeDiag_stRadBliHealRun_b1FailSusp_VW_Data 0;
BA_ "GenSigSwitchedByIgnition" SG_ 2617119274 DEV_TME_TmeDiag_stRadBliHealRun_b1FailSusp_VW_Data 0;
BA_ "GenSigSendType" SG_ 2617119274 DEV_TME_TmeDiag_stRadBliAlv_bDiagEna_VW_Data 0;
BA_ "GenSigSwitchedByIgnition" SG_ 2617119274 DEV_TME_TmeDiag_stRadBliAlv_bDiagEna_VW_Data 0;
BA_ "GenSigSendType" SG_ 2617119274 DEV_TME_TmeDiag_stRadBliHealRun_bRef1FailSusp_VW_Data 0;
BA_ "GenSigSwitchedByIgnition" SG_ 2617119274 DEV_TME_TmeDiag_stRadBliHealRun_bRef1FailSusp_VW_Data 0;
BA_ "GenSigSendType" SG_ 2617119274 DEV_TME_Eng_bHotLmp_VW_Data 0;
BA_ "GenSigSwitchedByIgnition" SG_ 2617119274 DEV_TME_Eng_bHotLmp_VW_Data 0;
BA_ "GenSigSendType" SG_ 2617119274 DEV_TME_TmeDiag_stRadBliHealRun_ct_VW_Data 0;
BA_ "GenSigSwitchedByIgnition" SG_ 2617119274 DEV_TME_TmeDiag_stRadBliHealRun_ct_VW_Data 0;
BA_ "GenSigSendType" SG_ 2617119274 DEV_TME_TmeDiag_stRadBliHealRun_b1RefFailVld_VW_Data 0;
BA_ "GenSigSwitchedByIgnition" SG_ 2617119274 DEV_TME_TmeDiag_stRadBliHealRun_b1RefFailVld_VW_Data 0;
BA_ "GenSigSendType" SG_ 2617119274 DEV_TME_TmeRadBliCtl_stThmElm1RtMes_VW_Data 0;
BA_ "GenSigSwitchedByIgnition" SG_ 2617119274 DEV_TME_TmeRadBliCtl_stThmElm1RtMes_VW_Data 0;
BA_ "GenSigSendType" SG_ 2617119274 DEV_TME_TmeEm_pwrDeltaThdSysHld_VW_Data 0;
BA_ "GenSigSwitchedByIgnition" SG_ 2617119274 DEV_TME_TmeEm_pwrDeltaThdSysHld_VW_Data 0;
BA_ "GenSigSendType" SG_ 2617119274 DEV_TME_TmeEm_pwrStatPredCmftFilHld_VW_Data 0;
BA_ "GenSigSwitchedByIgnition" SG_ 2617119274 DEV_TME_TmeEm_pwrStatPredCmftFilHld_VW_Data 0;
BA_ "GenSigSendType" SG_ 2617119274 DEV_TME_TmeEm_pwrStatPredCmftFilSysHld_VW_Data 0;
BA_ "GenSigSwitchedByIgnition" SG_ 2617119274 DEV_TME_TmeEm_pwrStatPredCmftFilSysHld_VW_Data 0;
BA_ "GenSigSendType" SG_ 2617119274 DEV_TME_TmeDiag_bHvBattModAcv_VW_Data 0;
BA_ "GenSigSwitchedByIgnition" SG_ 2617119274 DEV_TME_TmeDiag_bHvBattModAcv_VW_Data 0;
BA_ "GenSigSendType" SG_ 2617119274 DEV_TME_TmeDiag_idxDiagTsHeatExchIn_VW_Data 0;
BA_ "GenSigSwitchedByIgnition" SG_ 2617119274 DEV_TME_TmeDiag_idxDiagTsHeatExchIn_VW_Data 0;
BA_ "GenSigSendType" SG_ 2617119274 DEV_TME_TmeEm_bSigVldPreCdnCabMes_VW_Data 0;
BA_ "GenSigSwitchedByIgnition" SG_ 2617119274 DEV_TME_TmeEm_bSigVldPreCdnCabMes_VW_Data 0;
BA_ "GenSigSendType" SG_ 2617119275 DEV_TME_TmeEm_wDynDeltaPredCmftHld_VW_Data 0;
BA_ "GenSigSwitchedByIgnition" SG_ 2617119275 DEV_TME_TmeEm_wDynDeltaPredCmftHld_VW_Data 0;
BA_ "GenSigSendType" SG_ 2617119275 DEV_TME_TmeEm_stCodConf_VW_Data 0;
BA_ "GenSigSwitchedByIgnition" SG_ 2617119275 DEV_TME_TmeEm_stCodConf_VW_Data 0;
BA_ "GenSigSendType" SG_ 2617119275 DEV_TME_TmePostPrc_stCodReasVehCom_VW_Data 0;
BA_ "GenSigSwitchedByIgnition" SG_ 2617119275 DEV_TME_TmePostPrc_stCodReasVehCom_VW_Data 0;
BA_ "GenSigSendType" SG_ 2617119275 DEV_TME_TmePrePrc_stCodSigVldNrm1_VW_Data 0;
BA_ "GenSigSwitchedByIgnition" SG_ 2617119275 DEV_TME_TmePrePrc_stCodSigVldNrm1_VW_Data 0;
BA_ "GenSigSendType" SG_ 2617119275 DEV_TME_TmePrePrc_tAmbFil_VW_Data 0;
BA_ "GenSigSwitchedByIgnition" SG_ 2617119275 DEV_TME_TmePrePrc_tAmbFil_VW_Data 0;
BA_ "GenSigSendType" SG_ 2617119275 DEV_TME_TmeDiag_bTsVlvInrWaHeatExch_VW_Data 0;
BA_ "GenSigSwitchedByIgnition" SG_ 2617119275 DEV_TME_TmeDiag_bTsVlvInrWaHeatExch_VW_Data 0;
BA_ "GenSigSendType" SG_ 2617119275 DEV_TME_TmeDiag_stHeatPrfLeak_bDiagAcv_VW_Data 0;
BA_ "GenSigSwitchedByIgnition" SG_ 2617119275 DEV_TME_TmeDiag_stHeatPrfLeak_bDiagAcv_VW_Data 0;
BA_ "GenSigSendType" SG_ 2617119275 DEV_TME_TmeDiag_stHeatPrfLeak_bDiagEna_VW_Data 0;
BA_ "GenSigSwitchedByIgnition" SG_ 2617119275 DEV_TME_TmeDiag_stHeatPrfLeak_bDiagEna_VW_Data 0;
BA_ "GenSigSendType" SG_ 2617119276 DEV_TME_TmePostPrc_stCmprOffAc_VW_Data 0;
BA_ "GenSigSwitchedByIgnition" SG_ 2617119276 DEV_TME_TmePostPrc_stCmprOffAc_VW_Data 0;
BA_ "GenSigSendType" SG_ 2617119276 DEV_TME_TmePostPrc_stCmprOffAcvBattCo_VW_Data 0;
BA_ "GenSigSwitchedByIgnition" SG_ 2617119276 DEV_TME_TmePostPrc_stCmprOffAcvBattCo_VW_Data 0;
BA_ "GenSigSendType" SG_ 2617119276 DEV_TME_TmePostPrc_stCmprOffHeatPmp_VW_Data 0;
BA_ "GenSigSwitchedByIgnition" SG_ 2617119276 DEV_TME_TmePostPrc_stCmprOffHeatPmp_VW_Data 0;
BA_ "GenSigSendType" SG_ 2617119276 DEV_TME_TmeDiag_bCrchHeatCir_tiIdlStrt_VW_Data 0;
BA_ "GenSigSwitchedByIgnition" SG_ 2617119276 DEV_TME_TmeDiag_bCrchHeatCir_tiIdlStrt_VW_Data 0;
BA_ "GenSigSendType" SG_ 2617119276 DEV_TME_TmeDiag_idxDiagRefrCirOverHeat_VW_Data 0;
BA_ "GenSigSwitchedByIgnition" SG_ 2617119276 DEV_TME_TmeDiag_idxDiagRefrCirOverHeat_VW_Data 0;
BA_ "GenSigSendType" SG_ 2617119276 DEV_TME_TmeEm_pwrAvlRedPreCdnCab_VW_Data 0;
BA_ "GenSigSwitchedByIgnition" SG_ 2617119276 DEV_TME_TmeEm_pwrAvlRedPreCdnCab_VW_Data 0;
BA_ "GenSigSendType" SG_ 2617119276 DEV_TME_TmeDiag_idxDiagElmCirPrf_VW_Data 0;
BA_ "GenSigSwitchedByIgnition" SG_ 2617119276 DEV_TME_TmeDiag_idxDiagElmCirPrf_VW_Data 0;
BA_ "GenSigSendType" SG_ 2617119276 DEV_TME_TmeCoc_volfActElmCir_VW_Data 0;
BA_ "GenSigSwitchedByIgnition" SG_ 2617119276 DEV_TME_TmeCoc_volfActElmCir_VW_Data 0;
BA_ "GenSigSendType" SG_ 2617119276 DEV_TME_TmeCoc_volfActCmbEng_VW_Data 0;
BA_ "GenSigSwitchedByIgnition" SG_ 2617119276 DEV_TME_TmeCoc_volfActCmbEng_VW_Data 0;
BA_ "GenSigSendType" SG_ 2617119277 DEV_TME_TmeDiag_volfElmCirElmCir_VW_Data 0;
BA_ "GenSigSwitchedByIgnition" SG_ 2617119277 DEV_TME_TmeDiag_volfElmCirElmCir_VW_Data 0;
BA_ "GenSigSendType" SG_ 2617119277 DEV_TME_TmeDiag_volfHeatCirElmCir_VW_Data 0;
BA_ "GenSigSwitchedByIgnition" SG_ 2617119277 DEV_TME_TmeDiag_volfHeatCirElmCir_VW_Data 0;
BA_ "GenSigSendType" SG_ 2617119277 DEV_TME_TmeDiag_volfCmbEngElmCir_VW_Data 0;
BA_ "GenSigSwitchedByIgnition" SG_ 2617119277 DEV_TME_TmeDiag_volfCmbEngElmCir_VW_Data 0;
BA_ "GenSigSendType" SG_ 2617119277 DEV_TME_TmeDiag_volfChilBattElmCir_VW_Data 0;
BA_ "GenSigSwitchedByIgnition" SG_ 2617119277 DEV_TME_TmeDiag_volfChilBattElmCir_VW_Data 0;
BA_ "GenSigSendType" SG_ 2617119277 DEV_TME_TmeCoc_volfActHeatCir_VW_Data 0;
BA_ "GenSigSwitchedByIgnition" SG_ 2617119277 DEV_TME_TmeCoc_volfActHeatCir_VW_Data 0;
BA_ "GenSigSendType" SG_ 2617119277 DEV_TME_Pmp_stHeatCirDiag2_VW_Data 0;
BA_ "GenSigSwitchedByIgnition" SG_ 2617119277 DEV_TME_Pmp_stHeatCirDiag2_VW_Data 0;
BA_ "GenSigSendType" SG_ 2617119277 DEV_TME_TmeDiag_volfHeatCirHeatCir_VW_Data 0;
BA_ "GenSigSwitchedByIgnition" SG_ 2617119277 DEV_TME_TmeDiag_volfHeatCirHeatCir_VW_Data 0;
BA_ "GenSigSendType" SG_ 2617119277 DEV_TME_TmeDiag_volfCmbEngHeatCir_VW_Data 0;
BA_ "GenSigSwitchedByIgnition" SG_ 2617119277 DEV_TME_TmeDiag_volfCmbEngHeatCir_VW_Data 0;
BA_ "GenSigSendType" SG_ 2617119277 DEV_TME_TmeDiag_volfElmCirHeatCir_VW_Data 0;
BA_ "GenSigSwitchedByIgnition" SG_ 2617119277 DEV_TME_TmeDiag_volfElmCirHeatCir_VW_Data 0;
BA_ "GenSigSendType" SG_ 2617119277 DEV_TME_TmeDiag_volfChilBattHeatCir_VW_Data 0;
BA_ "GenSigSwitchedByIgnition" SG_ 2617119277 DEV_TME_TmeDiag_volfChilBattHeatCir_VW_Data 0;
BA_ "GenSigSendType" SG_ 2617119277 DEV_TME_TmeDiag_bCrchHeatCir_ctNvmHeatSrcAcvStrt_VW_Data 0;
BA_ "GenSigSwitchedByIgnition" SG_ 2617119277 DEV_TME_TmeDiag_bCrchHeatCir_ctNvmHeatSrcAcvStrt_VW_Data 0;
BA_ "GenSigSendType" SG_ 2617119277 DEV_TME_TmeDiag_tCrchRefrCir_ctNvmHeatSrcAcvStrt_VW_Data 0;
BA_ "GenSigSwitchedByIgnition" SG_ 2617119277 DEV_TME_TmeDiag_tCrchRefrCir_ctNvmHeatSrcAcvStrt_VW_Data 0;
BA_ "GenSigSendType" SG_ 2617119277 DEV_TME_TmeDiag_volfElmCir_VW_Data 0;
BA_ "GenSigSwitchedByIgnition" SG_ 2617119277 DEV_TME_TmeDiag_volfElmCir_VW_Data 0;
BA_ "GenSigSendType" SG_ 2617119277 DEV_TME_HvESCh_stDemHeatHvBatt_VW_Data 0;
BA_ "GenSigSwitchedByIgnition" SG_ 2617119277 DEV_TME_HvESCh_stDemHeatHvBatt_VW_Data 0;
BA_ "GenSigSendType" SG_ 2617119278 DEV_TME_TmeDiag_tCrchRefrCir_tiIdlStrt_VW_Data 0;
BA_ "GenSigSwitchedByIgnition" SG_ 2617119278 DEV_TME_TmeDiag_tCrchRefrCir_tiIdlStrt_VW_Data 0;
BA_ "GenSigSendType" SG_ 2617119278 DEV_TME_TmeDiag_volfCmbEng_VW_Data 0;
BA_ "GenSigSwitchedByIgnition" SG_ 2617119278 DEV_TME_TmeDiag_volfCmbEng_VW_Data 0;
BA_ "GenSigSendType" SG_ 2617119278 DEV_TME_TmeDiag_volfHeatCir_VW_Data 0;
BA_ "GenSigSwitchedByIgnition" SG_ 2617119278 DEV_TME_TmeDiag_volfHeatCir_VW_Data 0;
BA_ "GenSigSendType" SG_ 2617119278 DEV_TME_TmeDiag_tCrchRefrCirVlv_tiIdlStrt_VW_Data 0;
BA_ "GenSigSwitchedByIgnition" SG_ 2617119278 DEV_TME_TmeDiag_tCrchRefrCirVlv_tiIdlStrt_VW_Data 0;
BA_ "GenSigSendType" SG_ 2617119278 DEV_TME_TmeDiag_tCrchRefrCirVlv_ctNvmHeatSrcAcvStrt_VW_Data 0;
BA_ "GenSigSwitchedByIgnition" SG_ 2617119278 DEV_TME_TmeDiag_tCrchRefrCirVlv_ctNvmHeatSrcAcvStrt_VW_Data 0;
BA_ "GenSigSendType" SG_ 2617119278 DEV_TME_TmeDiag_pCrchRefrCir_ctNvmHeatSrcAcvStrt_VW_Data 0;
BA_ "GenSigSwitchedByIgnition" SG_ 2617119278 DEV_TME_TmeDiag_pCrchRefrCir_ctNvmHeatSrcAcvStrt_VW_Data 0;
BA_ "GenSigSendType" SG_ 2617119278 DEV_TME_TmeDiag_pCrchRefrCir_tiIdlStrt_VW_Data 0;
BA_ "GenSigSwitchedByIgnition" SG_ 2617119278 DEV_TME_TmeDiag_pCrchRefrCir_tiIdlStrt_VW_Data 0;
BA_ "GenSigSendType" SG_ 2617119278 DEV_TME_TmeDiag_idxDiagFan1_VW_Data 0;
BA_ "GenSigSwitchedByIgnition" SG_ 2617119278 DEV_TME_TmeDiag_idxDiagFan1_VW_Data 0;
BA_ "GenSigSendType" SG_ 2617119278 DEV_TME_TmeDiag_idxDiagFan2_VW_Data 0;
BA_ "GenSigSwitchedByIgnition" SG_ 2617119278 DEV_TME_TmeDiag_idxDiagFan2_VW_Data 0;
BA_ "GenSigSendType" SG_ 2617119279 DEV_TME_TmeDiag_bCrchHeatCir_tNvmRead_VW_Data 0;
BA_ "GenSigSwitchedByIgnition" SG_ 2617119279 DEV_TME_TmeDiag_bCrchHeatCir_tNvmRead_VW_Data 0;
BA_ "GenSigSendType" SG_ 2617119279 DEV_TME_TmeDiag_noSwVers0_VW_Data 0;
BA_ "GenSigSwitchedByIgnition" SG_ 2617119279 DEV_TME_TmeDiag_noSwVers0_VW_Data 0;
BA_ "GenSigSendType" SG_ 2617119279 DEV_TME_TmeDiag_noSwVers1_VW_Data 0;
BA_ "GenSigSwitchedByIgnition" SG_ 2617119279 DEV_TME_TmeDiag_noSwVers1_VW_Data 0;
BA_ "GenSigSendType" SG_ 2617119279 DEV_TME_TmeDiag_noSwVers2_VW_Data 0;
BA_ "GenSigSwitchedByIgnition" SG_ 2617119279 DEV_TME_TmeDiag_noSwVers2_VW_Data 0;
BA_ "GenSigSendType" SG_ 2617119279 DEV_TME_TmeDiag_noSwVers3_VW_Data 0;
BA_ "GenSigSwitchedByIgnition" SG_ 2617119279 DEV_TME_TmeDiag_noSwVers3_VW_Data 0;
BA_ "GenSigSendType" SG_ 2617119279 DEV_TME_TmeDiag_pCrchRefrCir_pNvmRead_VW_Data 0;
BA_ "GenSigSwitchedByIgnition" SG_ 2617119279 DEV_TME_TmeDiag_pCrchRefrCir_pNvmRead_VW_Data 0;
BA_ "GenSigSendType" SG_ 2617119279 DEV_TME_TmeDiag_tCrchRefrCir_tNvmRead_VW_Data 0;
BA_ "GenSigSwitchedByIgnition" SG_ 2617119279 DEV_TME_TmeDiag_tCrchRefrCir_tNvmRead_VW_Data 0;
BA_ "GenSigSendType" SG_ 2617119279 DEV_TME_TmeEm_rPrfWaHeatCmft_VW_Data 0;
BA_ "GenSigSwitchedByIgnition" SG_ 2617119279 DEV_TME_TmeEm_rPrfWaHeatCmft_VW_Data 0;
BA_ "GenSigSendType" SG_ 2617119280 DEV_TME_TmeDiag_tCrchRefrCirVlv_tNvmRead_VW_Data 0;
BA_ "GenSigSwitchedByIgnition" SG_ 2617119280 DEV_TME_TmeDiag_tCrchRefrCirVlv_tNvmRead_VW_Data 0;
BA_ "GenSigSendType" SG_ 2617119280 DEV_TME_TmeEm_wPreCdnCabHvMes_VW_Data 0;
BA_ "GenSigSwitchedByIgnition" SG_ 2617119280 DEV_TME_TmeEm_wPreCdnCabHvMes_VW_Data 0;
BA_ "GenSigSendType" SG_ 2617119280 DEV_TME_TmeEm_wThdPreCdnCabHvLvMes_VW_Data 0;
BA_ "GenSigSwitchedByIgnition" SG_ 2617119280 DEV_TME_TmeEm_wThdPreCdnCabHvLvMes_VW_Data 0;
BA_ "GenSigSendType" SG_ 2617119280 DEV_TME_TmeEm_wThdPreCdnCabLvMes_VW_Data 0;
BA_ "GenSigSwitchedByIgnition" SG_ 2617119280 DEV_TME_TmeEm_wThdPreCdnCabLvMes_VW_Data 0;
BA_ "GenSigSendType" SG_ 2617119280 DEV_TME_TmeCoc_rStepVlvInrWaHeatExch_VW_Data 0;
BA_ "GenSigSwitchedByIgnition" SG_ 2617119280 DEV_TME_TmeCoc_rStepVlvInrWaHeatExch_VW_Data 0;
BA_ "GenSigSendType" SG_ 2617119280 DEV_TME_TmePrePrc_tCoChilBattIn_VW_Data 0;
BA_ "GenSigSwitchedByIgnition" SG_ 2617119280 DEV_TME_TmePrePrc_tCoChilBattIn_VW_Data 0;
BA_ "GenSigSendType" SG_ 2617119280 DEV_TME_TmePrePrc_tCoChilBattOut_VW_Data 0;
BA_ "GenSigSwitchedByIgnition" SG_ 2617119280 DEV_TME_TmePrePrc_tCoChilBattOut_VW_Data 0;
BA_ "GenSigSendType" SG_ 2617119280 DEV_TME_TmeEm_rPrfWaHeatThm_VW_Data 0;
BA_ "GenSigSwitchedByIgnition" SG_ 2617119280 DEV_TME_TmeEm_rPrfWaHeatThm_VW_Data 0;
BA_ "GenSigSendType" SG_ 2617119280 DEV_TME_HvBatt_stDemCoHeatHvBattRaw_VW_Data 0;
BA_ "GenSigSwitchedByIgnition" SG_ 2617119280 DEV_TME_HvBatt_stDemCoHeatHvBattRaw_VW_Data 0;
BA_ "GenSigSendType" SG_ 2617119280 DEV_TME_HvESCh_stDemHeatHvBattRaw_VW_Data 0;
BA_ "GenSigSwitchedByIgnition" SG_ 2617119280 DEV_TME_HvESCh_stDemHeatHvBattRaw_VW_Data 0;
BA_ "GenSigSendType" SG_ 2617119281 DEV_TME_TmeDem_tCoHeatBattSet_VW_Data 0;
BA_ "GenSigSwitchedByIgnition" SG_ 2617119281 DEV_TME_TmeDem_tCoHeatBattSet_VW_Data 0;
BA_ "GenSigSendType" SG_ 2617119281 DEV_TME_TmeFan_bRadBliDemFanVldMes_VW_Data 0;
BA_ "GenSigSwitchedByIgnition" SG_ 2617119281 DEV_TME_TmeFan_bRadBliDemFanVldMes_VW_Data 0;
BA_ "GenSigSendType" SG_ 2617119281 DEV_TME_TmeRadBliCtl_rRadBliSet1_VW_Data 0;
BA_ "GenSigSwitchedByIgnition" SG_ 2617119281 DEV_TME_TmeRadBliCtl_rRadBliSet1_VW_Data 0;
BA_ "GenSigSendType" SG_ 2617119281 DEV_TME_TmeRadBliCtl_rRadBliSet2_VW_Data 0;
BA_ "GenSigSwitchedByIgnition" SG_ 2617119281 DEV_TME_TmeRadBliCtl_rRadBliSet2_VW_Data 0;
BA_ "GenSigSendType" SG_ 2617119281 DEV_TME_TmeCoc_bEnaLinVlvMes_VW_Data 0;
BA_ "GenSigSwitchedByIgnition" SG_ 2617119281 DEV_TME_TmeCoc_bEnaLinVlvMes_VW_Data 0;
BA_ "GenSigSendType" SG_ 2617119281 DEV_TME_TmeCoc_facICpntBattHeatBypRad_VW_Data 0;
BA_ "GenSigSwitchedByIgnition" SG_ 2617119281 DEV_TME_TmeCoc_facICpntBattHeatBypRad_VW_Data 0;
BA_ "GenSigSendType" SG_ 2617119281 DEV_TME_TmeCoc_facICpntBattHeatCir_VW_Data 0;
BA_ "GenSigSwitchedByIgnition" SG_ 2617119281 DEV_TME_TmeCoc_facICpntBattHeatCir_VW_Data 0;
BA_ "GenSigSendType" SG_ 2617119281 DEV_TME_TmeCoc_facPCpntBattHeatBypRad_VW_Data 0;
BA_ "GenSigSwitchedByIgnition" SG_ 2617119281 DEV_TME_TmeCoc_facPCpntBattHeatBypRad_VW_Data 0;
BA_ "GenSigSendType" SG_ 2617119281 DEV_TME_TmeDem_stThmInduCh_VW_Data 0;
BA_ "GenSigSwitchedByIgnition" SG_ 2617119281 DEV_TME_TmeDem_stThmInduCh_VW_Data 0;
BA_ "GenSigSendType" SG_ 2617119282 DEV_TME_CoCirDrv_rActStepVlvBypObCh_VW_Data 0;
BA_ "GenSigSwitchedByIgnition" SG_ 2617119282 DEV_TME_CoCirDrv_rActStepVlvBypObCh_VW_Data 0;
BA_ "GenSigSendType" SG_ 2617119282 DEV_TME_CoCirDrv_rActStepVlvHeatCirSml_VW_Data 0;
BA_ "GenSigSwitchedByIgnition" SG_ 2617119282 DEV_TME_CoCirDrv_rActStepVlvHeatCirSml_VW_Data 0;
BA_ "GenSigSendType" SG_ 2617119282 DEV_TME_TmeCoc_rStepVlvBypBatt_VW_Data 0;
BA_ "GenSigSwitchedByIgnition" SG_ 2617119282 DEV_TME_TmeCoc_rStepVlvBypBatt_VW_Data 0;
BA_ "GenSigSendType" SG_ 2617119282 DEV_TME_TmeCoc_rStepVlvBypObCh_VW_Data 0;
BA_ "GenSigSwitchedByIgnition" SG_ 2617119282 DEV_TME_TmeCoc_rStepVlvBypObCh_VW_Data 0;
BA_ "GenSigSendType" SG_ 2617119282 DEV_TME_TmeCoc_rStepVlvBypRad_VW_Data 0;
BA_ "GenSigSwitchedByIgnition" SG_ 2617119282 DEV_TME_TmeCoc_rStepVlvBypRad_VW_Data 0;
BA_ "GenSigSendType" SG_ 2617119282 DEV_TME_TmeCoc_rStepVlvHeatCirSml_VW_Data 0;
BA_ "GenSigSwitchedByIgnition" SG_ 2617119282 DEV_TME_TmeCoc_rStepVlvHeatCirSml_VW_Data 0;
BA_ "GenSigSendType" SG_ 2617119282 DEV_TME_TmeCoc_stVlvBypBatt_VW_Data 0;
BA_ "GenSigSwitchedByIgnition" SG_ 2617119282 DEV_TME_TmeCoc_stVlvBypBatt_VW_Data 0;
BA_ "GenSigSendType" SG_ 2617119282 DEV_TME_TmeCoc_stVlvBypObCh_VW_Data 0;
BA_ "GenSigSwitchedByIgnition" SG_ 2617119282 DEV_TME_TmeCoc_stVlvBypObCh_VW_Data 0;
BA_ "GenSigSendType" SG_ 2617119282 DEV_TME_TmeCoc_stVlvBypRad_VW_Data 0;
BA_ "GenSigSwitchedByIgnition" SG_ 2617119282 DEV_TME_TmeCoc_stVlvBypRad_VW_Data 0;
BA_ "GenSigSendType" SG_ 2617119283 DEV_TME_TmeCoc_stVlvHeatCir_VW_Data 0;
BA_ "GenSigSwitchedByIgnition" SG_ 2617119283 DEV_TME_TmeCoc_stVlvHeatCir_VW_Data 0;
BA_ "GenSigSendType" SG_ 2617119283 DEV_TME_TmeCoc_rStepCtlOfsBattHeatBypRad_VW_Data 0;
BA_ "GenSigSwitchedByIgnition" SG_ 2617119283 DEV_TME_TmeCoc_rStepCtlOfsBattHeatBypRad_VW_Data 0;
BA_ "GenSigSendType" SG_ 2617119283 DEV_TME_TmePrePrc_tActInvFil_VW_Data 0;
BA_ "GenSigSwitchedByIgnition" SG_ 2617119283 DEV_TME_TmePrePrc_tActInvFil_VW_Data 0;
BA_ "GenSigSendType" SG_ 2617119283 DEV_TME_TmeHeatSrcCtl_rWaHeat2Prf_VW_Data 0;
BA_ "GenSigSwitchedByIgnition" SG_ 2617119283 DEV_TME_TmeHeatSrcCtl_rWaHeat2Prf_VW_Data 0;
BA_ "GenSigSendType" SG_ 2617119284 DEV_TME_TmeCtl_stCodFailPreCdnCabRaw_VW_Data 0;
BA_ "GenSigSwitchedByIgnition" SG_ 2617119284 DEV_TME_TmeCtl_stCodFailPreCdnCabRaw_VW_Data 0;
BA_ "GenSigSendType" SG_ 2617119284 DEV_TME_TmePrePrc_stCodCpntAvlCoCir_VW_Data 0;
BA_ "GenSigSwitchedByIgnition" SG_ 2617119284 DEV_TME_TmePrePrc_stCodCpntAvlCoCir_VW_Data 0;
BA_ "GenSigSendType" SG_ 2617119284 DEV_TME_TmePrePrc_stCodCpntAvlCoCir2_VW_Data 0;
BA_ "GenSigSwitchedByIgnition" SG_ 2617119284 DEV_TME_TmePrePrc_stCodCpntAvlCoCir2_VW_Data 0;
BA_ "GenSigSendType" SG_ 2617119284 DEV_TME_TmePrePrc_stCodConfAlwPreCdnCab_VW_Data 0;
BA_ "GenSigSwitchedByIgnition" SG_ 2617119284 DEV_TME_TmePrePrc_stCodConfAlwPreCdnCab_VW_Data 0;
BA_ "GenSigSendType" SG_ 2617119284 DEV_TME_TmeDiag_stHeatPrfLeak_bObdObsBlock_VW_Data 0;
BA_ "GenSigSwitchedByIgnition" SG_ 2617119284 DEV_TME_TmeDiag_stHeatPrfLeak_bObdObsBlock_VW_Data 0;
BA_ "GenSigSendType" SG_ 2617119284 DEV_TME_TmeDiag_bVlvInrWaHeatExch_VW_Data 0;
BA_ "GenSigSwitchedByIgnition" SG_ 2617119284 DEV_TME_TmeDiag_bVlvInrWaHeatExch_VW_Data 0;
BA_ "GenSigSendType" SG_ 2617119285 DEV_TME_TmeCoc_facICpntElmInvIn_VW_Data 0;
BA_ "GenSigSwitchedByIgnition" SG_ 2617119285 DEV_TME_TmeCoc_facICpntElmInvIn_VW_Data 0;
BA_ "GenSigSendType" SG_ 2617119285 DEV_TME_TmeCoc_facICpntHeatExchIn_VW_Data 0;
BA_ "GenSigSwitchedByIgnition" SG_ 2617119285 DEV_TME_TmeCoc_facICpntHeatExchIn_VW_Data 0;
BA_ "GenSigSendType" SG_ 2617119285 DEV_TME_TmeCoc_facICpntRadOut_VW_Data 0;
BA_ "GenSigSwitchedByIgnition" SG_ 2617119285 DEV_TME_TmeCoc_facICpntRadOut_VW_Data 0;
BA_ "GenSigSendType" SG_ 2617119285 TmeCoc_facPCpntBattHeatCir_VW_Data 0;
BA_ "GenSigSwitchedByIgnition" SG_ 2617119285 TmeCoc_facPCpntBattHeatCir_VW_Data 0;
BA_ "GenSigSendType" SG_ 2617119285 DEV_TME_TmeCoc_facPCpntElmInvIn_VW_Data 0;
BA_ "GenSigSwitchedByIgnition" SG_ 2617119285 DEV_TME_TmeCoc_facPCpntElmInvIn_VW_Data 0;
BA_ "GenSigSendType" SG_ 2617119285 DEV_TME_TmeHeatSrcCtl_bWaHeat2HysLoAcvMes_VW_Data 0;
BA_ "GenSigSwitchedByIgnition" SG_ 2617119285 DEV_TME_TmeHeatSrcCtl_bWaHeat2HysLoAcvMes_VW_Data 0;
BA_ "GenSigSendType" SG_ 2617119285 DEV_TME_TmeHeatSrcCtl_bWaHeat2PlugMes_VW_Data 0;
BA_ "GenSigSwitchedByIgnition" SG_ 2617119285 DEV_TME_TmeHeatSrcCtl_bWaHeat2PlugMes_VW_Data 0;
BA_ "GenSigSendType" SG_ 2617119286 DEV_TME_TmeCoc_facPCpntHeatExchIn_VW_Data 0;
BA_ "GenSigSwitchedByIgnition" SG_ 2617119286 DEV_TME_TmeCoc_facPCpntHeatExchIn_VW_Data 0;
BA_ "GenSigSendType" SG_ 2617119286 DEV_TME_TmeCoc_facPCpntRadOut_VW_Data 0;
BA_ "GenSigSwitchedByIgnition" SG_ 2617119286 DEV_TME_TmeCoc_facPCpntRadOut_VW_Data 0;
BA_ "GenSigSendType" SG_ 2617119286 DEV_TME_TmeCoc_rStepCtlOfsBattHeatCir_VW_Data 0;
BA_ "GenSigSwitchedByIgnition" SG_ 2617119286 DEV_TME_TmeCoc_rStepCtlOfsBattHeatCir_VW_Data 0;
BA_ "GenSigSendType" SG_ 2617119286 DEV_TME_TmeCoc_rStepCtlOfsElmInvIn_VW_Data 0;
BA_ "GenSigSwitchedByIgnition" SG_ 2617119286 DEV_TME_TmeCoc_rStepCtlOfsElmInvIn_VW_Data 0;
BA_ "GenSigSendType" SG_ 2617119286 DEV_TME_TmeCoc_rStepCtlOfsHeatExchIn_VW_Data 0;
BA_ "GenSigSwitchedByIgnition" SG_ 2617119286 DEV_TME_TmeCoc_rStepCtlOfsHeatExchIn_VW_Data 0;
BA_ "GenSigSendType" SG_ 2617119286 DEV_TME_TmeCoc_rStepCtlOfsRadOut_VW_Data 0;
BA_ "GenSigSwitchedByIgnition" SG_ 2617119286 DEV_TME_TmeCoc_rStepCtlOfsRadOut_VW_Data 0;
BA_ "GenSigSendType" SG_ 2617119286 DEV_TME_TmeDem_tCoRadOutSet_VW_Data 0;
BA_ "GenSigSwitchedByIgnition" SG_ 2617119286 DEV_TME_TmeDem_tCoRadOutSet_VW_Data 0;
BA_ "GenSigSendType" SG_ 2617119287 DEV_TME_TmePrePrc_stCodSigVld1_VW_Data 0;
BA_ "GenSigSwitchedByIgnition" SG_ 2617119287 DEV_TME_TmePrePrc_stCodSigVld1_VW_Data 0;
BA_ "GenSigSendType" SG_ 2617119287 DEV_TME_TmePrePrc_stCodSigVld2_VW_Data 0;
BA_ "GenSigSwitchedByIgnition" SG_ 2617119287 DEV_TME_TmePrePrc_stCodSigVld2_VW_Data 0;
BA_ "GenSigSendType" SG_ 2617119288 DEV_TME_TmePrePrc_stCodConfAlw_VW_Data 0;
BA_ "GenSigSwitchedByIgnition" SG_ 2617119288 DEV_TME_TmePrePrc_stCodConfAlw_VW_Data 0;
BA_ "GenSigSendType" SG_ 2617119288 DEV_TME_TmePrePrc_stCodCpntAvlRefrCir_VW_Data 0;
BA_ "GenSigSwitchedByIgnition" SG_ 2617119288 DEV_TME_TmePrePrc_stCodCpntAvlRefrCir_VW_Data 0;
BA_ "GenSigSendType" SG_ 2617119289 DEV_TME_TmePrePrc_stCodSigVld4_VW_Data 0;
BA_ "GenSigSwitchedByIgnition" SG_ 2617119289 DEV_TME_TmePrePrc_stCodSigVld4_VW_Data 0;
BA_ "GenSigSendType" SG_ 2617119289 DEV_TME_TmePrePrc_stCodDiagAlw_VW_Data 0;
BA_ "GenSigSwitchedByIgnition" SG_ 2617119289 DEV_TME_TmePrePrc_stCodDiagAlw_VW_Data 0;
BA_ "GenSigSendType" SG_ 2617119290 DEV_TME_TmePrePrc_stCodSigVld3_VW_Data 0;
BA_ "GenSigSwitchedByIgnition" SG_ 2617119290 DEV_TME_TmePrePrc_stCodSigVld3_VW_Data 0;
BA_ "GenSigSendType" SG_ 2617119290 DEV_TME_TmeCtl_stOpmPartLdIdc_VW_Data 0;
BA_ "GenSigSwitchedByIgnition" SG_ 2617119290 DEV_TME_TmeCtl_stOpmPartLdIdc_VW_Data 0;
BA_ "GenSigSendType" SG_ 2617119291 DEV_TME_TmeHeatSrcCtl_iWaHeatFil_VW_Data 0;
BA_ "GenSigSwitchedByIgnition" SG_ 2617119291 DEV_TME_TmeHeatSrcCtl_iWaHeatFil_VW_Data 0;
BA_ "GenSigSendType" SG_ 2617119291 DEV_TME_TmeRadBliCtl_stAirCdnOpRadBliMes_VW_Data 0;
BA_ "GenSigSwitchedByIgnition" SG_ 2617119291 DEV_TME_TmeRadBliCtl_stAirCdnOpRadBliMes_VW_Data 0;
BA_ "GenSigSendType" SG_ 2617119291 DEV_TME_TmeRadBliCtl_stClsReqRadBliMes_VW_Data 0;
BA_ "GenSigSwitchedByIgnition" SG_ 2617119291 DEV_TME_TmeRadBliCtl_stClsReqRadBliMes_VW_Data 0;
BA_ "GenSigSendType" SG_ 2617119291 DEV_TME_TmeRadBliCtl_stCoBrkRadBliMes_VW_Data 0;
BA_ "GenSigSwitchedByIgnition" SG_ 2617119291 DEV_TME_TmeRadBliCtl_stCoBrkRadBliMes_VW_Data 0;
BA_ "GenSigSendType" SG_ 2617119291 DEV_TME_TmeRadBliCtl_stCoOpRadBliMes_VW_Data 0;
BA_ "GenSigSwitchedByIgnition" SG_ 2617119291 DEV_TME_TmeRadBliCtl_stCoOpRadBliMes_VW_Data 0;
BA_ "GenSigSendType" SG_ 2617119292 DEV_TME_TmeDiag_idxDiagHeatPrfLeak_VW_Data 0;
BA_ "GenSigSwitchedByIgnition" SG_ 2617119292 DEV_TME_TmeDiag_idxDiagHeatPrfLeak_VW_Data 0;
BA_ "GenSigSendType" SG_ 2617119292 DEV_TME_TmeDiag_idxDiagTsVlvInrWaHeatExch_VW_Data 0;
BA_ "GenSigSwitchedByIgnition" SG_ 2617119292 DEV_TME_TmeDiag_idxDiagTsVlvInrWaHeatExch_VW_Data 0;
BA_ "GenSigSendType" SG_ 2617119292 DEV_TME_TmeDiag_stHeatPrfLeak_tCoInRef_VW_Data 0;
BA_ "GenSigSwitchedByIgnition" SG_ 2617119292 DEV_TME_TmeDiag_stHeatPrfLeak_tCoInRef_VW_Data 0;
BA_ "GenSigSendType" SG_ 2617119292 DEV_TME_TmeDiag_stHeatPrfLeak_tDifCoIn_VW_Data 0;
BA_ "GenSigSwitchedByIgnition" SG_ 2617119292 DEV_TME_TmeDiag_stHeatPrfLeak_tDifCoIn_VW_Data 0;
BA_ "GenSigSendType" SG_ 2617119292 DEV_TME_TmeDiag_stHeatPrfLeak_tiHeatUp_VW_Data 0;
BA_ "GenSigSwitchedByIgnition" SG_ 2617119292 DEV_TME_TmeDiag_stHeatPrfLeak_tiHeatUp_VW_Data 0;
BA_ "GenSigSendType" SG_ 2617119292 DEV_TME_TmeDiag_stHeatPrfLeak_tSpDifCoIn_VW_Data 0;
BA_ "GenSigSwitchedByIgnition" SG_ 2617119292 DEV_TME_TmeDiag_stHeatPrfLeak_tSpDifCoIn_VW_Data 0;
BA_ "GenSigSendType" SG_ 2617119292 DEV_TME_CoCir_tVlvInrWaHeatExch_VW_Data 0;
BA_ "GenSigSwitchedByIgnition" SG_ 2617119292 DEV_TME_CoCir_tVlvInrWaHeatExch_VW_Data 0;
BA_ "GenSigSendType" SG_ 2617119292 DEV_TME_TmeDiag_idxDiagVlvInrWaHeatExch_VW_Data 0;
BA_ "GenSigSwitchedByIgnition" SG_ 2617119292 DEV_TME_TmeDiag_idxDiagVlvInrWaHeatExch_VW_Data 0;
BA_ "GenSigSwitchedByIgnition" SG_ 2617119487 DEV_TME_Resp_FF_Data 0;
BA_ "GenSigSendType" SG_ 2549880528 DIA_BJB_Req_Data 3;
BA_ "GenSigFuncType" SG_ 2549880528 DIA_BJB_Req_Data 9;
BA_ "GenSigSwitchedByIgnition" SG_ 2549880528 DIA_BJB_Req_Data 0;
BA_ "GenSigSendType" SG_ 2550011600 DIA_BJB_Resp_Data 3;
BA_ "GenSigFuncType" SG_ 2550011600 DIA_BJB_Resp_Data 9;
BA_ "GenSigSwitchedByIgnition" SG_ 2550011600 DIA_BJB_Resp_Data 0;
BA_ "GenSigSendType" SG_ 2549880529 DIA_CMC_01_Req_Data 3;
BA_ "GenSigFuncType" SG_ 2549880529 DIA_CMC_01_Req_Data 9;
BA_ "GenSigSwitchedByIgnition" SG_ 2549880529 DIA_CMC_01_Req_Data 0;
BA_ "GenSigSendType" SG_ 2550011601 DIA_CMC_01_Resp_Data 3;
BA_ "GenSigFuncType" SG_ 2550011601 DIA_CMC_01_Resp_Data 9;
BA_ "GenSigSwitchedByIgnition" SG_ 2550011601 DIA_CMC_01_Resp_Data 0;
BA_ "GenSigSendType" SG_ 2549880530 DIA_CMC_02_Req_Data 3;
BA_ "GenSigFuncType" SG_ 2549880530 DIA_CMC_02_Req_Data 9;
BA_ "GenSigSwitchedByIgnition" SG_ 2549880530 DIA_CMC_02_Req_Data 0;
BA_ "GenSigSendType" SG_ 2550011602 DIA_CMC_02_Resp_Data 3;
BA_ "GenSigFuncType" SG_ 2550011602 DIA_CMC_02_Resp_Data 9;
BA_ "GenSigSwitchedByIgnition" SG_ 2550011602 DIA_CMC_02_Resp_Data 0;
BA_ "GenSigSendType" SG_ 2549880531 DIA_CMC_03_Req_Data 3;
BA_ "GenSigFuncType" SG_ 2549880531 DIA_CMC_03_Req_Data 9;
BA_ "GenSigSwitchedByIgnition" SG_ 2549880531 DIA_CMC_03_Req_Data 0;
BA_ "GenSigSendType" SG_ 2550011603 DIA_CMC_03_Resp_Data 3;
BA_ "GenSigFuncType" SG_ 2550011603 DIA_CMC_03_Resp_Data 9;
BA_ "GenSigSwitchedByIgnition" SG_ 2550011603 DIA_CMC_03_Resp_Data 0;
BA_ "GenSigSendType" SG_ 2549880532 DIA_CMC_04_Req_Data 3;
BA_ "GenSigFuncType" SG_ 2549880532 DIA_CMC_04_Req_Data 9;
BA_ "GenSigSwitchedByIgnition" SG_ 2549880532 DIA_CMC_04_Req_Data 0;
BA_ "GenSigSendType" SG_ 2550011604 DIA_CMC_04_Resp_Data 3;
BA_ "GenSigFuncType" SG_ 2550011604 DIA_CMC_04_Resp_Data 9;
BA_ "GenSigSwitchedByIgnition" SG_ 2550011604 DIA_CMC_04_Resp_Data 0;
BA_ "GenSigSendType" SG_ 2549880533 DIA_CMC_05_Req_Data 3;
BA_ "GenSigFuncType" SG_ 2549880533 DIA_CMC_05_Req_Data 9;
BA_ "GenSigSwitchedByIgnition" SG_ 2549880533 DIA_CMC_05_Req_Data 0;
BA_ "GenSigSendType" SG_ 2550011605 DIA_CMC_05_Resp_Data 3;
BA_ "GenSigFuncType" SG_ 2550011605 DIA_CMC_05_Resp_Data 9;
BA_ "GenSigSwitchedByIgnition" SG_ 2550011605 DIA_CMC_05_Resp_Data 0;
BA_ "GenSigSendType" SG_ 2549880534 DIA_CMC_06_Req_Data 3;
BA_ "GenSigFuncType" SG_ 2549880534 DIA_CMC_06_Req_Data 9;
BA_ "GenSigSwitchedByIgnition" SG_ 2549880534 DIA_CMC_06_Req_Data 0;
BA_ "GenSigSendType" SG_ 2550011606 DIA_CMC_06_Resp_Data 3;
BA_ "GenSigFuncType" SG_ 2550011606 DIA_CMC_06_Resp_Data 9;
BA_ "GenSigSwitchedByIgnition" SG_ 2550011606 DIA_CMC_06_Resp_Data 0;
BA_ "GenSigSendType" SG_ 2549880535 DIA_CMC_07_Req_Data 3;
BA_ "GenSigFuncType" SG_ 2549880535 DIA_CMC_07_Req_Data 9;
BA_ "GenSigSwitchedByIgnition" SG_ 2549880535 DIA_CMC_07_Req_Data 0;
BA_ "GenSigSendType" SG_ 2550011607 DIA_CMC_07_Resp_Data 3;
BA_ "GenSigFuncType" SG_ 2550011607 DIA_CMC_07_Resp_Data 9;
BA_ "GenSigSwitchedByIgnition" SG_ 2550011607 DIA_CMC_07_Resp_Data 0;
BA_ "GenSigSendType" SG_ 2549880536 DIA_CMC_08_Req_Data 3;
BA_ "GenSigFuncType" SG_ 2549880536 DIA_CMC_08_Req_Data 9;
BA_ "GenSigSwitchedByIgnition" SG_ 2549880536 DIA_CMC_08_Req_Data 0;
BA_ "GenSigSendType" SG_ 2550011608 DIA_CMC_08_Resp_Data 3;
BA_ "GenSigFuncType" SG_ 2550011608 DIA_CMC_08_Resp_Data 9;
BA_ "GenSigSwitchedByIgnition" SG_ 2550011608 DIA_CMC_08_Resp_Data 0;
BA_ "GenSigSendType" SG_ 2549880537 DIA_CMC_09_Req_Data 3;
BA_ "GenSigFuncType" SG_ 2549880537 DIA_CMC_09_Req_Data 9;
BA_ "GenSigSwitchedByIgnition" SG_ 2549880537 DIA_CMC_09_Req_Data 0;
BA_ "GenSigSendType" SG_ 2550011609 DIA_CMC_09_Resp_Data 3;
BA_ "GenSigFuncType" SG_ 2550011609 DIA_CMC_09_Resp_Data 9;
BA_ "GenSigSwitchedByIgnition" SG_ 2550011609 DIA_CMC_09_Resp_Data 0;
BA_ "GenSigSendType" SG_ 2549880538 DIA_CMC_10_Req_Data 3;
BA_ "GenSigFuncType" SG_ 2549880538 DIA_CMC_10_Req_Data 9;
BA_ "GenSigSwitchedByIgnition" SG_ 2549880538 DIA_CMC_10_Req_Data 0;
BA_ "GenSigSendType" SG_ 2550011610 DIA_CMC_10_Resp_Data 3;
BA_ "GenSigFuncType" SG_ 2550011610 DIA_CMC_10_Resp_Data 9;
BA_ "GenSigSwitchedByIgnition" SG_ 2550011610 DIA_CMC_10_Resp_Data 0;
BA_ "GenSigSendType" SG_ 2549880539 DIA_CMC_11_Req_Data 3;
BA_ "GenSigFuncType" SG_ 2549880539 DIA_CMC_11_Req_Data 9;
BA_ "GenSigSwitchedByIgnition" SG_ 2549880539 DIA_CMC_11_Req_Data 0;
BA_ "GenSigSendType" SG_ 2550011611 DIA_CMC_11_Resp_Data 3;
BA_ "GenSigFuncType" SG_ 2550011611 DIA_CMC_11_Resp_Data 9;
BA_ "GenSigSwitchedByIgnition" SG_ 2550011611 DIA_CMC_11_Resp_Data 0;
BA_ "GenSigSendType" SG_ 2549880540 DIA_CMC_12_Req_Data 3;
BA_ "GenSigFuncType" SG_ 2549880540 DIA_CMC_12_Req_Data 9;
BA_ "GenSigSwitchedByIgnition" SG_ 2549880540 DIA_CMC_12_Req_Data 0;
BA_ "GenSigSendType" SG_ 2550011612 DIA_CMC_12_Resp_Data 3;
BA_ "GenSigFuncType" SG_ 2550011612 DIA_CMC_12_Resp_Data 9;
BA_ "GenSigSwitchedByIgnition" SG_ 2550011612 DIA_CMC_12_Resp_Data 0;
BA_ "GenSigSendType" SG_ 2549880561 DIA_CMC_13_Req_Data 3;
BA_ "GenSigFuncType" SG_ 2549880561 DIA_CMC_13_Req_Data 9;
BA_ "GenSigSwitchedByIgnition" SG_ 2549880561 DIA_CMC_13_Req_Data 0;
BA_ "GenSigSendType" SG_ 2550011633 DIA_CMC_13_Resp_Data 3;
BA_ "GenSigFuncType" SG_ 2550011633 DIA_CMC_13_Resp_Data 9;
BA_ "GenSigSwitchedByIgnition" SG_ 2550011633 DIA_CMC_13_Resp_Data 0;
BA_ "GenSigSendType" SG_ 2549880562 DIA_CMC_14_Req_Data 3;
BA_ "GenSigFuncType" SG_ 2549880562 DIA_CMC_14_Req_Data 9;
BA_ "GenSigSwitchedByIgnition" SG_ 2549880562 DIA_CMC_14_Req_Data 0;
BA_ "GenSigSendType" SG_ 2550011634 DIA_CMC_14_Resp_Data 3;
BA_ "GenSigFuncType" SG_ 2550011634 DIA_CMC_14_Resp_Data 9;
BA_ "GenSigSwitchedByIgnition" SG_ 2550011634 DIA_CMC_14_Resp_Data 0;
BA_ "GenSigSendType" SG_ 2549880563 DIA_CMC_15_Req_Data 3;
BA_ "GenSigFuncType" SG_ 2549880563 DIA_CMC_15_Req_Data 9;
BA_ "GenSigSwitchedByIgnition" SG_ 2549880563 DIA_CMC_15_Req_Data 0;
BA_ "GenSigSendType" SG_ 2550011635 DIA_CMC_15_Resp_Data 3;
BA_ "GenSigFuncType" SG_ 2550011635 DIA_CMC_15_Resp_Data 9;
BA_ "GenSigSwitchedByIgnition" SG_ 2550011635 DIA_CMC_15_Resp_Data 0;
BA_ "GenSigSendType" SG_ 2549880413 DIA_EKK_Req_Data 3;
BA_ "GenSigFuncType" SG_ 2549880413 DIA_EKK_Req_Data 9;
BA_ "GenSigSwitchedByIgnition" SG_ 2549880413 DIA_EKK_Req_Data 0;
BA_ "GenSigSendType" SG_ 2550011485 DIA_EKK_Resp_Data 3;
BA_ "GenSigFuncType" SG_ 2550011485 DIA_EKK_Resp_Data 9;
BA_ "GenSigSwitchedByIgnition" SG_ 2550011485 DIA_EKK_Resp_Data 0;
BA_ "GenSigSendType" SG_ 2549880512 DIA_HV_H2_Req_Data 3;
BA_ "GenSigFuncType" SG_ 2549880512 DIA_HV_H2_Req_Data 9;
BA_ "GenSigSwitchedByIgnition" SG_ 2549880512 DIA_HV_H2_Req_Data 0;
BA_ "GenSigSendType" SG_ 2550011584 DIA_HV_H2_Resp_Data 3;
BA_ "GenSigFuncType" SG_ 2550011584 DIA_HV_H2_Resp_Data 9;
BA_ "GenSigSwitchedByIgnition" SG_ 2550011584 DIA_HV_H2_Resp_Data 0;
BA_ "GenSigSendType" SG_ 1714 DGN_Verlernzaehler 0;
BA_ "GenSigSwitchedByIgnition" SG_ 1714 DGN_Verlernzaehler 0;
BA_ "GenSigSendType" SG_ 1714 KBI_Kilometerstand 0;
BA_ "GenSigStartValue" SG_ 1714 KBI_Kilometerstand 1048574;
BA_ "GenSigSwitchedByIgnition" SG_ 1714 KBI_Kilometerstand 0;
BA_ "Fehlerwert" SG_ 1714 KBI_Kilometerstand 1048575;
BA_ "GenSigSendType" SG_ 1714 Kombi_02_alt 0;
BA_ "GenSigStartValue" SG_ 1714 Kombi_02_alt 1;
BA_ "GenSigFuncType" SG_ 1714 Kombi_02_alt 5;
BA_ "GenSigSwitchedByIgnition" SG_ 1714 Kombi_02_alt 0;
BA_ "GenSigSendType" SG_ 1714 UH_Jahr 0;
BA_ "GenSigSwitchedByIgnition" SG_ 1714 UH_Jahr 0;
BA_ "GenSigSendType" SG_ 1714 UH_Minute 0;
BA_ "GenSigSwitchedByIgnition" SG_ 1714 UH_Minute 0;
BA_ "GenSigSendType" SG_ 1714 UH_Monat 0;
BA_ "GenSigSwitchedByIgnition" SG_ 1714 UH_Monat 0;
BA_ "Fehlerwert" SG_ 1714 UH_Monat 15;
BA_ "GenSigSendType" SG_ 1714 UH_Sekunde 0;
BA_ "GenSigSwitchedByIgnition" SG_ 1714 UH_Sekunde 0;
BA_ "GenSigSendType" SG_ 1714 UH_Stunde 0;
BA_ "GenSigSwitchedByIgnition" SG_ 1714 UH_Stunde 0;
BA_ "GenSigSendType" SG_ 1714 UH_Tag 0;
BA_ "GenSigSwitchedByIgnition" SG_ 1714 UH_Tag 0;
BA_ "GenSigSendType" SG_ 1714 Uhrzeit_01_alt 0;
BA_ "GenSigStartValue" SG_ 1714 Uhrzeit_01_alt 1;
BA_ "GenSigFuncType" SG_ 1714 Uhrzeit_01_alt 5;
BA_ "GenSigSwitchedByIgnition" SG_ 1714 Uhrzeit_01_alt 0;
BA_ "GenSigSendType" SG_ 1520 BCM1_Stellgroesse_Kl_58s 3;
BA_ "GenSigStartValue" SG_ 1520 BCM1_Stellgroesse_Kl_58s 126;
BA_ "GenSigSwitchedByIgnition" SG_ 1520 BCM1_Stellgroesse_Kl_58s 0;
BA_ "Fehlerwert" SG_ 1520 BCM1_Stellgroesse_Kl_58s 127;
BA_ "GenSigSendType" SG_ 1520 DI_Display_Nachtdesign 3;
BA_ "GenSigSwitchedByIgnition" SG_ 1520 DI_Display_Nachtdesign 0;
BA_ "GenSigSendType" SG_ 1520 DI_Fotosensor 3;
BA_ "GenSigSwitchedByIgnition" SG_ 1520 DI_Fotosensor 0;
BA_ "GenSigSendType" SG_ 1520 DI_KL_58xd 3;
BA_ "GenSigStartValue" SG_ 1520 DI_KL_58xd 254;
BA_ "GenSigSwitchedByIgnition" SG_ 1520 DI_KL_58xd 0;
BA_ "Fehlerwert" SG_ 1520 DI_KL_58xd 255;
BA_ "GenSigSendType" SG_ 1520 DI_KL_58xs 3;
BA_ "GenSigStartValue" SG_ 1520 DI_KL_58xs 126;
BA_ "GenSigSwitchedByIgnition" SG_ 1520 DI_KL_58xs 0;
BA_ "Fehlerwert" SG_ 1520 DI_KL_58xs 127;
BA_ "GenSigSendType" SG_ 1520 DI_KL_58xt 3;
BA_ "GenSigStartValue" SG_ 1520 DI_KL_58xt 126;
BA_ "GenSigSwitchedByIgnition" SG_ 1520 DI_KL_58xt 0;
BA_ "Fehlerwert" SG_ 1520 DI_KL_58xt 127;
BA_ "GenSigSendType" SG_ 1603 KBI_Einheit_Datum 3;
BA_ "GenSigSwitchedByIgnition" SG_ 1603 KBI_Einheit_Datum 0;
BA_ "GenSigSendType" SG_ 1603 KBI_Einheit_Druck 3;
BA_ "GenSigSwitchedByIgnition" SG_ 1603 KBI_Einheit_Druck 0;
BA_ "GenSigSendType" SG_ 1603 KBI_Einheit_Masse 3;
BA_ "GenSigSwitchedByIgnition" SG_ 1603 KBI_Einheit_Masse 0;
BA_ "GenSigSendType" SG_ 1603 KBI_Einheit_Sprache 3;
BA_ "GenSigSwitchedByIgnition" SG_ 1603 KBI_Einheit_Sprache 0;
BA_ "GenSigSendType" SG_ 1603 KBI_Einheit_Streckenanz 3;
BA_ "GenSigSwitchedByIgnition" SG_ 1603 KBI_Einheit_Streckenanz 0;
BA_ "GenSigSendType" SG_ 1603 KBI_Einheit_Temp 3;
BA_ "GenSigSwitchedByIgnition" SG_ 1603 KBI_Einheit_Temp 0;
BA_ "GenSigSendType" SG_ 1603 KBI_Einheit_Uhrzeit 3;
BA_ "GenSigSwitchedByIgnition" SG_ 1603 KBI_Einheit_Uhrzeit 0;
BA_ "GenSigSendType" SG_ 1603 KBI_Einheit_Verbrauch 3;
BA_ "GenSigSwitchedByIgnition" SG_ 1603 KBI_Einheit_Verbrauch 0;
BA_ "GenSigSendType" SG_ 1603 KBI_Einheit_Verbrauch_elektr 3;
BA_ "GenSigSwitchedByIgnition" SG_ 1603 KBI_Einheit_Verbrauch_elektr 0;
BA_ "GenSigSendType" SG_ 1603 KBI_Einheit_Verbrauch_Gas 3;
BA_ "GenSigSwitchedByIgnition" SG_ 1603 KBI_Einheit_Verbrauch_Gas 0;
BA_ "GenSigSendType" SG_ 1603 KBI_Einheit_Volumen 3;
BA_ "GenSigSwitchedByIgnition" SG_ 1603 KBI_Einheit_Volumen 0;
BA_ "GenSigSendType" SG_ 1603 KBI_MFA_v_Einheit_02 3;
BA_ "GenSigSwitchedByIgnition" SG_ 1603 KBI_MFA_v_Einheit_02 0;
BA_ "GenSigSendType" SG_ 910 EM1_FoD_Freischaltstatus_Fkt1 0;
BA_ "GenSigSwitchedByIgnition" SG_ 910 EM1_FoD_Freischaltstatus_Fkt1 0;
BA_ "GenSigSendType" SG_ 910 EM1_OBD_Lampe_Anf 0;
BA_ "GenSigSwitchedByIgnition" SG_ 910 EM1_OBD_Lampe_Anf 0;
BA_ "GenSigSendType" SG_ 910 EM1_Temperatur_ElMotor 0;
BA_ "GenSigStartValue" SG_ 910 EM1_Temperatur_ElMotor 254;
BA_ "GenSigSwitchedByIgnition" SG_ 910 EM1_Temperatur_ElMotor 0;
BA_ "Fehlerwert" SG_ 910 EM1_Temperatur_ElMotor 255;
BA_ "GenSigSendType" SG_ 910 EM1_Temperatur_KW 0;
BA_ "GenSigStartValue" SG_ 910 EM1_Temperatur_KW 254;
BA_ "GenSigSwitchedByIgnition" SG_ 910 EM1_Temperatur_KW 0;
BA_ "Fehlerwert" SG_ 910 EM1_Temperatur_KW 255;
BA_ "GenSigSendType" SG_ 910 EM1_Temperatur_PWR 0;
BA_ "GenSigStartValue" SG_ 910 EM1_Temperatur_PWR 254;
BA_ "GenSigSwitchedByIgnition" SG_ 910 EM1_Temperatur_PWR 0;
BA_ "Fehlerwert" SG_ 910 EM1_Temperatur_PWR 255;
BA_ "GenSigSendType" SG_ 910 EM1_Temperatur_Rotor 0;
BA_ "GenSigStartValue" SG_ 910 EM1_Temperatur_Rotor 254;
BA_ "GenSigSwitchedByIgnition" SG_ 910 EM1_Temperatur_Rotor 0;
BA_ "Fehlerwert" SG_ 910 EM1_Temperatur_Rotor 255;
BA_ "GenSigSendType" SG_ 910 EM1_Verlustleistung_02 0;
BA_ "GenSigStartValue" SG_ 910 EM1_Verlustleistung_02 1022;
BA_ "GenSigSwitchedByIgnition" SG_ 910 EM1_Verlustleistung_02 0;
BA_ "Fehlerwert" SG_ 910 EM1_Verlustleistung_02 1023;
BA_ "GenSigSendType" SG_ 2527679504 EM1_IstDrehzahl_02 0;
BA_ "GenSigStartValue" SG_ 2527679504 EM1_IstDrehzahl_02 32766;
BA_ "GenSigSwitchedByIgnition" SG_ 2527679504 EM1_IstDrehzahl_02 0;
BA_ "Fehlerwert" SG_ 2527679504 EM1_IstDrehzahl_02 32767;
BA_ "GenSigSendType" SG_ 2527679504 EM1_IstMoment_02 0;
BA_ "GenSigStartValue" SG_ 2527679504 EM1_IstMoment_02 4094;
BA_ "GenSigSwitchedByIgnition" SG_ 2527679504 EM1_IstMoment_02 0;
BA_ "Fehlerwert" SG_ 2527679504 EM1_IstMoment_02 4095;
BA_ "GenSigSendType" SG_ 2527679504 EM1_IstStrom 0;
BA_ "GenSigStartValue" SG_ 2527679504 EM1_IstStrom 2046;
BA_ "GenSigSwitchedByIgnition" SG_ 2527679504 EM1_IstStrom 0;
BA_ "Fehlerwert" SG_ 2527679504 EM1_IstStrom 2047;
BA_ "GenSigSendType" SG_ 2527679504 EM1_Verlustleistung 0;
BA_ "GenSigStartValue" SG_ 2527679504 EM1_Verlustleistung 254;
BA_ "GenSigSwitchedByIgnition" SG_ 2527679504 EM1_Verlustleistung 0;
BA_ "Fehlerwert" SG_ 2527679504 EM1_Verlustleistung 255;
BA_ "GenSigSendType" SG_ 892 EM1_EM_SollVolumenstrom 3;
BA_ "GenSigStartValue" SG_ 892 EM1_EM_SollVolumenstrom 62;
BA_ "GenSigSwitchedByIgnition" SG_ 892 EM1_EM_SollVolumenstrom 0;
BA_ "Fehlerwert" SG_ 892 EM1_EM_SollVolumenstrom 63;
BA_ "GenSigSendType" SG_ 892 EM1_Fehlerstatus 3;
BA_ "GenSigStartValue" SG_ 892 EM1_Fehlerstatus 7;
BA_ "GenSigSwitchedByIgnition" SG_ 892 EM1_Fehlerstatus 0;
BA_ "GenSigSendType" SG_ 892 EM1_HYB_11_BZ 0;
BA_ "GenSigFuncType" SG_ 892 EM1_HYB_11_BZ 1;
BA_ "GenSigSwitchedByIgnition" SG_ 892 EM1_HYB_11_BZ 0;
BA_ "GenSigSendType" SG_ 892 EM1_HYB_11_CRC 0;
BA_ "GenSigFuncType" SG_ 892 EM1_HYB_11_CRC 2;
BA_ "GenSigSwitchedByIgnition" SG_ 892 EM1_HYB_11_CRC 0;
BA_ "GenSigActiveRepetitions" SG_ 892 EM1_HYB_11_Sendestatus 5;
BA_ "GenSigSendType" SG_ 892 EM1_HYB_11_Sendestatus 9;
BA_ "GenSigSwitchedByIgnition" SG_ 892 EM1_HYB_11_Sendestatus 0;
BA_ "GenSigSendType" SG_ 892 EM1_Istmodus2 3;
BA_ "GenSigStartValue" SG_ 892 EM1_Istmodus2 15;
BA_ "GenSigSwitchedByIgnition" SG_ 892 EM1_Istmodus2 0;
BA_ "GenSigSendType" SG_ 892 EM1_Status_Spgfreiheit 3;
BA_ "GenSigSwitchedByIgnition" SG_ 892 EM1_Status_Spgfreiheit 0;
BA_ "GenSigSendType" SG_ 2527679648 EM2_FoD_Freischaltstatus_Fkt1 0;
BA_ "GenSigSwitchedByIgnition" SG_ 2527679648 EM2_FoD_Freischaltstatus_Fkt1 0;
BA_ "GenSigSendType" SG_ 2527679648 EM2_OBD_Lampe_Anf 0;
BA_ "GenSigSwitchedByIgnition" SG_ 2527679648 EM2_OBD_Lampe_Anf 0;
BA_ "GenSigSendType" SG_ 2527679648 EM2_Temperatur_ElMotor 0;
BA_ "GenSigStartValue" SG_ 2527679648 EM2_Temperatur_ElMotor 254;
BA_ "GenSigSwitchedByIgnition" SG_ 2527679648 EM2_Temperatur_ElMotor 0;
BA_ "Fehlerwert" SG_ 2527679648 EM2_Temperatur_ElMotor 255;
BA_ "GenSigSendType" SG_ 2527679648 EM2_Temperatur_KW 0;
BA_ "GenSigStartValue" SG_ 2527679648 EM2_Temperatur_KW 254;
BA_ "GenSigSwitchedByIgnition" SG_ 2527679648 EM2_Temperatur_KW 0;
BA_ "Fehlerwert" SG_ 2527679648 EM2_Temperatur_KW 255;
BA_ "GenSigSendType" SG_ 2527679648 EM2_Temperatur_PWR 0;
BA_ "GenSigStartValue" SG_ 2527679648 EM2_Temperatur_PWR 254;
BA_ "GenSigSwitchedByIgnition" SG_ 2527679648 EM2_Temperatur_PWR 0;
BA_ "Fehlerwert" SG_ 2527679648 EM2_Temperatur_PWR 255;
BA_ "GenSigSendType" SG_ 2527679648 EM2_Temperatur_Rotor 0;
BA_ "GenSigStartValue" SG_ 2527679648 EM2_Temperatur_Rotor 254;
BA_ "GenSigSwitchedByIgnition" SG_ 2527679648 EM2_Temperatur_Rotor 0;
BA_ "Fehlerwert" SG_ 2527679648 EM2_Temperatur_Rotor 255;
BA_ "GenSigSendType" SG_ 2527679648 EM2_Verlustleistung_02 0;
BA_ "GenSigStartValue" SG_ 2527679648 EM2_Verlustleistung_02 1022;
BA_ "GenSigSwitchedByIgnition" SG_ 2527679648 EM2_Verlustleistung_02 0;
BA_ "Fehlerwert" SG_ 2527679648 EM2_Verlustleistung_02 1023;
BA_ "GenSigSendType" SG_ 2463978615 EM2_EM_SollVolumenstrom 3;
BA_ "GenSigStartValue" SG_ 2463978615 EM2_EM_SollVolumenstrom 62;
BA_ "GenSigSwitchedByIgnition" SG_ 2463978615 EM2_EM_SollVolumenstrom 0;
BA_ "Fehlerwert" SG_ 2463978615 EM2_EM_SollVolumenstrom 63;
BA_ "GenSigSendType" SG_ 2463978615 EM2_Fehlerstatus 3;
BA_ "GenSigStartValue" SG_ 2463978615 EM2_Fehlerstatus 7;
BA_ "GenSigSwitchedByIgnition" SG_ 2463978615 EM2_Fehlerstatus 0;
BA_ "GenSigSendType" SG_ 2463978615 EM2_HYB_11_BZ 0;
BA_ "GenSigFuncType" SG_ 2463978615 EM2_HYB_11_BZ 1;
BA_ "GenSigSwitchedByIgnition" SG_ 2463978615 EM2_HYB_11_BZ 0;
BA_ "GenSigSendType" SG_ 2463978615 EM2_HYB_11_CRC 0;
BA_ "GenSigFuncType" SG_ 2463978615 EM2_HYB_11_CRC 2;
BA_ "GenSigSwitchedByIgnition" SG_ 2463978615 EM2_HYB_11_CRC 0;
BA_ "GenSigActiveRepetitions" SG_ 2463978615 EM2_HYB_11_Sendestatus 5;
BA_ "GenSigSendType" SG_ 2463978615 EM2_HYB_11_Sendestatus 9;
BA_ "GenSigSwitchedByIgnition" SG_ 2463978615 EM2_HYB_11_Sendestatus 0;
BA_ "GenSigSendType" SG_ 2463978615 EM2_Istmodus2 3;
BA_ "GenSigStartValue" SG_ 2463978615 EM2_Istmodus2 15;
BA_ "GenSigSwitchedByIgnition" SG_ 2463978615 EM2_Istmodus2 0;
BA_ "GenSigSendType" SG_ 2463978615 EM2_Status_Spgfreiheit 3;
BA_ "GenSigSwitchedByIgnition" SG_ 2463978615 EM2_Status_Spgfreiheit 0;
BA_ "GenSigSendType" SG_ 2527679649 EM3_FoD_Freischaltstatus_Fkt1 0;
BA_ "GenSigSwitchedByIgnition" SG_ 2527679649 EM3_FoD_Freischaltstatus_Fkt1 0;
BA_ "GenSigSendType" SG_ 2527679649 EM3_OBD_Lampe_Anf 0;
BA_ "GenSigSwitchedByIgnition" SG_ 2527679649 EM3_OBD_Lampe_Anf 0;
BA_ "GenSigSendType" SG_ 2527679649 EM3_Temperatur_ElMotor 0;
BA_ "GenSigStartValue" SG_ 2527679649 EM3_Temperatur_ElMotor 254;
BA_ "GenSigSwitchedByIgnition" SG_ 2527679649 EM3_Temperatur_ElMotor 0;
BA_ "Fehlerwert" SG_ 2527679649 EM3_Temperatur_ElMotor 255;
BA_ "GenSigSendType" SG_ 2527679649 EM3_Temperatur_KW 0;
BA_ "GenSigStartValue" SG_ 2527679649 EM3_Temperatur_KW 254;
BA_ "GenSigSwitchedByIgnition" SG_ 2527679649 EM3_Temperatur_KW 0;
BA_ "Fehlerwert" SG_ 2527679649 EM3_Temperatur_KW 255;
BA_ "GenSigSendType" SG_ 2527679649 EM3_Temperatur_PWR 0;
BA_ "GenSigStartValue" SG_ 2527679649 EM3_Temperatur_PWR 254;
BA_ "GenSigSwitchedByIgnition" SG_ 2527679649 EM3_Temperatur_PWR 0;
BA_ "Fehlerwert" SG_ 2527679649 EM3_Temperatur_PWR 255;
BA_ "GenSigSendType" SG_ 2527679649 EM3_Temperatur_Rotor 0;
BA_ "GenSigStartValue" SG_ 2527679649 EM3_Temperatur_Rotor 254;
BA_ "GenSigSwitchedByIgnition" SG_ 2527679649 EM3_Temperatur_Rotor 0;
BA_ "Fehlerwert" SG_ 2527679649 EM3_Temperatur_Rotor 255;
BA_ "GenSigSendType" SG_ 2527679649 EM3_Verlustleistung_02 0;
BA_ "GenSigStartValue" SG_ 2527679649 EM3_Verlustleistung_02 1022;
BA_ "GenSigSwitchedByIgnition" SG_ 2527679649 EM3_Verlustleistung_02 0;
BA_ "Fehlerwert" SG_ 2527679649 EM3_Verlustleistung_02 1023;
BA_ "GenSigSendType" SG_ 2463978616 EM3_EM_SollVolumenstrom 3;
BA_ "GenSigStartValue" SG_ 2463978616 EM3_EM_SollVolumenstrom 62;
BA_ "GenSigSwitchedByIgnition" SG_ 2463978616 EM3_EM_SollVolumenstrom 0;
BA_ "Fehlerwert" SG_ 2463978616 EM3_EM_SollVolumenstrom 63;
BA_ "GenSigSendType" SG_ 2463978616 EM3_Fehlerstatus 3;
BA_ "GenSigStartValue" SG_ 2463978616 EM3_Fehlerstatus 7;
BA_ "GenSigSwitchedByIgnition" SG_ 2463978616 EM3_Fehlerstatus 0;
BA_ "GenSigSendType" SG_ 2463978616 EM3_HYB_11_BZ 0;
BA_ "GenSigFuncType" SG_ 2463978616 EM3_HYB_11_BZ 1;
BA_ "GenSigSwitchedByIgnition" SG_ 2463978616 EM3_HYB_11_BZ 0;
BA_ "GenSigSendType" SG_ 2463978616 EM3_HYB_11_CRC 0;
BA_ "GenSigFuncType" SG_ 2463978616 EM3_HYB_11_CRC 2;
BA_ "GenSigSwitchedByIgnition" SG_ 2463978616 EM3_HYB_11_CRC 0;
BA_ "GenSigActiveRepetitions" SG_ 2463978616 EM3_HYB_11_Sendestatus 5;
BA_ "GenSigSendType" SG_ 2463978616 EM3_HYB_11_Sendestatus 9;
BA_ "GenSigSwitchedByIgnition" SG_ 2463978616 EM3_HYB_11_Sendestatus 0;
BA_ "GenSigSendType" SG_ 2463978616 EM3_Istmodus2 3;
BA_ "GenSigStartValue" SG_ 2463978616 EM3_Istmodus2 15;
BA_ "GenSigSwitchedByIgnition" SG_ 2463978616 EM3_Istmodus2 0;
BA_ "GenSigSendType" SG_ 2463978616 EM3_Status_Spgfreiheit 3;
BA_ "GenSigSwitchedByIgnition" SG_ 2463978616 EM3_Status_Spgfreiheit 0;
BA_ "GenSigSendType" SG_ 2589283600 EMG_CALID_CVN_MUX 0;
BA_ "GenSigSwitchedByIgnition" SG_ 2589283600 EMG_CALID_CVN_MUX 0;
BA_ "GenSigStartValue" SG_ 2589283600 EMG_CALID_Index_01 48;
BA_ "GenSigSwitchedByIgnition" SG_ 2589283600 EMG_CALID_Index_01 0;
BA_ "GenSigStartValue" SG_ 2589283600 EMG_CALID_Index_02 48;
BA_ "GenSigSwitchedByIgnition" SG_ 2589283600 EMG_CALID_Index_02 0;
BA_ "GenSigStartValue" SG_ 2589283600 EMG_CALID_Index_03 48;
BA_ "GenSigSwitchedByIgnition" SG_ 2589283600 EMG_CALID_Index_03 0;
BA_ "GenSigStartValue" SG_ 2589283600 EMG_CALID_Index_04 48;
BA_ "GenSigSwitchedByIgnition" SG_ 2589283600 EMG_CALID_Index_04 0;
BA_ "GenSigStartValue" SG_ 2589283600 EMG_CALID_Index_05 48;
BA_ "GenSigSwitchedByIgnition" SG_ 2589283600 EMG_CALID_Index_05 0;
BA_ "GenSigStartValue" SG_ 2589283600 EMG_CALID_Index_06 48;
BA_ "GenSigSwitchedByIgnition" SG_ 2589283600 EMG_CALID_Index_06 0;
BA_ "GenSigStartValue" SG_ 2589283600 EMG_CALID_Index_07 48;
BA_ "GenSigSwitchedByIgnition" SG_ 2589283600 EMG_CALID_Index_07 0;
BA_ "GenSigStartValue" SG_ 2589283600 EMG_CALID_Index_08 48;
BA_ "GenSigSwitchedByIgnition" SG_ 2589283600 EMG_CALID_Index_08 0;
BA_ "GenSigStartValue" SG_ 2589283600 EMG_CALID_Index_09 48;
BA_ "GenSigSwitchedByIgnition" SG_ 2589283600 EMG_CALID_Index_09 0;
BA_ "GenSigStartValue" SG_ 2589283600 EMG_CALID_Index_10 48;
BA_ "GenSigSwitchedByIgnition" SG_ 2589283600 EMG_CALID_Index_10 0;
BA_ "GenSigStartValue" SG_ 2589283600 EMG_CALID_Index_11 48;
BA_ "GenSigSwitchedByIgnition" SG_ 2589283600 EMG_CALID_Index_11 0;
BA_ "GenSigStartValue" SG_ 2589283600 EMG_CALID_Index_12 48;
BA_ "GenSigSwitchedByIgnition" SG_ 2589283600 EMG_CALID_Index_12 0;
BA_ "GenSigStartValue" SG_ 2589283600 EMG_CALID_Index_13 48;
BA_ "GenSigSwitchedByIgnition" SG_ 2589283600 EMG_CALID_Index_13 0;
BA_ "GenSigStartValue" SG_ 2589283600 EMG_CALID_Index_14 48;
BA_ "GenSigSwitchedByIgnition" SG_ 2589283600 EMG_CALID_Index_14 0;
BA_ "GenSigStartValue" SG_ 2589283600 EMG_CALID_Index_15 48;
BA_ "GenSigSwitchedByIgnition" SG_ 2589283600 EMG_CALID_Index_15 0;
BA_ "GenSigStartValue" SG_ 2589283600 EMG_CALID_Index_16 48;
BA_ "GenSigSwitchedByIgnition" SG_ 2589283600 EMG_CALID_Index_16 0;
BA_ "GenSigSwitchedByIgnition" SG_ 2589283600 EMG_CVN_Byte_1 0;
BA_ "GenSigSwitchedByIgnition" SG_ 2589283600 EMG_CVN_Byte_2 0;
BA_ "GenSigSwitchedByIgnition" SG_ 2589283600 EMG_CVN_Byte_3 0;
BA_ "GenSigSwitchedByIgnition" SG_ 2589283600 EMG_CVN_Byte_4 0;
BA_ "GenSigSendType" SG_ 2589283600 EMG_CVN_VLD 0;
BA_ "GenSigSwitchedByIgnition" SG_ 2589283600 EMG_CVN_VLD 0;
BA_ "GenSigSendType" SG_ 2589283495 EMG_Komponentenfehler_01 0;
BA_ "GenSigStartValue" SG_ 2589283495 EMG_Komponentenfehler_01 2;
BA_ "GenSigSwitchedByIgnition" SG_ 2589283495 EMG_Komponentenfehler_01 0;
BA_ "GenSigSendType" SG_ 2589283495 EMG_Komponentenfehler_02 0;
BA_ "GenSigStartValue" SG_ 2589283495 EMG_Komponentenfehler_02 2;
BA_ "GenSigSwitchedByIgnition" SG_ 2589283495 EMG_Komponentenfehler_02 0;
BA_ "GenSigSendType" SG_ 2589283495 EMG_Komponentenfehler_03 0;
BA_ "GenSigStartValue" SG_ 2589283495 EMG_Komponentenfehler_03 2;
BA_ "GenSigSwitchedByIgnition" SG_ 2589283495 EMG_Komponentenfehler_03 0;
BA_ "GenSigSendType" SG_ 2589283495 EMG_Komponentenfehler_04 0;
BA_ "GenSigStartValue" SG_ 2589283495 EMG_Komponentenfehler_04 2;
BA_ "GenSigSwitchedByIgnition" SG_ 2589283495 EMG_Komponentenfehler_04 0;
BA_ "GenSigSendType" SG_ 2589283495 EMG_Komponentenfehler_05 0;
BA_ "GenSigStartValue" SG_ 2589283495 EMG_Komponentenfehler_05 2;
BA_ "GenSigSwitchedByIgnition" SG_ 2589283495 EMG_Komponentenfehler_05 0;
BA_ "GenSigSendType" SG_ 2589283495 EMG_Komponentenfehler_06 0;
BA_ "GenSigStartValue" SG_ 2589283495 EMG_Komponentenfehler_06 2;
BA_ "GenSigSwitchedByIgnition" SG_ 2589283495 EMG_Komponentenfehler_06 0;
BA_ "GenSigSendType" SG_ 2589283495 EMG_Komponentenfehler_07 0;
BA_ "GenSigStartValue" SG_ 2589283495 EMG_Komponentenfehler_07 2;
BA_ "GenSigSwitchedByIgnition" SG_ 2589283495 EMG_Komponentenfehler_07 0;
BA_ "GenSigSendType" SG_ 2589283495 EMG_Komponentenfehler_08 0;
BA_ "GenSigStartValue" SG_ 2589283495 EMG_Komponentenfehler_08 2;
BA_ "GenSigSwitchedByIgnition" SG_ 2589283495 EMG_Komponentenfehler_08 0;
BA_ "GenSigSendType" SG_ 2589283495 EMG_Komponentenfehler_09 0;
BA_ "GenSigStartValue" SG_ 2589283495 EMG_Komponentenfehler_09 2;
BA_ "GenSigSwitchedByIgnition" SG_ 2589283495 EMG_Komponentenfehler_09 0;
BA_ "GenSigSendType" SG_ 2589283495 EMG_Komponentenfehler_VLD 0;
BA_ "GenSigSwitchedByIgnition" SG_ 2589283495 EMG_Komponentenfehler_VLD 0;
BA_ "GenSigSendType" SG_ 278 ESP_10_BZ 0;
BA_ "GenSigFuncType" SG_ 278 ESP_10_BZ 1;
BA_ "GenSigSwitchedByIgnition" SG_ 278 ESP_10_BZ 0;
BA_ "GenSigSendType" SG_ 278 ESP_10_CRC 0;
BA_ "GenSigFuncType" SG_ 278 ESP_10_CRC 2;
BA_ "GenSigSwitchedByIgnition" SG_ 278 ESP_10_CRC 0;
BA_ "GenSigSendType" SG_ 278 ESP_HL_Fahrtrichtung 0;
BA_ "GenSigStartValue" SG_ 278 ESP_HL_Fahrtrichtung 2;
BA_ "GenSigSwitchedByIgnition" SG_ 278 ESP_HL_Fahrtrichtung 0;
BA_ "GenSigSendType" SG_ 278 ESP_HR_Fahrtrichtung 0;
BA_ "GenSigStartValue" SG_ 278 ESP_HR_Fahrtrichtung 2;
BA_ "GenSigSwitchedByIgnition" SG_ 278 ESP_HR_Fahrtrichtung 0;
BA_ "GenSigSendType" SG_ 278 ESP_QBit_Wegimpuls_HL 0;
BA_ "GenSigStartValue" SG_ 278 ESP_QBit_Wegimpuls_HL 1;
BA_ "GenSigSwitchedByIgnition" SG_ 278 ESP_QBit_Wegimpuls_HL 0;
BA_ "GenSigSendType" SG_ 278 ESP_QBit_Wegimpuls_HR 0;
BA_ "GenSigStartValue" SG_ 278 ESP_QBit_Wegimpuls_HR 1;
BA_ "GenSigSwitchedByIgnition" SG_ 278 ESP_QBit_Wegimpuls_HR 0;
BA_ "GenSigSendType" SG_ 278 ESP_QBit_Wegimpuls_VL 0;
BA_ "GenSigStartValue" SG_ 278 ESP_QBit_Wegimpuls_VL 1;
BA_ "GenSigSwitchedByIgnition" SG_ 278 ESP_QBit_Wegimpuls_VL 0;
BA_ "GenSigSendType" SG_ 278 ESP_QBit_Wegimpuls_VR 0;
BA_ "GenSigStartValue" SG_ 278 ESP_QBit_Wegimpuls_VR 1;
BA_ "GenSigSwitchedByIgnition" SG_ 278 ESP_QBit_Wegimpuls_VR 0;
BA_ "GenSigSendType" SG_ 278 ESP_VL_Fahrtrichtung 0;
BA_ "GenSigStartValue" SG_ 278 ESP_VL_Fahrtrichtung 2;
BA_ "GenSigSwitchedByIgnition" SG_ 278 ESP_VL_Fahrtrichtung 0;
BA_ "GenSigSendType" SG_ 278 ESP_VR_Fahrtrichtung 0;
BA_ "GenSigStartValue" SG_ 278 ESP_VR_Fahrtrichtung 2;
BA_ "GenSigSwitchedByIgnition" SG_ 278 ESP_VR_Fahrtrichtung 0;
BA_ "GenSigSendType" SG_ 278 ESP_Wegimpuls_HL 0;
BA_ "GenSigStartValue" SG_ 278 ESP_Wegimpuls_HL 1021;
BA_ "GenSigSwitchedByIgnition" SG_ 278 ESP_Wegimpuls_HL 0;
BA_ "Fehlerwert" SG_ 278 ESP_Wegimpuls_HL 1023;
BA_ "GenSigSendType" SG_ 278 ESP_Wegimpuls_HR 0;
BA_ "GenSigStartValue" SG_ 278 ESP_Wegimpuls_HR 1021;
BA_ "GenSigSwitchedByIgnition" SG_ 278 ESP_Wegimpuls_HR 0;
BA_ "Fehlerwert" SG_ 278 ESP_Wegimpuls_HR 1023;
BA_ "GenSigSendType" SG_ 278 ESP_Wegimpuls_VL 0;
BA_ "GenSigStartValue" SG_ 278 ESP_Wegimpuls_VL 1021;
BA_ "GenSigSwitchedByIgnition" SG_ 278 ESP_Wegimpuls_VL 0;
BA_ "Fehlerwert" SG_ 278 ESP_Wegimpuls_VL 1023;
BA_ "GenSigSendType" SG_ 278 ESP_Wegimpuls_VR 0;
BA_ "GenSigStartValue" SG_ 278 ESP_Wegimpuls_VR 1021;
BA_ "GenSigSwitchedByIgnition" SG_ 278 ESP_Wegimpuls_VR 0;
BA_ "Fehlerwert" SG_ 278 ESP_Wegimpuls_VR 1023;
BA_ "GenSigSendType" SG_ 418 ESP_15_BZ 0;
BA_ "GenSigFuncType" SG_ 418 ESP_15_BZ 1;
BA_ "GenSigSwitchedByIgnition" SG_ 418 ESP_15_BZ 0;
BA_ "GenSigSendType" SG_ 418 ESP_15_CRC 0;
BA_ "GenSigFuncType" SG_ 418 ESP_15_CRC 2;
BA_ "GenSigSwitchedByIgnition" SG_ 418 ESP_15_CRC 0;
BA_ "GenSigSendType" SG_ 418 ESP_Haltemoment 0;
BA_ "GenSigStartValue" SG_ 418 ESP_Haltemoment 1022;
BA_ "GenSigSwitchedByIgnition" SG_ 418 ESP_Haltemoment 0;
BA_ "Fehlerwert" SG_ 418 ESP_Haltemoment 1023;
BA_ "GenSigSendType" SG_ 418 ESP_Index_Haltemoment 0;
BA_ "GenSigSwitchedByIgnition" SG_ 418 ESP_Index_Haltemoment 0;
BA_ "GenSigSendType" SG_ 418 HMS_aktives_System 3;
BA_ "GenSigSwitchedByIgnition" SG_ 418 HMS_aktives_System 0;
BA_ "GenSigSendType" SG_ 418 HMS_Anforderung_GE 0;
BA_ "GenSigSwitchedByIgnition" SG_ 418 HMS_Anforderung_GE 0;
BA_ "GenSigSendType" SG_ 418 HMS_Fehlerstatus 3;
BA_ "GenSigSwitchedByIgnition" SG_ 418 HMS_Fehlerstatus 0;
BA_ "GenSigSendType" SG_ 418 HMS_halten_nicht_verfuegbar 0;
BA_ "GenSigSwitchedByIgnition" SG_ 418 HMS_halten_nicht_verfuegbar 0;
BA_ "GenSigSendType" SG_ 418 HMS_Konsistenz_ACC 0;
BA_ "GenSigSwitchedByIgnition" SG_ 418 HMS_Konsistenz_ACC 0;
BA_ "GenSigSendType" SG_ 418 HMS_Konsistenz_GE 0;
BA_ "GenSigSwitchedByIgnition" SG_ 418 HMS_Konsistenz_GE 0;
BA_ "GenSigSendType" SG_ 418 HMS_Konsistenz_HVLM 3;
BA_ "GenSigSwitchedByIgnition" SG_ 418 HMS_Konsistenz_HVLM 0;
BA_ "GenSigSendType" SG_ 418 HMS_Konsistenz_IPA 3;
BA_ "GenSigSwitchedByIgnition" SG_ 418 HMS_Konsistenz_IPA 0;
BA_ "GenSigSendType" SG_ 418 HMS_Konsistenz_MO 0;
BA_ "GenSigSwitchedByIgnition" SG_ 418 HMS_Konsistenz_MO 0;
BA_ "GenSigSendType" SG_ 418 HMS_Konsistenz_STA 0;
BA_ "GenSigSwitchedByIgnition" SG_ 418 HMS_Konsistenz_STA 0;
BA_ "GenSigSendType" SG_ 418 HMS_Notstopp_Status 0;
BA_ "GenSigSwitchedByIgnition" SG_ 418 HMS_Notstopp_Status 0;
BA_ "GenSigSendType" SG_ 418 HMS_P_beibehalten_GE 0;
BA_ "GenSigStartValue" SG_ 418 HMS_P_beibehalten_GE 2;
BA_ "GenSigSwitchedByIgnition" SG_ 418 HMS_P_beibehalten_GE 0;
BA_ "Fehlerwert" SG_ 418 HMS_P_beibehalten_GE 3;
BA_ "GenSigSendType" SG_ 418 HMS_parken_nicht_verfuegbar 0;
BA_ "GenSigSwitchedByIgnition" SG_ 418 HMS_parken_nicht_verfuegbar 0;
BA_ "GenSigSendType" SG_ 418 HMS_Stillstand 3;
BA_ "GenSigStartValue" SG_ 418 HMS_Stillstand 6;
BA_ "GenSigSwitchedByIgnition" SG_ 418 HMS_Stillstand 0;
BA_ "Fehlerwert" SG_ 418 HMS_Stillstand 7;
BA_ "GenSigSendType" SG_ 418 HMS_Systemstatus 3;
BA_ "GenSigStartValue" SG_ 418 HMS_Systemstatus 14;
BA_ "GenSigSwitchedByIgnition" SG_ 418 HMS_Systemstatus 0;
BA_ "Fehlerwert" SG_ 418 HMS_Systemstatus 15;
BA_ "GenSigSendType" SG_ 418 NL_PRIM_STP_01_Status 0;
BA_ "GenSigSwitchedByIgnition" SG_ 418 NL_PRIM_STP_01_Status 0;
BA_ "GenSigSendType" SG_ 418 VMM_Warnblinken 3;
BA_ "GenSigSwitchedByIgnition" SG_ 418 VMM_Warnblinken 0;
BA_ "GenSigSendType" SG_ 418 VZM_Status 0;
BA_ "GenSigSwitchedByIgnition" SG_ 418 VZM_Status 0;
BA_ "Fehlerwert" SG_ 418 VZM_Status 4;
BA_ "GenSigSendType" SG_ 1629 BR_QBit_Reifenumfang 0;
BA_ "GenSigStartValue" SG_ 1629 BR_QBit_Reifenumfang 1;
BA_ "GenSigSwitchedByIgnition" SG_ 1629 BR_QBit_Reifenumfang 0;
BA_ "GenSigSendType" SG_ 1629 BR_Reifenumfang 0;
BA_ "GenSigSwitchedByIgnition" SG_ 1629 BR_Reifenumfang 0;
BA_ "GenSigSendType" SG_ 1629 BR_Systemart 0;
BA_ "GenSigFuncType" SG_ 1629 BR_Systemart 8;
BA_ "GenSigSwitchedByIgnition" SG_ 1629 BR_Systemart 0;
BA_ "GenSigSendType" SG_ 1629 ESP_20_BZ 0;
BA_ "GenSigFuncType" SG_ 1629 ESP_20_BZ 1;
BA_ "GenSigSwitchedByIgnition" SG_ 1629 ESP_20_BZ 0;
BA_ "GenSigSendType" SG_ 1629 ESP_20_CRC 0;
BA_ "GenSigFuncType" SG_ 1629 ESP_20_CRC 2;
BA_ "GenSigSwitchedByIgnition" SG_ 1629 ESP_20_CRC 0;
BA_ "GenSigSendType" SG_ 1629 ESP_Charisma_FahrPr 0;
BA_ "GenSigSwitchedByIgnition" SG_ 1629 ESP_Charisma_FahrPr 0;
BA_ "GenSigSendType" SG_ 1629 ESP_Charisma_Status 0;
BA_ "GenSigSwitchedByIgnition" SG_ 1629 ESP_Charisma_Status 0;
BA_ "GenSigSendType" SG_ 1629 ESP_Dachrelingsensor 0;
BA_ "GenSigSwitchedByIgnition" SG_ 1629 ESP_Dachrelingsensor 0;
BA_ "Fehlerwert" SG_ 1629 ESP_Dachrelingsensor 3;
BA_ "GenSigSendType" SG_ 1629 ESP_SpannungsAnf_02 0;
BA_ "GenSigSwitchedByIgnition" SG_ 1629 ESP_SpannungsAnf_02 0;
BA_ "GenSigSendType" SG_ 1629 ESP_Stoppverbot_Anz_01 0;
BA_ "GenSigSwitchedByIgnition" SG_ 1629 ESP_Stoppverbot_Anz_01 0;
BA_ "GenSigSendType" SG_ 1629 ESP_Stoppverbot_Anz_02 0;
BA_ "GenSigSwitchedByIgnition" SG_ 1629 ESP_Stoppverbot_Anz_02 0;
BA_ "GenSigSendType" SG_ 1629 ESP_Stoppverbot_Anz_03 0;
BA_ "GenSigSwitchedByIgnition" SG_ 1629 ESP_Stoppverbot_Anz_03 0;
BA_ "GenSigSendType" SG_ 1629 ESP_Stoppverbot_Anz_04 0;
BA_ "GenSigSwitchedByIgnition" SG_ 1629 ESP_Stoppverbot_Anz_04 0;
BA_ "GenSigSendType" SG_ 1629 ESP_Stoppverbot_Anz_05 0;
BA_ "GenSigSwitchedByIgnition" SG_ 1629 ESP_Stoppverbot_Anz_05 0;
BA_ "GenSigSendType" SG_ 1629 ESP_Stoppverbot_Anz_06 0;
BA_ "GenSigSwitchedByIgnition" SG_ 1629 ESP_Stoppverbot_Anz_06 0;
BA_ "GenSigSendType" SG_ 1629 ESP_Stoppverbot_Anz_07 0;
BA_ "GenSigSwitchedByIgnition" SG_ 1629 ESP_Stoppverbot_Anz_07 0;
BA_ "GenSigSendType" SG_ 1629 ESP_Stoppverbot_Anz_08 0;
BA_ "GenSigSwitchedByIgnition" SG_ 1629 ESP_Stoppverbot_Anz_08 0;
BA_ "GenSigSendType" SG_ 1629 ESP_Stoppverbot_Anz_Std 0;
BA_ "GenSigSwitchedByIgnition" SG_ 1629 ESP_Stoppverbot_Anz_Std 0;
BA_ "GenSigSendType" SG_ 1629 ESP_Wiederstart_Anz_01 0;
BA_ "GenSigSwitchedByIgnition" SG_ 1629 ESP_Wiederstart_Anz_01 0;
BA_ "GenSigSendType" SG_ 1629 ESP_Wiederstart_Anz_02 0;
BA_ "GenSigSwitchedByIgnition" SG_ 1629 ESP_Wiederstart_Anz_02 0;
BA_ "GenSigSendType" SG_ 1629 ESP_Wiederstart_Anz_03 0;
BA_ "GenSigSwitchedByIgnition" SG_ 1629 ESP_Wiederstart_Anz_03 0;
BA_ "GenSigSendType" SG_ 1629 ESP_Wiederstart_Anz_04 0;
BA_ "GenSigSwitchedByIgnition" SG_ 1629 ESP_Wiederstart_Anz_04 0;
BA_ "GenSigSendType" SG_ 1629 ESP_Zaehnezahl 0;
BA_ "GenSigFuncType" SG_ 1629 ESP_Zaehnezahl 8;
BA_ "GenSigSwitchedByIgnition" SG_ 1629 ESP_Zaehnezahl 0;
BA_ "GenSigSendType" SG_ 1629 HDC_Charisma_FahrPr 0;
BA_ "GenSigSwitchedByIgnition" SG_ 1629 HDC_Charisma_FahrPr 0;
BA_ "GenSigSendType" SG_ 1629 HDC_Charisma_Status 0;
BA_ "GenSigSwitchedByIgnition" SG_ 1629 HDC_Charisma_Status 0;
BA_ "GenSigSendType" SG_ 253 ABS_Bremsung 0;
BA_ "GenSigSwitchedByIgnition" SG_ 253 ABS_Bremsung 0;
BA_ "GenSigSendType" SG_ 253 ASR_Anf 0;
BA_ "GenSigSwitchedByIgnition" SG_ 253 ASR_Anf 0;
BA_ "GenSigSendType" SG_ 253 ASR_Schalteingriff 0;
BA_ "GenSigSwitchedByIgnition" SG_ 253 ASR_Schalteingriff 0;
BA_ "GenSigSendType" SG_ 253 ASR_Tastung_passiv 0;
BA_ "GenSigSwitchedByIgnition" SG_ 253 ASR_Tastung_passiv 0;
BA_ "GenSigSendType" SG_ 253 BR_Eingriffsmoment 0;
BA_ "GenSigStartValue" SG_ 253 BR_Eingriffsmoment 1022;
BA_ "GenSigSwitchedByIgnition" SG_ 253 BR_Eingriffsmoment 0;
BA_ "Fehlerwert" SG_ 253 BR_Eingriffsmoment 1023;
BA_ "GenSigSendType" SG_ 253 EBV_Eingriff 0;
BA_ "GenSigSwitchedByIgnition" SG_ 253 EBV_Eingriff 0;
BA_ "GenSigSendType" SG_ 253 EDS_Eingriff 0;
BA_ "GenSigSwitchedByIgnition" SG_ 253 EDS_Eingriff 0;
BA_ "GenSigSendType" SG_ 253 ESC_Neutralschaltung 0;
BA_ "GenSigSwitchedByIgnition" SG_ 253 ESC_Neutralschaltung 0;
BA_ "GenSigSendType" SG_ 253 ESC_v_Signal_Qualifier_High_Low 0;
BA_ "GenSigStartValue" SG_ 253 ESC_v_Signal_Qualifier_High_Low 6;
BA_ "GenSigSwitchedByIgnition" SG_ 253 ESC_v_Signal_Qualifier_High_Low 0;
BA_ "Fehlerwert" SG_ 253 ESC_v_Signal_Qualifier_High_Low 7;
BA_ "GenSigSendType" SG_ 253 ESP_21_BZ 0;
BA_ "GenSigFuncType" SG_ 253 ESP_21_BZ 1;
BA_ "GenSigSwitchedByIgnition" SG_ 253 ESP_21_BZ 0;
BA_ "GenSigSendType" SG_ 253 ESP_21_CRC 0;
BA_ "GenSigFuncType" SG_ 253 ESP_21_CRC 2;
BA_ "GenSigSwitchedByIgnition" SG_ 253 ESP_21_CRC 0;
BA_ "GenSigSendType" SG_ 253 ESP_ASP 0;
BA_ "GenSigSwitchedByIgnition" SG_ 253 ESP_ASP 0;
BA_ "GenSigSendType" SG_ 253 ESP_Diagnose 0;
BA_ "GenSigSwitchedByIgnition" SG_ 253 ESP_Diagnose 0;
BA_ "GenSigSendType" SG_ 253 ESP_Eingriff 0;
BA_ "GenSigSwitchedByIgnition" SG_ 253 ESP_Eingriff 0;
BA_ "GenSigSendType" SG_ 253 ESP_QBit_v_Signal 0;
BA_ "GenSigStartValue" SG_ 253 ESP_QBit_v_Signal 1;
BA_ "GenSigSwitchedByIgnition" SG_ 253 ESP_QBit_v_Signal 0;
BA_ "GenSigSendType" SG_ 253 ESP_Systemstatus 0;
BA_ "GenSigSwitchedByIgnition" SG_ 253 ESP_Systemstatus 0;
BA_ "GenSigSendType" SG_ 253 ESP_Tastung_passiv 0;
BA_ "GenSigSwitchedByIgnition" SG_ 253 ESP_Tastung_passiv 0;
BA_ "GenSigSendType" SG_ 253 ESP_v_Signal 0;
BA_ "GenSigStartValue" SG_ 253 ESP_v_Signal 65534;
BA_ "GenSigSwitchedByIgnition" SG_ 253 ESP_v_Signal 0;
BA_ "Fehlerwert" SG_ 253 ESP_v_Signal 65535;
BA_ "GenSigMissingSourceValue" SG_ 253 ESP_v_Signal 65534;
BA_ "GenSigSendType" SG_ 253 ESP_Vorsteuerung 0;
BA_ "GenSigSwitchedByIgnition" SG_ 253 ESP_Vorsteuerung 0;
BA_ "GenSigSendType" SG_ 253 MSR_Anf 0;
BA_ "GenSigSwitchedByIgnition" SG_ 253 MSR_Anf 0;
BA_ "GenSigSendType" SG_ 253 OBD_QBit_Schlechtweg 0;
BA_ "GenSigStartValue" SG_ 253 OBD_QBit_Schlechtweg 1;
BA_ "GenSigSwitchedByIgnition" SG_ 253 OBD_QBit_Schlechtweg 0;
BA_ "GenSigSendType" SG_ 253 OBD_Schlechtweg 0;
BA_ "GenSigSwitchedByIgnition" SG_ 253 OBD_Schlechtweg 0;
BA_ "GenSigSendType" SG_ 2463978667 ESC_Anf_Mindestreku 3;
BA_ "GenSigSwitchedByIgnition" SG_ 2463978667 ESC_Anf_Mindestreku 0;
BA_ "GenSigSendType" SG_ 2463978667 ESC_Status_Schaltkennfeld_sek 0;
BA_ "GenSigSwitchedByIgnition" SG_ 2463978667 ESC_Status_Schaltkennfeld_sek 0;
BA_ "GenSigSendType" SG_ 2463978667 ESCGeneratorSollMoment 0;
BA_ "GenSigStartValue" SG_ 2463978667 ESCGeneratorSollMoment 4094;
BA_ "GenSigSwitchedByIgnition" SG_ 2463978667 ESCGeneratorSollMoment 0;
BA_ "Fehlerwert" SG_ 2463978667 ESCGeneratorSollMoment 4095;
BA_ "GenSigSendType" SG_ 2463978667 ESP_25_BZ 0;
BA_ "GenSigFuncType" SG_ 2463978667 ESP_25_BZ 1;
BA_ "GenSigSwitchedByIgnition" SG_ 2463978667 ESP_25_BZ 0;
BA_ "GenSigSendType" SG_ 2463978667 ESP_25_CRC 0;
BA_ "GenSigFuncType" SG_ 2463978667 ESP_25_CRC 2;
BA_ "GenSigSwitchedByIgnition" SG_ 2463978667 ESP_25_CRC 0;
BA_ "GenSigSendType" SG_ 2463978667 ESP_M_hyd_anteil_Bremse 0;
BA_ "GenSigStartValue" SG_ 2463978667 ESP_M_hyd_anteil_Bremse 4094;
BA_ "GenSigSwitchedByIgnition" SG_ 2463978667 ESP_M_hyd_anteil_Bremse 0;
BA_ "Fehlerwert" SG_ 2463978667 ESP_M_hyd_anteil_Bremse 4095;
BA_ "GenSigSendType" SG_ 2463978667 TSMomBegrenzung 0;
BA_ "GenSigStartValue" SG_ 2463978667 TSMomBegrenzung 4094;
BA_ "GenSigSwitchedByIgnition" SG_ 2463978667 TSMomBegrenzung 0;
BA_ "Fehlerwert" SG_ 2463978667 TSMomBegrenzung 4095;
BA_REL_ "GenSigTimeoutTime" BU_SG_REL_ AWC SG_ 1714 DGN_Verlernzaehler 5000;
BA_REL_ "GenSigTimeoutTime" BU_SG_REL_ AWC SG_ 1714 KBI_Kilometerstand 5000;
BA_REL_ "GenSigTimeoutTime" BU_SG_REL_ AWC SG_ 1714 UH_Jahr 5000;
BA_REL_ "GenSigTimeoutTime" BU_SG_REL_ AWC SG_ 1714 UH_Monat 5000;
BA_REL_ "GenSigTimeoutTime" BU_SG_REL_ AWC SG_ 1714 UH_Tag 5000;
BA_REL_ "GenSigTimeoutTime" BU_SG_REL_ AWC SG_ 1714 UH_Stunde 5000;
BA_REL_ "GenSigTimeoutTime" BU_SG_REL_ AWC SG_ 1714 UH_Minute 5000;
BA_REL_ "GenSigTimeoutTime" BU_SG_REL_ AWC SG_ 1714 UH_Sekunde 5000;
BA_REL_ "GenSigTimeoutTime" BU_SG_REL_ AWC SG_ 278 ESP_QBit_Wegimpuls_VL 1000;
BA_REL_ "GenSigTimeoutTime" BU_SG_REL_ AWC SG_ 278 ESP_QBit_Wegimpuls_VR 1000;
BA_REL_ "GenSigTimeoutTime" BU_SG_REL_ AWC SG_ 278 ESP_QBit_Wegimpuls_HL 1000;
BA_REL_ "GenSigTimeoutTime" BU_SG_REL_ AWC SG_ 278 ESP_QBit_Wegimpuls_HR 1000;
BA_REL_ "GenSigTimeoutTime" BU_SG_REL_ AWC SG_ 278 ESP_Wegimpuls_VL 1000;
BA_REL_ "GenSigTimeoutTime" BU_SG_REL_ AWC SG_ 278 ESP_Wegimpuls_VR 1000;
BA_REL_ "GenSigTimeoutTime" BU_SG_REL_ AWC SG_ 278 ESP_Wegimpuls_HL 1000;
BA_REL_ "GenSigTimeoutTime" BU_SG_REL_ AWC SG_ 278 ESP_Wegimpuls_HR 1000;
BA_REL_ "GenSigTimeoutTime" BU_SG_REL_ AWC SG_ 278 ESP_VL_Fahrtrichtung 1000;
BA_REL_ "GenSigTimeoutTime" BU_SG_REL_ AWC SG_ 278 ESP_VR_Fahrtrichtung 1000;
BA_REL_ "GenSigTimeoutTime" BU_SG_REL_ AWC SG_ 278 ESP_HL_Fahrtrichtung 1000;
BA_REL_ "GenSigTimeoutTime" BU_SG_REL_ AWC SG_ 278 ESP_HR_Fahrtrichtung 1000;
BA_REL_ "GenSigTimeoutTime" BU_SG_REL_ AWC SG_ 1629 BR_QBit_Reifenumfang 5000;
BA_REL_ "GenSigTimeoutTime" BU_SG_REL_ AWC SG_ 1629 BR_Reifenumfang 5000;
BA_REL_ "GenSigTimeoutTime" BU_SG_REL_ AWC SG_ 253 ESP_v_Signal 500;
BA_REL_ "GenSigTimeoutTime" BU_SG_REL_ AWC SG_ 253 ESP_QBit_v_Signal 500;
BA_REL_ "GenSigTimeoutTime" BU_SG_REL_ BMC_MLBevo SG_ 1714 KBI_Kilometerstand 5000;
BA_REL_ "GenSigTimeoutTime" BU_SG_REL_ BMC_MLBevo SG_ 1714 UH_Jahr 5000;
BA_REL_ "GenSigTimeoutTime" BU_SG_REL_ BMC_MLBevo SG_ 1714 UH_Monat 5000;
BA_REL_ "GenSigTimeoutTime" BU_SG_REL_ BMC_MLBevo SG_ 1714 UH_Tag 5000;
BA_REL_ "GenSigTimeoutTime" BU_SG_REL_ BMC_MLBevo SG_ 1714 UH_Stunde 5000;
BA_REL_ "GenSigTimeoutTime" BU_SG_REL_ BMC_MLBevo SG_ 1714 UH_Minute 5000;
BA_REL_ "GenSigTimeoutTime" BU_SG_REL_ BMC_MLBevo SG_ 1714 UH_Sekunde 5000;
BA_REL_ "GenSigTimeoutTime" BU_SG_REL_ BMC_MLBevo SG_ 2527679504 EM1_IstDrehzahl_02 3200;
BA_REL_ "GenSigTimeoutTime" BU_SG_REL_ BMC_MLBevo SG_ 892 EM1_Istmodus2 4800;
BA_REL_ "GenSigTimeoutTime" BU_SG_REL_ BMC_MLBevo SG_ 253 ESP_v_Signal 500;
BA_REL_ "GenSigTimeoutTime" BU_SG_REL_ BMS_MV SG_ 1714 DGN_Verlernzaehler 5000;
BA_REL_ "GenSigTimeoutTime" BU_SG_REL_ BMS_MV SG_ 1714 KBI_Kilometerstand 5000;
BA_REL_ "GenSigTimeoutTime" BU_SG_REL_ BMS_MV SG_ 1714 UH_Jahr 5000;
BA_REL_ "GenSigTimeoutTime" BU_SG_REL_ BMS_MV SG_ 1714 UH_Monat 5000;
BA_REL_ "GenSigTimeoutTime" BU_SG_REL_ BMS_MV SG_ 1714 UH_Tag 5000;
BA_REL_ "GenSigTimeoutTime" BU_SG_REL_ BMS_MV SG_ 1714 UH_Stunde 5000;
BA_REL_ "GenSigTimeoutTime" BU_SG_REL_ BMS_MV SG_ 1714 UH_Minute 5000;
BA_REL_ "GenSigTimeoutTime" BU_SG_REL_ BMS_MV SG_ 1714 UH_Sekunde 5000;
BA_REL_ "GenSigTimeoutTime" BU_SG_REL_ BMS_MV SG_ 2589283600 EMG_CALID_CVN_MUX 5000;
BA_REL_ "GenSigTimeoutTime" BU_SG_REL_ BMS_MV SG_ 2589283600 EMG_CVN_VLD 5000;
BA_REL_ "GenSigTimeoutTime" BU_SG_REL_ BMS_MV SG_ 2589283600 EMG_CALID_Index_01 5000;
BA_REL_ "GenSigTimeoutTime" BU_SG_REL_ BMS_MV SG_ 2589283600 EMG_CALID_Index_05 5000;
BA_REL_ "GenSigTimeoutTime" BU_SG_REL_ BMS_MV SG_ 2589283600 EMG_CALID_Index_09 5000;
BA_REL_ "GenSigTimeoutTime" BU_SG_REL_ BMS_MV SG_ 2589283600 EMG_CALID_Index_13 5000;
BA_REL_ "GenSigTimeoutTime" BU_SG_REL_ BMS_MV SG_ 2589283600 EMG_CALID_Index_02 5000;
BA_REL_ "GenSigTimeoutTime" BU_SG_REL_ BMS_MV SG_ 2589283600 EMG_CALID_Index_06 5000;
BA_REL_ "GenSigTimeoutTime" BU_SG_REL_ BMS_MV SG_ 2589283600 EMG_CALID_Index_10 5000;
BA_REL_ "GenSigTimeoutTime" BU_SG_REL_ BMS_MV SG_ 2589283600 EMG_CALID_Index_14 5000;
BA_REL_ "GenSigTimeoutTime" BU_SG_REL_ BMS_MV SG_ 2589283600 EMG_CALID_Index_03 5000;
BA_REL_ "GenSigTimeoutTime" BU_SG_REL_ BMS_MV SG_ 2589283600 EMG_CALID_Index_07 5000;
BA_REL_ "GenSigTimeoutTime" BU_SG_REL_ BMS_MV SG_ 2589283600 EMG_CALID_Index_11 5000;
BA_REL_ "GenSigTimeoutTime" BU_SG_REL_ BMS_MV SG_ 2589283600 EMG_CALID_Index_15 5000;
BA_REL_ "GenSigTimeoutTime" BU_SG_REL_ BMS_MV SG_ 2589283600 EMG_CALID_Index_04 5000;
BA_REL_ "GenSigTimeoutTime" BU_SG_REL_ BMS_MV SG_ 2589283600 EMG_CALID_Index_08 5000;
BA_REL_ "GenSigTimeoutTime" BU_SG_REL_ BMS_MV SG_ 2589283600 EMG_CALID_Index_12 5000;
BA_REL_ "GenSigTimeoutTime" BU_SG_REL_ BMS_MV SG_ 2589283600 EMG_CALID_Index_16 5000;
BA_REL_ "GenSigTimeoutTime" BU_SG_REL_ BMS_MV SG_ 2589283600 EMG_CVN_Byte_1 5000;
BA_REL_ "GenSigTimeoutTime" BU_SG_REL_ BMS_MV SG_ 2589283600 EMG_CVN_Byte_2 5000;
BA_REL_ "GenSigTimeoutTime" BU_SG_REL_ BMS_MV SG_ 2589283600 EMG_CVN_Byte_3 5000;
BA_REL_ "GenSigTimeoutTime" BU_SG_REL_ BMS_MV SG_ 2589283600 EMG_CVN_Byte_4 5000;
BA_REL_ "GenSigTimeoutTime" BU_SG_REL_ BMS_MV SG_ 2589283495 EMG_Komponentenfehler_01 5000;
BA_REL_ "GenSigTimeoutTime" BU_SG_REL_ BMS_MV SG_ 2589283495 EMG_Komponentenfehler_02 5000;
BA_REL_ "GenSigTimeoutTime" BU_SG_REL_ BMS_MV SG_ 2589283495 EMG_Komponentenfehler_03 5000;
BA_REL_ "GenSigTimeoutTime" BU_SG_REL_ BMS_MV SG_ 2589283495 EMG_Komponentenfehler_04 5000;
BA_REL_ "GenSigTimeoutTime" BU_SG_REL_ BMS_MV SG_ 2589283495 EMG_Komponentenfehler_05 5000;
BA_REL_ "GenSigTimeoutTime" BU_SG_REL_ BMS_MV SG_ 2589283495 EMG_Komponentenfehler_06 5000;
BA_REL_ "GenSigTimeoutTime" BU_SG_REL_ BMS_MV SG_ 2589283495 EMG_Komponentenfehler_07 5000;
BA_REL_ "GenSigTimeoutTime" BU_SG_REL_ BMS_MV SG_ 2589283495 EMG_Komponentenfehler_08 5000;
BA_REL_ "GenSigTimeoutTime" BU_SG_REL_ BMS_MV SG_ 2589283495 EMG_Komponentenfehler_09 5000;
BA_REL_ "GenSigTimeoutTime" BU_SG_REL_ BMS_MV SG_ 2589283495 EMG_Komponentenfehler_VLD 5000;
BA_REL_ "GenSigTimeoutTime" BU_SG_REL_ BMS_MV SG_ 253 ESP_v_Signal 500;
BA_REL_ "GenSigTimeoutTime" BU_SG_REL_ BMS_NV SG_ 1714 DGN_Verlernzaehler 5000;
BA_REL_ "GenSigTimeoutTime" BU_SG_REL_ BMS_NV SG_ 1714 KBI_Kilometerstand 5000;
BA_REL_ "GenSigTimeoutTime" BU_SG_REL_ BMS_NV SG_ 1714 UH_Jahr 5000;
BA_REL_ "GenSigTimeoutTime" BU_SG_REL_ BMS_NV SG_ 1714 UH_Monat 5000;
BA_REL_ "GenSigTimeoutTime" BU_SG_REL_ BMS_NV SG_ 1714 UH_Tag 5000;
BA_REL_ "GenSigTimeoutTime" BU_SG_REL_ BMS_NV SG_ 1714 UH_Stunde 5000;
BA_REL_ "GenSigTimeoutTime" BU_SG_REL_ BMS_NV SG_ 1714 UH_Minute 5000;
BA_REL_ "GenSigTimeoutTime" BU_SG_REL_ BMS_NV SG_ 1714 UH_Sekunde 5000;
BA_REL_ "GenSigTimeoutTime" BU_SG_REL_ BMS_NV SG_ 253 ESP_v_Signal 500;
BA_REL_ "GenSigTimeoutTime" BU_SG_REL_ BMS_NV SG_ 253 ESP_QBit_v_Signal 500;
BA_REL_ "GenSigTimeoutTime" BU_SG_REL_ DCDC_800V_PAG SG_ 1714 DGN_Verlernzaehler 5000;
BA_REL_ "GenSigTimeoutTime" BU_SG_REL_ DCDC_800V_PAG SG_ 1714 KBI_Kilometerstand 5000;
BA_REL_ "GenSigTimeoutTime" BU_SG_REL_ DCDC_800V_PAG SG_ 1714 UH_Jahr 5000;
BA_REL_ "GenSigTimeoutTime" BU_SG_REL_ DCDC_800V_PAG SG_ 1714 UH_Monat 5000;
BA_REL_ "GenSigTimeoutTime" BU_SG_REL_ DCDC_800V_PAG SG_ 1714 UH_Tag 5000;
BA_REL_ "GenSigTimeoutTime" BU_SG_REL_ DCDC_800V_PAG SG_ 1714 UH_Stunde 5000;
BA_REL_ "GenSigTimeoutTime" BU_SG_REL_ DCDC_800V_PAG SG_ 1714 UH_Minute 5000;
BA_REL_ "GenSigTimeoutTime" BU_SG_REL_ DCDC_800V_PAG SG_ 1714 UH_Sekunde 5000;
BA_REL_ "GenSigTimeoutTime" BU_SG_REL_ DCDC_800V_PAG SG_ 253 ESP_v_Signal 500;
BA_REL_ "GenSigTimeoutTime" BU_SG_REL_ DCDC_HV SG_ 1714 DGN_Verlernzaehler 5000;
BA_REL_ "GenSigTimeoutTime" BU_SG_REL_ DCDC_HV SG_ 1714 KBI_Kilometerstand 5000;
BA_REL_ "GenSigTimeoutTime" BU_SG_REL_ DCDC_HV SG_ 1714 UH_Jahr 5000;
BA_REL_ "GenSigTimeoutTime" BU_SG_REL_ DCDC_HV SG_ 1714 UH_Monat 5000;
BA_REL_ "GenSigTimeoutTime" BU_SG_REL_ DCDC_HV SG_ 1714 UH_Tag 5000;
BA_REL_ "GenSigTimeoutTime" BU_SG_REL_ DCDC_HV SG_ 1714 UH_Stunde 5000;
BA_REL_ "GenSigTimeoutTime" BU_SG_REL_ DCDC_HV SG_ 1714 UH_Minute 5000;
BA_REL_ "GenSigTimeoutTime" BU_SG_REL_ DCDC_HV SG_ 1714 UH_Sekunde 5000;
BA_REL_ "GenSigTimeoutTime" BU_SG_REL_ DCDC_HV SG_ 253 ESP_v_Signal 500;
BA_REL_ "GenSigTimeoutTime" BU_SG_REL_ DCDC_HV_02 SG_ 1714 DGN_Verlernzaehler 5000;
BA_REL_ "GenSigTimeoutTime" BU_SG_REL_ DCDC_HV_02 SG_ 1714 KBI_Kilometerstand 5000;
BA_REL_ "GenSigTimeoutTime" BU_SG_REL_ DCDC_HV_02 SG_ 1714 UH_Jahr 5000;
BA_REL_ "GenSigTimeoutTime" BU_SG_REL_ DCDC_HV_02 SG_ 1714 UH_Monat 5000;
BA_REL_ "GenSigTimeoutTime" BU_SG_REL_ DCDC_HV_02 SG_ 1714 UH_Tag 5000;
BA_REL_ "GenSigTimeoutTime" BU_SG_REL_ DCDC_HV_02 SG_ 1714 UH_Stunde 5000;
BA_REL_ "GenSigTimeoutTime" BU_SG_REL_ DCDC_HV_02 SG_ 1714 UH_Minute 5000;
BA_REL_ "GenSigTimeoutTime" BU_SG_REL_ DCDC_HV_02 SG_ 1714 UH_Sekunde 5000;
BA_REL_ "GenSigTimeoutTime" BU_SG_REL_ DCDC_HV_02 SG_ 1714 Kombi_02_alt 5000;
BA_REL_ "GenSigTimeoutTime" BU_SG_REL_ DCDC_HV_02 SG_ 1714 Uhrzeit_01_alt 5000;
BA_REL_ "GenSigTimeoutTime" BU_SG_REL_ DCDC_HV_02 SG_ 253 ESP_v_Signal 500;
BA_REL_ "GenSigTimeoutTime" BU_SG_REL_ DCDC_IHEV SG_ 1714 DGN_Verlernzaehler 5000;
BA_REL_ "GenSigTimeoutTime" BU_SG_REL_ DCDC_IHEV SG_ 1714 KBI_Kilometerstand 5000;
BA_REL_ "GenSigTimeoutTime" BU_SG_REL_ DCDC_IHEV SG_ 1714 UH_Jahr 5000;
BA_REL_ "GenSigTimeoutTime" BU_SG_REL_ DCDC_IHEV SG_ 1714 UH_Monat 5000;
BA_REL_ "GenSigTimeoutTime" BU_SG_REL_ DCDC_IHEV SG_ 1714 UH_Tag 5000;
BA_REL_ "GenSigTimeoutTime" BU_SG_REL_ DCDC_IHEV SG_ 1714 UH_Stunde 5000;
BA_REL_ "GenSigTimeoutTime" BU_SG_REL_ DCDC_IHEV SG_ 1714 UH_Minute 5000;
BA_REL_ "GenSigTimeoutTime" BU_SG_REL_ DCDC_IHEV SG_ 1714 UH_Sekunde 5000;
BA_REL_ "GenSigTimeoutTime" BU_SG_REL_ DCDC_IHEV SG_ 253 ESP_v_Signal 500;
BA_REL_ "GenSigTimeoutTime" BU_SG_REL_ Gateway SG_ 892 EM1_HYB_11_CRC 4800;
BA_REL_ "GenSigTimeoutTime" BU_SG_REL_ Gateway SG_ 892 EM1_HYB_11_BZ 4800;
BA_REL_ "GenSigTimeoutTime" BU_SG_REL_ Gateway SG_ 892 EM1_Fehlerstatus 4800;
BA_REL_ "GenSigTimeoutTime" BU_SG_REL_ Gateway SG_ 892 EM1_Status_Spgfreiheit 4800;
BA_REL_ "GenSigTimeoutTime" BU_SG_REL_ Gateway SG_ 2463978615 EM2_HYB_11_CRC 4800;
BA_REL_ "GenSigTimeoutTime" BU_SG_REL_ Gateway SG_ 2463978615 EM2_HYB_11_BZ 4800;
BA_REL_ "GenSigTimeoutTime" BU_SG_REL_ Gateway SG_ 2463978615 EM2_Fehlerstatus 4800;
BA_REL_ "GenSigTimeoutTime" BU_SG_REL_ Gateway SG_ 2463978615 EM2_Status_Spgfreiheit 4800;
BA_REL_ "GenSigTimeoutTime" BU_SG_REL_ Gateway_PAG SG_ 892 EM1_HYB_11_CRC 4800;
BA_REL_ "GenSigTimeoutTime" BU_SG_REL_ Gateway_PAG SG_ 892 EM1_HYB_11_BZ 4800;
BA_REL_ "GenSigTimeoutTime" BU_SG_REL_ Gateway_PAG SG_ 892 EM1_Fehlerstatus 4800;
BA_REL_ "GenSigTimeoutTime" BU_SG_REL_ Gateway_PAG SG_ 892 EM1_Status_Spgfreiheit 4800;
BA_REL_ "GenSigTimeoutTime" BU_SG_REL_ Gateway_PAG SG_ 2463978615 EM2_HYB_11_CRC 4800;
BA_REL_ "GenSigTimeoutTime" BU_SG_REL_ Gateway_PAG SG_ 2463978615 EM2_HYB_11_BZ 4800;
BA_REL_ "GenSigTimeoutTime" BU_SG_REL_ Gateway_PAG SG_ 2463978615 EM2_Fehlerstatus 4800;
BA_REL_ "GenSigTimeoutTime" BU_SG_REL_ Gateway_PAG SG_ 2463978615 EM2_Status_Spgfreiheit 4800;
BA_REL_ "GenSigTimeoutTime" BU_SG_REL_ Ladegeraet_2 SG_ 1714 DGN_Verlernzaehler 5000;
BA_REL_ "GenSigTimeoutTime" BU_SG_REL_ Ladegeraet_2 SG_ 1714 KBI_Kilometerstand 5000;
BA_REL_ "GenSigTimeoutTime" BU_SG_REL_ Ladegeraet_2 SG_ 1714 UH_Jahr 5000;
BA_REL_ "GenSigTimeoutTime" BU_SG_REL_ Ladegeraet_2 SG_ 1714 UH_Monat 5000;
BA_REL_ "GenSigTimeoutTime" BU_SG_REL_ Ladegeraet_2 SG_ 1714 UH_Tag 5000;
BA_REL_ "GenSigTimeoutTime" BU_SG_REL_ Ladegeraet_2 SG_ 1714 UH_Stunde 5000;
BA_REL_ "GenSigTimeoutTime" BU_SG_REL_ Ladegeraet_2 SG_ 1714 UH_Minute 5000;
BA_REL_ "GenSigTimeoutTime" BU_SG_REL_ Ladegeraet_2 SG_ 1714 UH_Sekunde 5000;
BA_REL_ "GenSigTimeoutTime" BU_SG_REL_ Ladegeraet_2 SG_ 1714 Kombi_02_alt 5000;
BA_REL_ "GenSigTimeoutTime" BU_SG_REL_ Ladegeraet_2 SG_ 1714 Uhrzeit_01_alt 5000;
BA_REL_ "GenSigTimeoutTime" BU_SG_REL_ Ladegeraet_2 SG_ 253 ESP_v_Signal 500;
BA_REL_ "GenSigTimeoutTime" BU_SG_REL_ Ladegeraet_2 SG_ 253 ESP_QBit_v_Signal 500;
BA_REL_ "GenSigTimeoutTime" BU_SG_REL_ Ladegeraet_Konzern SG_ 1714 DGN_Verlernzaehler 5000;
BA_REL_ "GenSigTimeoutTime" BU_SG_REL_ Ladegeraet_Konzern SG_ 1714 KBI_Kilometerstand 5000;
BA_REL_ "GenSigTimeoutTime" BU_SG_REL_ Ladegeraet_Konzern SG_ 1714 UH_Jahr 5000;
BA_REL_ "GenSigTimeoutTime" BU_SG_REL_ Ladegeraet_Konzern SG_ 1714 UH_Monat 5000;
BA_REL_ "GenSigTimeoutTime" BU_SG_REL_ Ladegeraet_Konzern SG_ 1714 UH_Tag 5000;
BA_REL_ "GenSigTimeoutTime" BU_SG_REL_ Ladegeraet_Konzern SG_ 1714 UH_Stunde 5000;
BA_REL_ "GenSigTimeoutTime" BU_SG_REL_ Ladegeraet_Konzern SG_ 1714 UH_Minute 5000;
BA_REL_ "GenSigTimeoutTime" BU_SG_REL_ Ladegeraet_Konzern SG_ 1714 UH_Sekunde 5000;
BA_REL_ "GenSigTimeoutTime" BU_SG_REL_ Ladegeraet_Konzern SG_ 1520 DI_KL_58xd 2000;
BA_REL_ "GenSigTimeoutTime" BU_SG_REL_ Ladegeraet_Konzern SG_ 1520 DI_KL_58xs 2000;
BA_REL_ "GenSigTimeoutTime" BU_SG_REL_ Ladegeraet_Konzern SG_ 1520 DI_KL_58xt 2000;
BA_REL_ "GenSigTimeoutTime" BU_SG_REL_ Ladegeraet_Konzern SG_ 1603 KBI_Einheit_Streckenanz 5000;
BA_REL_ "GenSigTimeoutTime" BU_SG_REL_ Ladegeraet_Konzern SG_ 1603 KBI_Einheit_Uhrzeit 5000;
BA_REL_ "GenSigTimeoutTime" BU_SG_REL_ Ladegeraet_Konzern SG_ 892 EM1_Istmodus2 4800;
BA_REL_ "GenSigTimeoutTime" BU_SG_REL_ Ladegeraet_Konzern SG_ 418 HMS_Systemstatus 2000;
BA_REL_ "GenSigTimeoutTime" BU_SG_REL_ Ladegeraet_Konzern SG_ 418 HMS_aktives_System 2000;
BA_REL_ "GenSigTimeoutTime" BU_SG_REL_ Ladegeraet_Konzern SG_ 418 HMS_Konsistenz_HVLM 2000;
BA_REL_ "GenSigTimeoutTime" BU_SG_REL_ Ladegeraet_Konzern SG_ 418 HMS_Fehlerstatus 2000;
BA_REL_ "GenSigTimeoutTime" BU_SG_REL_ Ladegeraet_Konzern SG_ 253 ESP_v_Signal 500;
BA_REL_ "GenSigTimeoutTime" BU_SG_REL_ Ladegeraet_Konzern SG_ 253 ESP_QBit_v_Signal 500;
BA_REL_ "GenSigTimeoutTime" BU_SG_REL_ LE1 SG_ 1714 KBI_Kilometerstand 5000;
BA_REL_ "GenSigTimeoutTime" BU_SG_REL_ LE1 SG_ 1714 UH_Jahr 5000;
BA_REL_ "GenSigTimeoutTime" BU_SG_REL_ LE1 SG_ 1714 UH_Monat 5000;
BA_REL_ "GenSigTimeoutTime" BU_SG_REL_ LE1 SG_ 1714 UH_Tag 5000;
BA_REL_ "GenSigTimeoutTime" BU_SG_REL_ LE1 SG_ 1714 UH_Stunde 5000;
BA_REL_ "GenSigTimeoutTime" BU_SG_REL_ LE1 SG_ 1714 UH_Minute 5000;
BA_REL_ "GenSigTimeoutTime" BU_SG_REL_ LE1 SG_ 1714 UH_Sekunde 5000;
BA_REL_ "GenSigTimeoutTime" BU_SG_REL_ LE2 SG_ 1714 KBI_Kilometerstand 5000;
BA_REL_ "GenSigTimeoutTime" BU_SG_REL_ LE2 SG_ 1714 UH_Jahr 5000;
BA_REL_ "GenSigTimeoutTime" BU_SG_REL_ LE2 SG_ 1714 UH_Monat 5000;
BA_REL_ "GenSigTimeoutTime" BU_SG_REL_ LE2 SG_ 1714 UH_Tag 5000;
BA_REL_ "GenSigTimeoutTime" BU_SG_REL_ LE2 SG_ 1714 UH_Stunde 5000;
BA_REL_ "GenSigTimeoutTime" BU_SG_REL_ LE2 SG_ 1714 UH_Minute 5000;
BA_REL_ "GenSigTimeoutTime" BU_SG_REL_ LE2 SG_ 1714 UH_Sekunde 5000;
BA_REL_ "GenSigTimeoutTime" BU_SG_REL_ LE_MLBevo SG_ 1714 KBI_Kilometerstand 5000;
BA_REL_ "GenSigTimeoutTime" BU_SG_REL_ LE_MLBevo SG_ 1714 UH_Jahr 5000;
BA_REL_ "GenSigTimeoutTime" BU_SG_REL_ LE_MLBevo SG_ 1714 UH_Monat 5000;
BA_REL_ "GenSigTimeoutTime" BU_SG_REL_ LE_MLBevo SG_ 1714 UH_Tag 5000;
BA_REL_ "GenSigTimeoutTime" BU_SG_REL_ LE_MLBevo SG_ 1714 UH_Stunde 5000;
BA_REL_ "GenSigTimeoutTime" BU_SG_REL_ LE_MLBevo SG_ 1714 UH_Minute 5000;
BA_REL_ "GenSigTimeoutTime" BU_SG_REL_ LE_MLBevo SG_ 1714 UH_Sekunde 5000;
BA_REL_ "GenSigTimeoutTime" BU_SG_REL_ TME SG_ 1714 KBI_Kilometerstand 5000;
BA_REL_ "GenSigTimeoutTime" BU_SG_REL_ TME SG_ 1714 UH_Jahr 5000;
BA_REL_ "GenSigTimeoutTime" BU_SG_REL_ TME SG_ 1714 UH_Monat 5000;
BA_REL_ "GenSigTimeoutTime" BU_SG_REL_ TME SG_ 1714 UH_Tag 5000;
BA_REL_ "GenSigTimeoutTime" BU_SG_REL_ TME SG_ 1714 UH_Stunde 5000;
BA_REL_ "GenSigTimeoutTime" BU_SG_REL_ TME SG_ 1714 UH_Minute 5000;
BA_REL_ "GenSigTimeoutTime" BU_SG_REL_ TME SG_ 1714 UH_Sekunde 5000;
BA_REL_ "GenSigTimeoutTime" BU_SG_REL_ TME SG_ 1603 KBI_Einheit_Temp 5000;
BA_REL_ "GenSigTimeoutTime" BU_SG_REL_ TME SG_ 910 EM1_Temperatur_ElMotor 3200;
BA_REL_ "GenSigTimeoutTime" BU_SG_REL_ TME SG_ 910 EM1_Temperatur_PWR 3200;
BA_REL_ "GenSigTimeoutTime" BU_SG_REL_ TME SG_ 910 EM1_Temperatur_Rotor 3200;
BA_REL_ "GenSigTimeoutTime" BU_SG_REL_ TME SG_ 910 EM1_Verlustleistung_02 3200;
BA_REL_ "GenSigTimeoutTime" BU_SG_REL_ TME SG_ 2527679504 EM1_IstStrom 3200;
BA_REL_ "GenSigTimeoutTime" BU_SG_REL_ TME SG_ 2527679504 EM1_IstDrehzahl_02 3200;
BA_REL_ "GenSigTimeoutTime" BU_SG_REL_ TME SG_ 2527679504 EM1_IstMoment_02 3200;
BA_REL_ "GenSigTimeoutTime" BU_SG_REL_ TME SG_ 2527679504 EM1_Verlustleistung 3200;
BA_REL_ "GenSigTimeoutTime" BU_SG_REL_ TME SG_ 892 EM1_Istmodus2 4800;
BA_REL_ "GenSigTimeoutTime" BU_SG_REL_ TME SG_ 892 EM1_EM_SollVolumenstrom 4800;
BA_REL_ "GenSigTimeoutTime" BU_SG_REL_ TME SG_ 2527679648 EM2_Temperatur_ElMotor 3200;
BA_REL_ "GenSigTimeoutTime" BU_SG_REL_ TME SG_ 2527679648 EM2_Temperatur_PWR 3200;
BA_REL_ "GenSigTimeoutTime" BU_SG_REL_ TME SG_ 2527679648 EM2_Temperatur_Rotor 3200;
BA_REL_ "GenSigTimeoutTime" BU_SG_REL_ TME SG_ 2527679648 EM2_Verlustleistung_02 3200;
BA_REL_ "GenSigTimeoutTime" BU_SG_REL_ TME SG_ 2463978615 EM2_Istmodus2 4800;
BA_REL_ "GenSigTimeoutTime" BU_SG_REL_ TME SG_ 2463978615 EM2_EM_SollVolumenstrom 4800;
BA_REL_ "GenSigTimeoutTime" BU_SG_REL_ TME SG_ 2527679649 EM3_Temperatur_ElMotor 3200;
BA_REL_ "GenSigTimeoutTime" BU_SG_REL_ TME SG_ 2527679649 EM3_Temperatur_PWR 3200;
BA_REL_ "GenSigTimeoutTime" BU_SG_REL_ TME SG_ 2527679649 EM3_Temperatur_Rotor 3200;
BA_REL_ "GenSigTimeoutTime" BU_SG_REL_ TME SG_ 2527679649 EM3_Verlustleistung_02 3200;
BA_REL_ "GenSigTimeoutTime" BU_SG_REL_ TME SG_ 2463978616 EM3_Istmodus2 4800;
BA_REL_ "GenSigTimeoutTime" BU_SG_REL_ TME SG_ 2463978616 EM3_EM_SollVolumenstrom 4800;
BA_REL_ "GenSigTimeoutTime" BU_SG_REL_ TME SG_ 253 ESP_v_Signal 500;
BA_REL_ "GenSigTimeoutTime" BU_SG_REL_ TME SG_ 253 ESP_QBit_v_Signal 500;
BA_REL_ "GenSigTimeoutTime" BU_SG_REL_ TME SG_ 2463978667 ESC_Anf_Mindestreku 5000;
VAL_ 1714 DGN_Verlernzaehler 255 "ungültiger Zählerstand oder kein gültiger Fahrzyklus" ;
VAL_ 1714 KBI_Kilometerstand 1048574 "Init" 1048575 "Fehler" ;
VAL_ 1714 UH_Monat 0 "Init" 14 "reserviert" 15 "Fehler" ;
VAL_ 1714 UH_Tag 0 "Init" ;
VAL_ 1714 Kombi_02_alt 0 "aktuell" 1 "veraltet" ;
VAL_ 1714 Uhrzeit_01_alt 0 "aktuell" 1 "veraltet" ;
VAL_ 1520 DI_KL_58xd 254 "Init" 255 "Fehler" ;
VAL_ 1520 DI_KL_58xs 126 "Init" 127 "Fehler" ;
VAL_ 1520 DI_KL_58xt 126 "Init" 127 "Fehler" ;
VAL_ 1520 BCM1_Stellgroesse_Kl_58s 125 "Nicht_verbaut" 126 "Init" 127 "Fehler" ;
VAL_ 1603 KBI_Einheit_Datum 0 "Tag/Monat/Jahr" 1 "Monat/Tag/Jahr" 2 "Jahr/Monat/Tag" 3 "reserviert" ;
VAL_ 1603 KBI_Einheit_Druck 0 "Druckangabe in bar" 1 "Druckangabe in psi" 2 "Druckangabe in kPa" 3 "tbd." ;
VAL_ 1603 KBI_Einheit_Streckenanz 0 "Kilometer" 1 "Meilen" ;
VAL_ 1603 KBI_MFA_v_Einheit_02 0 "kmh" 1 "mph" ;
VAL_ 1603 KBI_Einheit_Temp 0 "Grad Celsius °C" 1 "Grad Fahrenheit °F" ;
VAL_ 1603 KBI_Einheit_Uhrzeit 0 "24h" 1 " 12h AM/PM" ;
VAL_ 1603 KBI_Einheit_Verbrauch 0 "mpg UK" 1 "mpg USA" 2 "Liter/100km" 3 "km/Liter" ;
VAL_ 1603 KBI_Einheit_Volumen 0 "Liter" 1 "Gallonen UK" 2 "Gallonen USA" 3 "reserviert" ;
VAL_ 1603 KBI_Einheit_Verbrauch_elektr 0 "kWh_pro_100km" 1 "km_pro_kWh" 2 "kWh_pro_100mls" 3 "mls_pro_kWh" 4 "MPGe" ;
VAL_ 1603 KBI_Einheit_Verbrauch_Gas 0 "kg_per_100km" 1 "km_per_kg" 2 "m3_per_100km" 3 "km_per_m3" 4 "miles_per_lbs" 5 "miles_per_yard3" 6 "miles_per_kg" 7 "miles_per_m3" 8 "miles_per_gallon_equivalent_US" ;
VAL_ 1603 KBI_Einheit_Masse 0 "kg" 1 "lbs" 2 "reserviert" ;
VAL_ 910 EM1_OBD_Lampe_Anf 0 "kein_MIL_Request" 1 "MIL_Request" ;
VAL_ 910 EM1_FoD_Freischaltstatus_Fkt1 0 "keine_FoD_Freischaltung" 1 "FoD_Freischaltung_PerformanzP" ;
VAL_ 910 EM1_Temperatur_ElMotor 254 "Init" 255 "Fehler" ;
VAL_ 910 EM1_Temperatur_PWR 254 "Init" 255 "Fehler" ;
VAL_ 910 EM1_Temperatur_Rotor 254 "Init" 255 "Fehler" ;
VAL_ 910 EM1_Verlustleistung_02 1022 "Init" 1023 "Fehler" ;
VAL_ 910 EM1_Temperatur_KW 254 "Init" 255 "Fehler" ;
VAL_ 2527679504 EM1_IstStrom 2046 "Init" 2047 "Fehler" ;
VAL_ 2527679504 EM1_IstDrehzahl_02 32766 "Init" 32767 "Fehler" ;
VAL_ 2527679504 EM1_IstMoment_02 4094 "Init" 4095 "Fehler" ;
VAL_ 2527679504 EM1_Verlustleistung 254 "Init" 255 "Fehler" ;
VAL_ 892 EM1_Istmodus2 0 "Standby" 1 "Momentenreg" 2 "Int_Drehzahlreg" 3 "Spannungsreg" 4 "Ext_Drehzahlreg" 5 "Inverter_Fehler" 6 "Kalibrierung" 8 "Freilauf" 15 "Initialisierung" ;
VAL_ 892 EM1_Fehlerstatus 0 "Komponente_IO" 1 "Eingeschr_KompFkt_Entlad_defekt" 2 "Eingeschr_KompFkt_Phasenabriss" 3 "Eingeschr_KompFkt_Interlock" 4 "Eingeschr_KompFkt_res" 6 "Keine_Komponentenfunktion" 7 "Init" ;
VAL_ 892 EM1_Status_Spgfreiheit 0 "Init" 1 "HV_Komponente_spannungsfrei" 2 "HV_Komp_nicht_spannungsfrei" 3 "Fehler_nicht_spannungsfrei" ;
VAL_ 892 EM1_HYB_11_Sendestatus 0 "EM1_HYB_11_wird_mit_500ms_gesendet" 1 "EM1_HYB_11_wird_mit_50ms_gesendet" ;
VAL_ 892 EM1_EM_SollVolumenstrom 62 "Init" 63 "Fehler" ;
VAL_ 2527679648 EM2_OBD_Lampe_Anf 0 "kein_MIL_Request" 1 "MIL_Request" ;
VAL_ 2527679648 EM2_FoD_Freischaltstatus_Fkt1 0 "keine_FoD_Freischaltung" 1 "FoD_Freischaltung_PerformanzP" ;
VAL_ 2527679648 EM2_Temperatur_ElMotor 254 "Init" 255 "Fehler" ;
VAL_ 2527679648 EM2_Temperatur_PWR 254 "Init" 255 "Fehler" ;
VAL_ 2527679648 EM2_Temperatur_Rotor 254 "Init" 255 "Fehler" ;
VAL_ 2527679648 EM2_Verlustleistung_02 1022 "Init" 1023 "Fehler" ;
VAL_ 2527679648 EM2_Temperatur_KW 254 "Init" 255 "Fehler" ;
VAL_ 2463978615 EM2_Istmodus2 0 "Standby" 1 "Momentenreg" 2 "Int_Drehzahlreg" 3 "Spannungsreg" 4 "Ext_Drehzahlreg" 5 "Inverter_Fehler" 6 "Kalibrierung" 8 "Freilauf" 15 "Initialisierung" ;
VAL_ 2463978615 EM2_Fehlerstatus 0 "Komponente_IO" 1 "Eingeschr_KompFkt_Entlad_defekt" 2 "Eingeschr_KompFkt_Phasenabriss" 3 "Eingeschr_KompFkt_Interlock" 4 "Eingeschr_KompFkt_res" 6 "Keine_Komponentenfunktion" 7 "Init" ;
VAL_ 2463978615 EM2_Status_Spgfreiheit 0 "Init" 1 "HV_Komponente_spannungsfrei" 2 "HV_Komp_nicht_spannungsfrei" 3 "Fehler_nicht_spannungsfrei" ;
VAL_ 2463978615 EM2_HYB_11_Sendestatus 0 "EM2_HYB_11_wird_mit_500ms_gesendet" 1 "EM2_HYB_11_wird_mit_50ms_gesendet" ;
VAL_ 2463978615 EM2_EM_SollVolumenstrom 62 "Init" 63 "Fehler" ;
VAL_ 2527679649 EM3_OBD_Lampe_Anf 0 "kein_MIL_Request" 1 "MIL_Request" ;
VAL_ 2527679649 EM3_FoD_Freischaltstatus_Fkt1 0 "keine_FoD_Freischaltung" 1 "FoD_Freischaltung_PerformanzP" ;
VAL_ 2527679649 EM3_Temperatur_ElMotor 254 "Init" 255 "Fehler" ;
VAL_ 2527679649 EM3_Temperatur_PWR 254 "Init" 255 "Fehler" ;
VAL_ 2527679649 EM3_Temperatur_Rotor 254 "Init" 255 "Fehler" ;
VAL_ 2527679649 EM3_Verlustleistung_02 1022 "Init" 1023 "Fehler" ;
VAL_ 2527679649 EM3_Temperatur_KW 254 "Init" 255 "Fehler" ;
VAL_ 2463978616 EM3_Istmodus2 0 "Standby" 1 "Momentenreg" 2 "Int_Drehzahlreg" 3 "Spannungsreg" 4 "Ext_Drehzahlreg" 5 "Inverter_Fehler" 6 "Kalibrierung" 8 "Freilauf" 10 "eTV_Modus" 15 "Initialisierung" ;
VAL_ 2463978616 EM3_Fehlerstatus 0 "Komponente_IO" 1 "Eingeschr_KompFkt_Entlad_defekt" 2 "Eingeschr_KompFkt_Phasenabriss" 3 "Eingeschr_KompFkt_Interlock" 4 "Eingeschr_KompFkt_res" 6 "Keine_Komponentenfunktion" 7 "Init" ;
VAL_ 2463978616 EM3_Status_Spgfreiheit 0 "Init" 1 "HV_Komponente_spannungsfrei" 2 "HV_Komp_nicht_spannungsfrei" 3 "Fehler_nicht_spannungsfrei" ;
VAL_ 2463978616 EM3_HYB_11_Sendestatus 0 "EM3_HYB_11_wird_mit_480ms_gesendet" 1 "EM3_HYB_11_wird_mit_40ms_gesendet" ;
VAL_ 2463978616 EM3_EM_SollVolumenstrom 62 "Init" 63 "Fehler" ;
VAL_ 2589283600 EMG_CVN_VLD 0 "ungueltig" 1 "gueltig" ;
VAL_ 2589283600 EMG_CALID_Index_01 48 "Init" ;
VAL_ 2589283600 EMG_CALID_Index_05 48 "Init" ;
VAL_ 2589283600 EMG_CALID_Index_09 48 "Init" ;
VAL_ 2589283600 EMG_CALID_Index_13 48 "Init" ;
VAL_ 2589283600 EMG_CALID_Index_02 48 "Init" ;
VAL_ 2589283600 EMG_CALID_Index_06 48 "Init" ;
VAL_ 2589283600 EMG_CALID_Index_10 48 "Init" ;
VAL_ 2589283600 EMG_CALID_Index_14 48 "Init" ;
VAL_ 2589283600 EMG_CALID_Index_03 48 "Init" ;
VAL_ 2589283600 EMG_CALID_Index_07 48 "Init" ;
VAL_ 2589283600 EMG_CALID_Index_11 48 "Init" ;
VAL_ 2589283600 EMG_CALID_Index_15 48 "Init" ;
VAL_ 2589283600 EMG_CALID_Index_04 48 "Init" ;
VAL_ 2589283600 EMG_CALID_Index_08 48 "Init" ;
VAL_ 2589283600 EMG_CALID_Index_12 48 "Init" ;
VAL_ 2589283600 EMG_CALID_Index_16 48 "Init" ;
VAL_ 2589283600 EMG_CVN_Byte_1 0 "Init" ;
VAL_ 2589283600 EMG_CVN_Byte_2 0 "Init" ;
VAL_ 2589283600 EMG_CVN_Byte_3 0 "Init" ;
VAL_ 2589283600 EMG_CVN_Byte_4 0 "Init" ;
VAL_ 2589283495 EMG_Komponentenfehler_01 0 "TestComplete_PASS" 1 "TestComplete_FAIL" 2 "TestNotComplete_PASS" ;
VAL_ 2589283495 EMG_Komponentenfehler_02 0 "TestComplete_PASS" 1 "TestComplete_FAIL" 2 "TestNotComplete_PASS" ;
VAL_ 2589283495 EMG_Komponentenfehler_03 0 "TestComplete_PASS" 1 "TestComplete_FAIL" 2 "TestNotComplete_PASS" ;
VAL_ 2589283495 EMG_Komponentenfehler_04 0 "TestComplete_PASS" 1 "TestComplete_FAIL" 2 "TestNotComplete_PASS" ;
VAL_ 2589283495 EMG_Komponentenfehler_05 0 "TestComplete_PASS" 1 "TestComplete_FAIL" 2 "TestNotComplete_PASS" ;
VAL_ 2589283495 EMG_Komponentenfehler_06 0 "TestComplete_PASS" 1 "TestComplete_FAIL" 2 "TestNotComplete_PASS" ;
VAL_ 2589283495 EMG_Komponentenfehler_07 0 "TestComplete_PASS" 1 "TestComplete_FAIL" 2 "TestNotComplete_PASS" ;
VAL_ 2589283495 EMG_Komponentenfehler_08 0 "TestComplete_PASS" 1 "TestComplete_FAIL" 2 "TestNotComplete_PASS" ;
VAL_ 2589283495 EMG_Komponentenfehler_09 0 "TestComplete_PASS" 1 "TestComplete_FAIL" 2 "TestNotComplete_PASS" ;
VAL_ 2589283495 EMG_Komponentenfehler_VLD 0 "ungueltig" 1 "gueltig" ;
VAL_ 278 ESP_QBit_Wegimpuls_VL 0 "gueltiger_Wert" 1 "Ersatz_Init_oder_Fehlerwert" ;
VAL_ 278 ESP_QBit_Wegimpuls_VR 0 "gueltiger_Wert" 1 "Ersatz_Init_oder_Fehlerwert" ;
VAL_ 278 ESP_QBit_Wegimpuls_HL 0 "gueltiger_Wert" 1 "Ersatz_Init_oder_Fehlerwert" ;
VAL_ 278 ESP_QBit_Wegimpuls_HR 0 "gueltiger_Wert" 1 "Ersatz_Init_oder_Fehlerwert" ;
VAL_ 278 ESP_Wegimpuls_VL 1021 "Init" 1022 "Unterspannung" 1023 "Fehler" ;
VAL_ 278 ESP_Wegimpuls_VR 1021 "Init" 1022 "Unterspannung" 1023 "Fehler" ;
VAL_ 278 ESP_Wegimpuls_HL 1021 "Init" 1022 "Unterspannung" 1023 "Fehler" ;
VAL_ 278 ESP_Wegimpuls_HR 1021 "Init" 1022 "Unterspannung" 1023 "Fehler" ;
VAL_ 278 ESP_VL_Fahrtrichtung 0 "Vorwaerts" 1 "Rueckwaerts" 2 "Init" 3 "ungueltig_oder_nicht_verbaut" ;
VAL_ 278 ESP_VR_Fahrtrichtung 0 "Vorwaerts" 1 "Rueckwaerts" 2 "Init" 3 "ungueltig_oder_nicht_verbaut" ;
VAL_ 278 ESP_HL_Fahrtrichtung 0 "Vorwaerts" 1 "Rueckwaerts" 2 "Init" 3 "ungueltig_oder_nicht_verbaut" ;
VAL_ 278 ESP_HR_Fahrtrichtung 0 "Vorwaerts" 1 "Rueckwaerts" 2 "Init" 3 "ungueltig_oder_nicht_verbaut" ;
VAL_ 418 HMS_P_beibehalten_GE 0 "P_nicht_beibehalten" 1 "P_beibehalten" 2 "Init" 3 "Fehler" ;
VAL_ 418 HMS_Konsistenz_GE 0 "kein_Fehler_erkannt" 1 "Fehler_erkannt" ;
VAL_ 418 HMS_Konsistenz_IPA 0 "kein_Fehler_erkannt" 1 "Fehler_erkannt" ;
VAL_ 418 HMS_Konsistenz_STA 0 "kein_Fehler_erkannt" 1 "Fehler_erkannt" ;
VAL_ 418 HMS_Konsistenz_MO 0 "kein_Fehler_erkannt" 1 "Fehler_erkannt" ;
VAL_ 418 HMS_halten_nicht_verfuegbar 0 "verfuegbar" 1 "nicht_verfuegbar" ;
VAL_ 418 NL_PRIM_STP_01_Status 0 "Notlauf_inaktiv" 1 "Notlauf_bereit" 2 "Notlauf_aktiv" 3 "Notlauf_nicht_verfuegbar" ;
VAL_ 418 VMM_Warnblinken 0 "Aus" 1 "An" ;
VAL_ 418 VZM_Status 0 "Initialisierung" 1 "Verfuegbar" 2 "Verfuegbar_mit_eingeschraenkter_Performance" 3 "Nicht_Verfuegbar" 4 "Fehler" ;
VAL_ 418 HMS_Notstopp_Status 0 "Off_Init" 1 "Inaktiv" 2 "Ready" 3 "Aktiv" 4 "Pending" 7 "nicht_Verfuegbar" ;
VAL_ 418 HMS_parken_nicht_verfuegbar 0 "verfuegbar" 1 "nicht_verfuegbar" ;
VAL_ 418 HMS_Anforderung_GE 0 "keine_Anforderung" 1 "P_einlegen" ;
VAL_ 418 HMS_Systemstatus 0 "keine_Funktion_aktiv" 1 "Halten_aktiv" 2 "Parken_angefordert" 3 "Parken_aktiv" 4 "Parken_beibehalten_aktiv" 5 "Anfahren_aktiv" 6 "Loeseanforderung_aktiv" 7 "Loeseanforderung_durch_Fahrer" 8 "Abrutschen_erkannt" 9 "Halten_Standby_aktiv" 10 "Anfahren_Standby_aktiv" 14 "Init" 15 "Fehler" ;
VAL_ 418 HMS_Stillstand 0 "kein_Stillstand" 1 "Stillstand_frueh" 2 "Stillstand" 6 "Init" 7 "Fehler" ;
VAL_ 418 HMS_aktives_System 0 "kein_System__Init_Fehler" 1 "Fahreranforderung_aktiv" 2 "HMS_intern_aktiv" 3 "ACC_aktiv" 4 "Autohold_aktiv" 5 "HHC_aktiv" 6 "HVLM_aktiv" 7 "Getriebe_aktiv" 8 "EBKV_aktiv" 9 "IPA_aktiv" 10 "ARA_aktiv" 12 "autonomous_Hold_aktiv" 13 "STA_aktiv" 14 "Motor_aktiv" 15 "EA_aktiv" ;
VAL_ 418 HMS_Konsistenz_HVLM 0 "kein_Fehler_erkannt" 1 "Fehler_erkannt" ;
VAL_ 418 HMS_Konsistenz_ACC 0 "kein_Fehler_erkannt" 1 "Fehler_erkannt" ;
VAL_ 418 HMS_Fehlerstatus 0 "kein_Fehler" 1 "Halten_nicht_moeglich" 2 "Sonderbetriebsmodus_aktiv" 3 "Systemeinschraenkung" 4 "Systemstoerung" ;
VAL_ 418 ESP_Index_Haltemoment 0 "Bremsmoment" 1 "Antriebsmoment" ;
VAL_ 418 ESP_Haltemoment 1022 "Init" 1023 "Fehler" ;
VAL_ 1629 BR_Systemart 0 "ABS" 1 "ABS_ASR" 2 "ESP" 3 "ESP_mit_integrierter_EPB" ;
VAL_ 1629 ESP_SpannungsAnf_02 0 "keine_Anforderung" 1 "Anforderung_Stufe1" 2 "Anforderung_Stufe2" 3 "Anforderung_Stufe3" ;
VAL_ 1629 ESP_Charisma_FahrPr 0 "keine_Funktion" 1 "Programm_1" 2 "Programm_2" 3 "Programm_3" 4 "Programm_4" 5 "Programm_5" 6 "Programm_6" 7 "Programm_7" 8 "Programm_8" 9 "Programm_9" 10 "Programm_10" 11 "Programm_11" 12 "Programm_12" 13 "Programm_13" 14 "Programm_14" 15 "Programm_15" ;
VAL_ 1629 ESP_Charisma_Status 0 "Init" 1 "verfuegbar" 2 "nicht_verfuegbar" 3 "asynchron_durch_Fahrerwunsch" ;
VAL_ 1629 ESP_Wiederstart_Anz_01 0 "keine_Anzeige" 1 "Rueckwaertsrollen" ;
VAL_ 1629 ESP_Wiederstart_Anz_02 0 "keine_Anzeige" 1 "Autohold_Rutschen" ;
VAL_ 1629 ESP_Wiederstart_Anz_03 0 "keine_Anzeige" 1 "Offroad_HDC" ;
VAL_ 1629 ESP_Wiederstart_Anz_04 0 "keine_Anzeige" 1 "ESC_Off" ;
VAL_ 1629 ESP_Stoppverbot_Anz_01 0 "keine_Anzeige" 1 "Notbremsung_aktiv" ;
VAL_ 1629 ESP_Stoppverbot_Anz_02 0 "keine_Anzeige" 1 "Autohold_AVH_Rutschen" ;
VAL_ 1629 ESP_Stoppverbot_Anz_03 0 "keine_Anzeige" 1 "Rueckwaertsrollen" ;
VAL_ 1629 ESP_Stoppverbot_Anz_04 0 "keine_Anzeige" 1 "ESP_Pumpenlauf" ;
VAL_ 1629 ESP_Stoppverbot_Anz_05 0 "keine_Anzeige" 1 "ESP_OFF" ;
VAL_ 1629 ESP_Stoppverbot_Anz_06 0 "keine_Anzeige" 1 "Offroad_HDC" ;
VAL_ 1629 ESP_Stoppverbot_Anz_07 0 "keine_Anzeige" 1 "ESP_Haltefunktion_nicht_verfuegbar" ;
VAL_ 1629 ESP_Stoppverbot_Anz_Std 0 "keine_Anzeige" 1 "Standard_Stoppvetogrund" ;
VAL_ 1629 ESP_Dachrelingsensor 0 "Sensor_nicht_verbaut" 1 "Quertraeger_montiert" 2 "Quertraeger_nicht_montiert" 3 "Fehler" ;
VAL_ 1629 ESP_Stoppverbot_Anz_08 0 "keine_Anzeige" 1 "Neigungsbegrenzung" ;
VAL_ 1629 HDC_Charisma_FahrPr 0 "keine_Funktion" 1 "Programm_1" 2 "Programm_2" 3 "Programm_3" 4 "Programm_4" 5 "Programm_5" 6 "Programm_6" 7 "Programm_7" 8 "Programm_8" 9 "Programm_9" 10 "Programm_10" 11 "Programm_11" 12 "Programm_12" 13 "Programm_13" 14 "Programm_14" 15 "Programm_15" ;
VAL_ 1629 HDC_Charisma_Status 0 "Init" 1 "verfuegbar" 2 "nicht_verfuegbar" 3 "asynchron_durch_Fahrerwunsch" ;
VAL_ 1629 BR_QBit_Reifenumfang 0 "gueltiger_Wert" 1 "Ersatz_Init_oder_Fehlerwert" ;
VAL_ 253 BR_Eingriffsmoment 1022 "Init" 1023 "Fehler" ;
VAL_ 253 ESP_Diagnose 0 "ESP_nicht_in_Diagnose" 1 "ESP_in_Diagnose" ;
VAL_ 253 ESC_v_Signal_Qualifier_High_Low 0 "Gueteschwelle_kleiner_1kmh" 1 "Gueteschwelle_kleiner_3kmh" 2 "Gueteschwelle_kleiner_5kmh" 3 "Gueteschwelle_kleiner_10kmh" 4 "Gueteschwelle_kleiner_20kmh" 5 "Gueteschwelle_groessergleich_20kmh" 6 "Init" 7 "Fehler" ;
VAL_ 253 ESP_Vorsteuerung 0 "keine_Vorsteuerung_aktiv" 1 "Vorsteuerung_aktiv" ;
VAL_ 253 OBD_Schlechtweg 0 "kein_Schlechtweg_erkannt" 1 "Schlechtweg_erkannt" ;
VAL_ 253 OBD_QBit_Schlechtweg 0 "gueltiger_Wert" 1 "Ersatz_Init_oder_Fehlerwert" ;
VAL_ 253 ESP_v_Signal 65533 "Unterspannung" 65534 "Init" 65535 "Fehler" ;
VAL_ 253 ASR_Tastung_passiv 0 "ASR_aktiviert" 1 "ASR_passiv_getastet_oder_Schwellen_geaendert" ;
VAL_ 253 ESP_Tastung_passiv 0 "ESP_aktiviert" 1 "ESP_passiv_getastet_oder_Schwellen_geaendert" ;
VAL_ 253 ESP_Systemstatus 0 "iO" 1 "Fehler" ;
VAL_ 253 ASR_Schalteingriff 0 "keine_Anforderung" 1 "ASR_Schaltkennfeld" 2 "Rueckschaltung" 3 "Schaltverbot" ;
VAL_ 253 ESP_QBit_v_Signal 0 "gueltiger_Wert" 1 "Ersatz_Init_oder_Fehlerwert" ;
VAL_ 253 ABS_Bremsung 0 "keine_ABS_Regelung" 1 "ABS_Regelung_aktiv" ;
VAL_ 253 ASR_Anf 0 "keine_Anforderung" 1 "ASR_Anforderung" ;
VAL_ 253 MSR_Anf 0 "keine Anfoderung" 1 "MSR-Anforderung" ;
VAL_ 253 EBV_Eingriff 0 "kein_EBV_Eingriff" 1 "EBV_Eingriff" ;
VAL_ 253 EDS_Eingriff 0 "kein_EDS_Eingriff" 1 "EDS_Eingriff" ;
VAL_ 253 ESP_Eingriff 0 "kein_ESP_Eingriff" 1 "ESP_Eingriff_aktiv" ;
VAL_ 253 ESP_ASP 0 "inaktiv" 1 "aktiv" ;
VAL_ 253 ESC_Neutralschaltung 0 "keine_Anforderung" 1 "Neutralschaltung_angefordert" ;
VAL_ 2463978667 ESCGeneratorSollMoment 4094 "Init" 4095 "Fehler" ;
VAL_ 2463978667 TSMomBegrenzung 4094 "Init" 4095 "Fehler" ;
VAL_ 2463978667 ESC_Anf_Mindestreku 0 "nicht_angefordert" 1 "angefordert" ;
VAL_ 2463978667 ESC_Status_Schaltkennfeld_sek 0 "keine Anforderung" 1 "ESC Schaltkennfeld" 2 "Schaltverbot" 3 "nicht belegt" ;
VAL_ 2463978667 ESP_M_hyd_anteil_Bremse 4094 "Init" 4095 "Fehler" ;
